VERSION "HNNBNNNYNNNNNNNNNNNNNNNNNNNNNNNNNNNNNNNNNN/4/%%%/4/'%**4NNN///"

NS_ :

BS_:

BU_: BAP_Tester ELV Gateway_Max HUD Kombi

BO_ 2331595982 Motor_64: 32 Gateway_Max
 SG_ PTUIPwrm_PrctPwrSysCur : 12|12@1+ (0.05,-102.3) [-102.30|102.35] "Unit_PerCent"  HUD,Kombi
 SG_ PTUIPwrm_PrctPwrElDrvCur : 24|12@1+ (0.05,-102.3) [-102.30|102.35] "Unit_PerCent"  HUD,Kombi
 SG_ PTHyDrA_StAcv : 36|2@1+ (1.0,0.0) [0.0|3] ""  HUD,Kombi
 SG_ PTUIPwrm_StAcv : 38|2@1+ (1.0,0.0) [0.0|3] ""  HUD,Kombi
 SG_ PTHyDrA_PrctUtilElDrv : 40|11@1+ (0.05,0) [0.00|102.25] "Unit_PerCent"  HUD,Kombi
 SG_ PTUIPwrm_PrctPwrGnrMaxUse : 51|11@1+ (0.05,-102.25) [-102.25|0.00] "Unit_PerCent"  HUD,Kombi
 SG_ PTUIPwrm_PrctPwrMotElMaxUse : 62|11@1+ (0.05,0) [0.00|102.25] "Unit_PerCent"  HUD,Kombi
 SG_ PTUIPwrm_FacPwrDyn : 73|7@1+ (0.01,0) [0.00|1.25] "Unit_None"  HUD,Kombi
 SG_ PTUIPwrm_PrctPwrMotMaxUse : 80|11@1+ (0.05,0) [0.00|102.25] "Unit_PerCent"  HUD,Kombi
 SG_ PTUIPwrm_PrctBoostAvl : 91|10@1+ (0.1,0) [0.0|102.1] "Unit_PerCent"  HUD,Kombi
 SG_ PTUIPwrm_PrctPwrElBoostCur : 101|10@1+ (0.1,0) [0.0|102.1] "Unit_PerCent"  HUD,Kombi
 SG_ PTUIPwrm_PrctPwrElBoostMaxUse : 111|10@1+ (0.1,0) [0.0|102.1] "Unit_PerCent"  HUD,Kombi
 SG_ PTUIPwrm_PwrElBoostNom : 121|10@1+ (1,0) [0|1021] "Unit_KiloWatt"  HUD,Kombi
 SG_ PTUIPwrm_PrctPwrEcoMaxUse : 142|11@1+ (0.05,0) [0.00|102.25] "Unit_PerCent"  Kombi
 SG_ PTUIPwrm_PrctPwrSysMaxUseTemp : 153|11@1+ (0.05,0) [0.00|102.25] "Unit_PerCent"  Kombi

BO_ 2589283946 Motor_65: 32 Gateway_Max
 SG_ PTUIPwrm_PwrMotElNom : 12|11@1+ (1,0) [0|2045] "Unit_KiloWatt"  HUD,Kombi
 SG_ PTUIPwrm_PwrGnrNom : 24|11@1+ (1,0) [0|2045] "Unit_KiloWatt"  HUD,Kombi
 SG_ PTUIPwrm_PwrSysMotNomDisp : 35|11@1+ (1,0) [0|2045] "Unit_KiloWatt"  Kombi

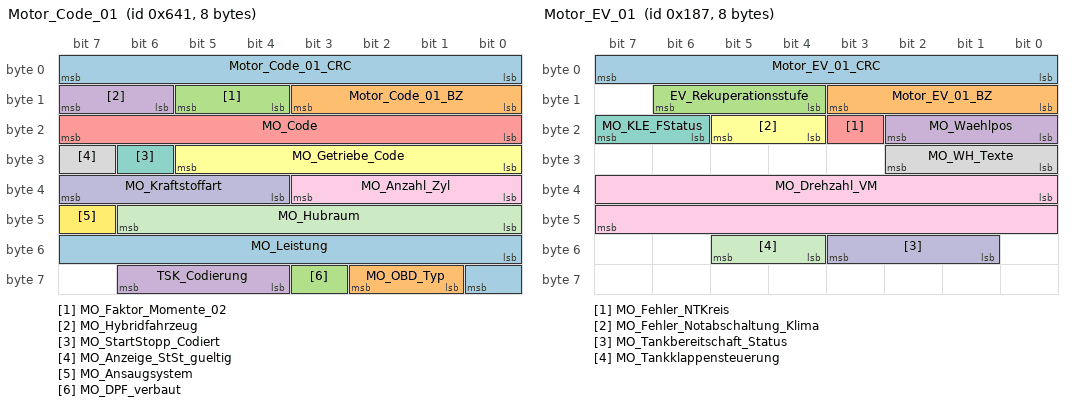
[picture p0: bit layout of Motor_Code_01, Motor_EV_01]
BO_ 1601 Motor_Code_01: 8 Gateway_Max
 SG_ Motor_Code_01_CRC : 0|8@1+ (1,0) [0|255] ""  Vector__XXX
 SG_ Motor_Code_01_BZ : 8|4@1+ (1,0) [0|15] ""  Vector__XXX
 SG_ MO_Faktor_Momente_02 : 12|2@1+ (1,0) [1|3] "Unit_NewtoMeter"  Vector__XXX
 SG_ MO_Hybridfahrzeug : 14|2@1+ (1.0,0.0) [0.0|3] ""  Kombi
 SG_ MO_Code : 16|8@1+ (1,0) [0|255] ""  Vector__XXX
 SG_ MO_Getriebe_Code : 24|6@1+ (1.0,0.0) [0.0|63] ""  Vector__XXX
 SG_ MO_StartStopp_Codiert : 30|1@1+ (1.0,0.0) [0.0|1] ""  Kombi
 SG_ MO_Anzeige_StSt_gueltig : 31|1@1+ (1.0,0.0) [0.0|1] ""  Kombi
 SG_ MO_Anzahl_Zyl : 32|4@1+ (1.0,0.0) [0.0|15] ""  Kombi
 SG_ MO_Kraftstoffart : 36|4@1+ (1.0,0.0) [0.0|15] ""  Kombi
 SG_ MO_Hubraum : 40|7@1+ (0.1,0) [0.0|12.7] "Unit_Liter"  Vector__XXX
 SG_ MO_Ansaugsystem : 47|1@1+ (1.0,0.0) [0.0|1] ""  Vector__XXX
 SG_ MO_Leistung : 48|9@1+ (1,0) [0|511] "Unit_KiloWatt"  Kombi
 SG_ MO_OBD_Typ : 57|2@1+ (1.0,0.0) [0.0|3] ""  Vector__XXX
 SG_ MO_DPF_verbaut : 59|1@1+ (1.0,0.0) [0.0|1] ""  Vector__XXX
 SG_ TSK_Codierung : 60|3@1+ (1.0,0.0) [0.0|7] ""  Vector__XXX

BO_ 391 Motor_EV_01: 8 Gateway_Max
 SG_ Motor_EV_01_CRC : 0|8@1+ (1,0) [0|255] ""  Vector__XXX
 SG_ Motor_EV_01_BZ : 8|4@1+ (1,0) [0|15] ""  Vector__XXX
 SG_ EV_Rekuperationsstufe : 12|3@1+ (1.0,0.0) [0.0|7] ""  Vector__XXX
 SG_ MO_Waehlpos : 16|3@1+ (1.0,0.0) [0.0|7] ""  Kombi
 SG_ MO_Fehler_NTKreis : 19|1@1+ (1.0,0.0) [0.0|1] ""  Vector__XXX
 SG_ MO_Fehler_Notabschaltung_Klima : 20|2@1+ (1.0,0.0) [0.0|3] ""  Vector__XXX
 SG_ MO_KLE_FStatus : 22|2@1+ (1.0,0.0) [0.0|3] ""  Vector__XXX
 SG_ MO_WH_Texte : 24|3@1+ (1.0,0.0) [0.0|7] ""  Vector__XXX
 SG_ MO_Drehzahl_VM : 32|16@1+ (0.25,0) [0.00|16383.00] "Unit_MinutInver"  Vector__XXX
 SG_ MO_Tankbereitschaft_Status : 49|3@1+ (1.0,0.0) [0.0|7] ""  Kombi
 SG_ MO_Tankklappensteuerung : 52|2@1+ (1.0,0.0) [0.0|3] ""  Vector__XXX

BO_ 813 Motor_Gas_01: 8 Gateway_Max
 SG_ MO_Fuellstand_LPG m1  : 0|10@1+ (0.125,0) [0.000|127.625] "Unit_Liter"  Kombi
 SG_ MO_CNG_LPG M  : 12|1@1+ (1.0,0.0) [0.0|1] ""  Kombi
 SG_ MO_CNG_Tankstopp m0  : 15|1@1+ (1.0,0.0) [0.0|1] ""  Kombi
 SG_ MO_LPG_Tankstopp m1  : 15|1@1+ (1.0,0.0) [0.0|1] ""  Kombi
 SG_ MO_AnzeigeGasbetrieb : 16|4@1+ (1.0,0.0) [0.0|15] ""  Kombi
 SG_ MO_akt_Betrieb : 20|1@1+ (1.0,0.0) [0.0|1] ""  Kombi
 SG_ MO_Erdgasqualitaet : 21|3@1+ (1.0,0.0) [0.0|7] ""  Kombi
 SG_ MO_Verbrauchsaequivalent : 24|8@1+ (0.008,0) [0.008|2.000] "Unit_None"  Kombi
 SG_ MO_Tankmasse_CNG m0  : 32|8@1+ (0.25,0) [0.25|63.50] "Unit_KiloGram"  Kombi
 SG_ MO_Tankvolumen_LPG m1  : 32|8@1+ (0.5,0) [0.5|127.0] "Unit_Liter"  Kombi
 SG_ MO_Fuellungsgrad_CNG m0  : 40|8@1+ (0.4,0) [0.0|101.2] "Unit_PerCent"  Kombi
 SG_ MO_Fuellungsgrad_LPG m1  : 40|8@1+ (0.4,0) [0.0|101.2] "Unit_PerCent"  Kombi
 SG_ MO_CNG_Ueberlauf m0  : 48|1@1+ (1.0,0.0) [0.0|1] ""  Kombi
 SG_ MO_LPG_Ueberlauf m1  : 48|1@1+ (1.0,0.0) [0.0|1] ""  Kombi
 SG_ MO_Verbrauch_CNG m0  : 49|15@1+ (1,0) [0|32767] "Unit_MilliGram"  Kombi
 SG_ MO_Verbrauch_LPG m1  : 49|15@1+ (1,0) [0|32767] "Unit_MicroLiter"  Kombi

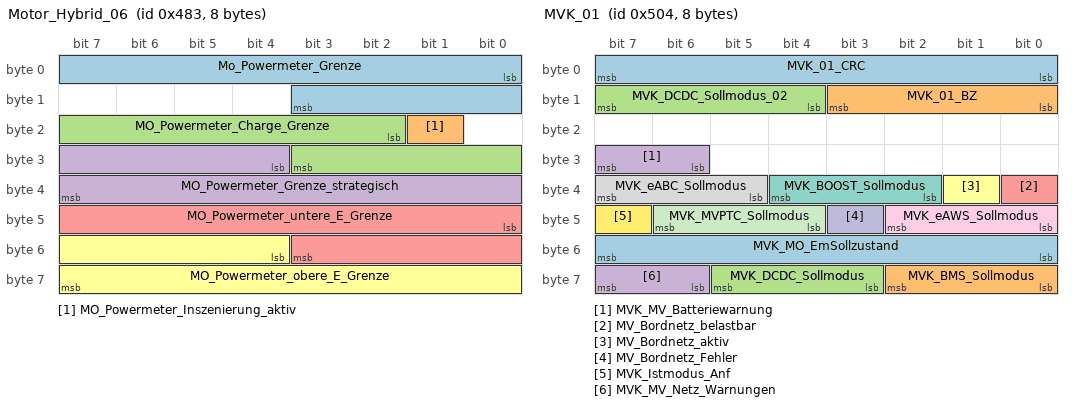
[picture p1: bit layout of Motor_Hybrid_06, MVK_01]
BO_ 1155 Motor_Hybrid_06: 8 Gateway_Max
 SG_ Mo_Powermeter_Grenze : 0|12@1+ (1,0) [0|4092] ""  Kombi
 SG_ MO_Powermeter_Inszenierung_aktiv : 17|1@1+ (1.0,0.0) [0.0|1] ""  Vector__XXX
 SG_ MO_Powermeter_Charge_Grenze : 18|10@1+ (1,0) [0|1021] "Unit_None"  Kombi
 SG_ MO_Powermeter_Grenze_strategisch : 28|12@1+ (1,0) [0|4093] "Unit_None"  Kombi
 SG_ MO_Powermeter_untere_E_Grenze : 40|12@1+ (1,0) [0|4093] "Unit_None"  Kombi
 SG_ MO_Powermeter_obere_E_Grenze : 52|12@1+ (1,0) [0|4093] "Unit_None"  Kombi

BO_ 1284 MVK_01: 8 Gateway_Max
 SG_ MVK_01_CRC : 0|8@1+ (1,0) [0|255] ""  Kombi
 SG_ MVK_01_BZ : 8|4@1+ (1,0) [0|15] ""  Kombi
 SG_ MVK_DCDC_Sollmodus_02 : 12|4@1+ (1.0,0.0) [0.0|15] ""  Vector__XXX
 SG_ MVK_MV_Batteriewarnung : 30|2@1+ (1.0,0.0) [0.0|3] ""  Kombi
 SG_ MV_Bordnetz_belastbar : 32|1@1+ (1.0,0.0) [0.0|1] ""  Vector__XXX
 SG_ MV_Bordnetz_aktiv : 33|1@1+ (1.0,0.0) [0.0|1] ""  Vector__XXX
 SG_ MVK_BOOST_Sollmodus : 34|3@1+ (1.0,0.0) [0.0|7] ""  Vector__XXX
 SG_ MVK_eABC_Sollmodus : 37|3@1+ (1.0,0.0) [0.0|7] ""  Vector__XXX
 SG_ MVK_eAWS_Sollmodus : 40|3@1+ (1.0,0.0) [0.0|7] ""  Vector__XXX
 SG_ MV_Bordnetz_Fehler : 43|1@1+ (1.0,0.0) [0.0|1] ""  Vector__XXX
 SG_ MVK_MVPTC_Sollmodus : 44|3@1+ (1.0,0.0) [0.0|7] ""  Vector__XXX
 SG_ MVK_Istmodus_Anf : 47|1@1+ (1.0,0.0) [0.0|1] ""  Vector__XXX
 SG_ MVK_MO_EmSollzustand : 48|8@1+ (1.0,0.0) [0.0|255] ""  Vector__XXX
 SG_ MVK_BMS_Sollmodus : 56|3@1+ (1.0,0.0) [0.0|7] ""  Vector__XXX
 SG_ MVK_DCDC_Sollmodus : 59|3@1+ (1.0,0.0) [0.0|7] ""  Vector__XXX
 SG_ MVK_MV_Netz_Warnungen : 62|2@1+ (1.0,0.0) [0.0|3] ""  Kombi

BO_ 2583737729 NAD_AuthTime_SSN_Req: 8 Gateway_Max
 SG_ NAD_AuthTime_SSN_Req_Data : 0|64@1+ (1.0,0.0) [0.0|18446744073709551615] ""  Kombi

BO_ 2583868801 NAD_AuthTime_SSN_Resp: 8 Kombi
 SG_ NAD_AuthTime_SSN_Resp_Data : 0|64@1+ (1.0,0.0) [0.0|18446744073709551615] ""  Gateway_Max

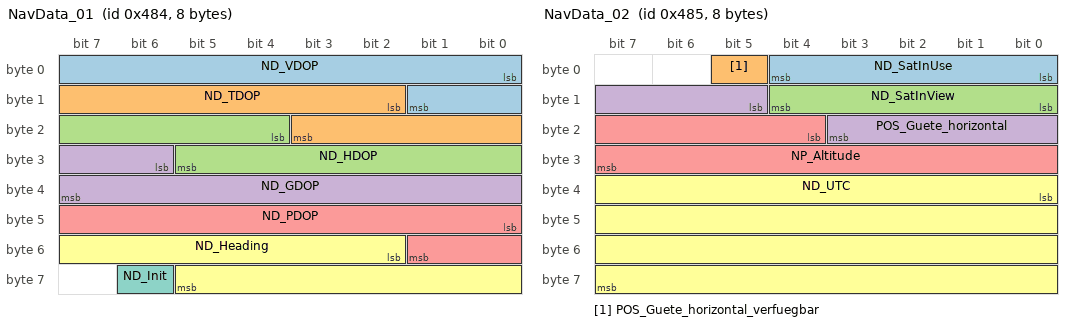
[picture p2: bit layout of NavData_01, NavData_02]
BO_ 1156 NavData_01: 8 Gateway_Max
 SG_ ND_VDOP : 0|10@1+ (0.025,0) [0.000|25.000] ""  Vector__XXX
 SG_ ND_TDOP : 10|10@1+ (0.025,0) [0.000|25.000] ""  Vector__XXX
 SG_ ND_HDOP : 20|10@1+ (0.025,0) [0.000|25.000] ""  Vector__XXX
 SG_ ND_GDOP : 30|10@1+ (0.025,0) [0.000|25.000] ""  Vector__XXX
 SG_ ND_PDOP : 40|10@1+ (0.025,0) [0.000|25.000] ""  Vector__XXX
 SG_ ND_Heading : 50|12@1+ (0.1,0) [0.0|359.9] "Unit_DegreOfArc"  Vector__XXX
 SG_ ND_Init : 62|1@1+ (1.0,0.0) [0.0|1] ""  Vector__XXX

BO_ 1157 NavData_02: 8 Gateway_Max
 SG_ ND_SatInUse : 0|5@1+ (1,0) [0|29] ""  Vector__XXX
 SG_ POS_Guete_horizontal_verfuegbar : 5|1@1+ (1.0,0.0) [0.0|1] ""  Vector__XXX
 SG_ ND_SatInView : 8|5@1+ (1,0) [0|29] ""  Vector__XXX
 SG_ POS_Guete_horizontal : 13|7@1+ (2,0) [0|246] "Unit_Meter"  Vector__XXX
 SG_ NP_Altitude : 20|12@1+ (2,-500) [-500|7686] "Unit_Meter"  Vector__XXX
 SG_ ND_UTC : 32|32@1+ (1,0) [0|4294967293] "Unit_Secon"  Vector__XXX

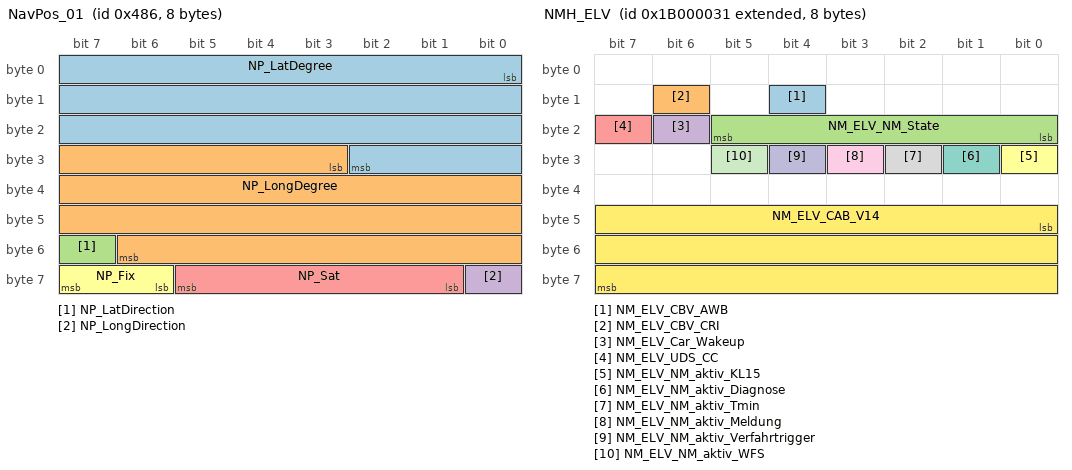
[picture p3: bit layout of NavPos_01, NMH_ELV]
BO_ 1158 NavPos_01: 8 Gateway_Max
 SG_ NP_LatDegree : 0|27@1+ (0.000001,0) [0.000000|90.000000] "Unit_DegreOfArc"  Vector__XXX
 SG_ NP_LongDegree : 27|28@1+ (0.000001,0) [0.000000|180.000000] "Unit_DegreOfArc"  Vector__XXX
 SG_ NP_LatDirection : 55|1@1+ (1.0,0.0) [0.0|1] ""  Vector__XXX
 SG_ NP_LongDirection : 56|1@1+ (1.0,0.0) [0.0|1] ""  Vector__XXX
 SG_ NP_Sat : 57|5@1+ (1,0) [0|29] ""  Vector__XXX
 SG_ NP_Fix : 62|2@1+ (1.0,0.0) [0.0|3] ""  Vector__XXX

BO_ 2600468529 NMH_ELV: 8 ELV
 SG_ NM_ELV_CBV_AWB : 12|1@1+ (1.0,0.0) [0.0|1] ""  Gateway_Max
 SG_ NM_ELV_CBV_CRI : 14|1@1+ (1.0,0.0) [0.0|1] ""  Gateway_Max
 SG_ NM_ELV_NM_State : 16|6@1+ (1.0,0.0) [0.0|63] ""  HUD,Kombi
 SG_ NM_ELV_Car_Wakeup : 22|1@1+ (1.0,0.0) [0.0|1] ""  Gateway_Max
 SG_ NM_ELV_UDS_CC : 23|1@1+ (1.0,0.0) [0.0|1] ""  Vector__XXX
 SG_ NM_ELV_NM_aktiv_KL15 : 24|1@1+ (1.0,0.0) [0.0|1] ""  Vector__XXX
 SG_ NM_ELV_NM_aktiv_Diagnose : 25|1@1+ (1.0,0.0) [0.0|1] ""  Vector__XXX
 SG_ NM_ELV_NM_aktiv_Tmin : 26|1@1+ (1.0,0.0) [0.0|1] ""  Vector__XXX
 SG_ NM_ELV_NM_aktiv_Meldung : 27|1@1+ (1.0,0.0) [0.0|1] ""  Vector__XXX
 SG_ NM_ELV_NM_aktiv_Verfahrtrigger : 28|1@1+ (1.0,0.0) [0.0|1] ""  Vector__XXX
 SG_ NM_ELV_NM_aktiv_WFS : 29|1@1+ (1.0,0.0) [0.0|1] ""  Vector__XXX
 SG_ NM_ELV_CAB_V14 : 40|24@1+ (1.0,0.0) [0.0|16777215] ""  Gateway_Max

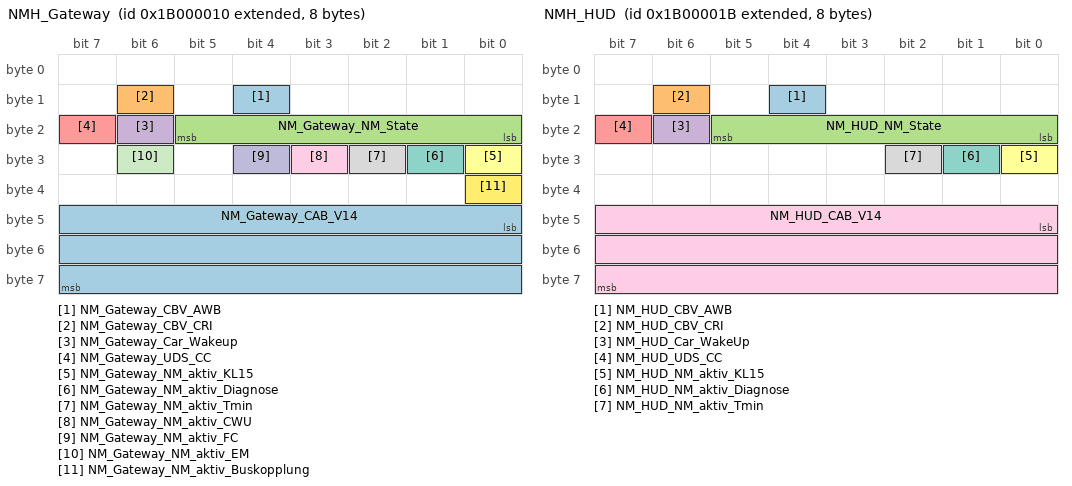
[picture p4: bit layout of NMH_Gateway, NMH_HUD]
BO_ 2600468496 NMH_Gateway: 8 Gateway_Max
 SG_ NM_Gateway_CBV_AWB : 12|1@1+ (1.0,0.0) [0.0|1] ""  Vector__XXX
 SG_ NM_Gateway_CBV_CRI : 14|1@1+ (1.0,0.0) [0.0|1] ""  Vector__XXX
 SG_ NM_Gateway_NM_State : 16|6@1+ (1.0,0.0) [0.0|63] ""  ELV,HUD,Kombi
 SG_ NM_Gateway_Car_Wakeup : 22|1@1+ (1.0,0.0) [0.0|1] ""  Vector__XXX
 SG_ NM_Gateway_UDS_CC : 23|1@1+ (1.0,0.0) [0.0|1] ""  Vector__XXX
 SG_ NM_Gateway_NM_aktiv_KL15 : 24|1@1+ (1.0,0.0) [0.0|1] ""  Vector__XXX
 SG_ NM_Gateway_NM_aktiv_Diagnose : 25|1@1+ (1.0,0.0) [0.0|1] ""  Vector__XXX
 SG_ NM_Gateway_NM_aktiv_Tmin : 26|1@1+ (1.0,0.0) [0.0|1] ""  Vector__XXX
 SG_ NM_Gateway_NM_aktiv_CWU : 27|1@1+ (1.0,0.0) [0.0|1] ""  Vector__XXX
 SG_ NM_Gateway_NM_aktiv_FC : 28|1@1+ (1.0,0.0) [0.0|1] ""  Vector__XXX
 SG_ NM_Gateway_NM_aktiv_EM : 30|1@1+ (1.0,0.0) [0.0|1] ""  Vector__XXX
 SG_ NM_Gateway_NM_aktiv_Buskopplung : 32|1@1+ (1.0,0.0) [0.0|1] ""  Vector__XXX
 SG_ NM_Gateway_CAB_V14 : 40|24@1+ (1.0,0.0) [0.0|16777215] ""  Vector__XXX

BO_ 2600468507 NMH_HUD: 8 HUD
 SG_ NM_HUD_CBV_AWB : 12|1@1+ (1.0,0.0) [0.0|1] ""  Gateway_Max
 SG_ NM_HUD_CBV_CRI : 14|1@1+ (1.0,0.0) [0.0|1] ""  Gateway_Max
 SG_ NM_HUD_NM_State : 16|6@1+ (1.0,0.0) [0.0|63] ""  ELV,Kombi
 SG_ NM_HUD_Car_WakeUp : 22|1@1+ (1.0,0.0) [0.0|1] ""  Gateway_Max
 SG_ NM_HUD_UDS_CC : 23|1@1+ (1.0,0.0) [0.0|1] ""  Vector__XXX
 SG_ NM_HUD_NM_aktiv_KL15 : 24|1@1+ (1.0,0.0) [0.0|1] ""  Vector__XXX
 SG_ NM_HUD_NM_aktiv_Diagnose : 25|1@1+ (1.0,0.0) [0.0|1] ""  Vector__XXX
 SG_ NM_HUD_NM_aktiv_Tmin : 26|1@1+ (1.0,0.0) [0.0|1] ""  Vector__XXX
 SG_ NM_HUD_CAB_V14 : 40|24@1+ (1.0,0.0) [0.0|16777215] ""  Gateway_Max

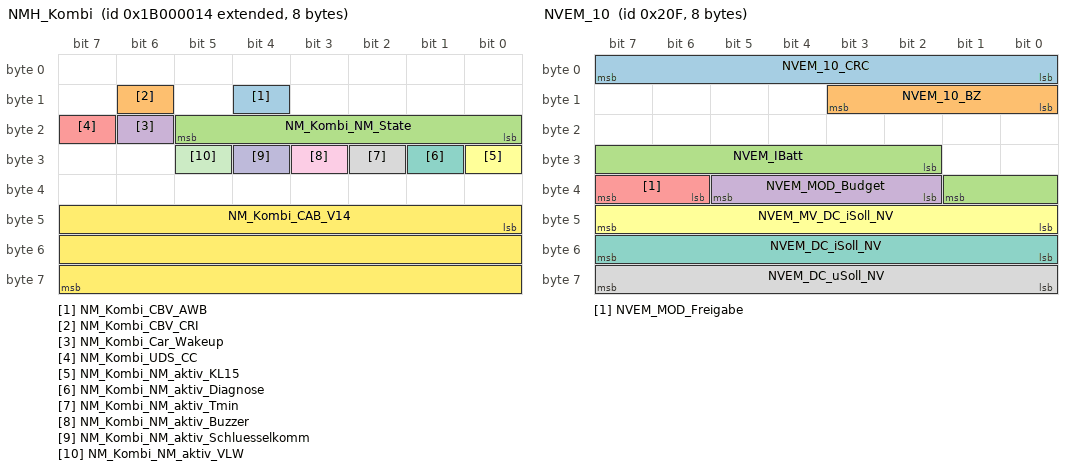
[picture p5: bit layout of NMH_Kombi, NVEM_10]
BO_ 2600468500 NMH_Kombi: 8 Kombi
 SG_ NM_Kombi_CBV_AWB : 12|1@1+ (1.0,0.0) [0.0|1] ""  Gateway_Max
 SG_ NM_Kombi_CBV_CRI : 14|1@1+ (1.0,0.0) [0.0|1] ""  Gateway_Max
 SG_ NM_Kombi_NM_State : 16|6@1+ (1.0,0.0) [0.0|63] ""  ELV,HUD
 SG_ NM_Kombi_Car_Wakeup : 22|1@1+ (1.0,0.0) [0.0|1] ""  Gateway_Max
 SG_ NM_Kombi_UDS_CC : 23|1@1+ (1.0,0.0) [0.0|1] ""  Vector__XXX
 SG_ NM_Kombi_NM_aktiv_KL15 : 24|1@1+ (1.0,0.0) [0.0|1] ""  Vector__XXX
 SG_ NM_Kombi_NM_aktiv_Diagnose : 25|1@1+ (1.0,0.0) [0.0|1] ""  Vector__XXX
 SG_ NM_Kombi_NM_aktiv_Tmin : 26|1@1+ (1.0,0.0) [0.0|1] ""  Vector__XXX
 SG_ NM_Kombi_NM_aktiv_Buzzer : 27|1@1+ (1.0,0.0) [0.0|1] ""  Vector__XXX
 SG_ NM_Kombi_NM_aktiv_Schluesselkomm : 28|1@1+ (1.0,0.0) [0.0|1] ""  Vector__XXX
 SG_ NM_Kombi_NM_aktiv_VLW : 29|1@1+ (1.0,0.0) [0.0|1] ""  Vector__XXX
 SG_ NM_Kombi_CAB_V14 : 40|24@1+ (1.0,0.0) [0.0|16777215] ""  Gateway_Max

BO_ 527 NVEM_10: 8 Gateway_Max
 SG_ NVEM_10_CRC : 0|8@1+ (1,0) [0|255] ""  Vector__XXX
 SG_ NVEM_10_BZ : 8|4@1+ (1,0) [0|15] ""  Vector__XXX
 SG_ NVEM_IBatt : 26|8@1+ (1,-127) [-127|127] "Unit_Amper"  Vector__XXX
 SG_ NVEM_MOD_Budget : 34|4@1+ (10,0) [0|100] "Unit_PerCent"  Vector__XXX
 SG_ NVEM_MOD_Freigabe : 38|2@1+ (1.0,0.0) [0.0|3] ""  Vector__XXX
 SG_ NVEM_MV_DC_iSoll_NV : 40|8@1+ (1,-253) [-253|0] "Unit_Amper"  Vector__XXX
 SG_ NVEM_DC_iSoll_NV : 48|8@1+ (1,-253) [-253|0] "Unit_Amper"  Vector__XXX
 SG_ NVEM_DC_uSoll_NV : 56|8@1+ (0.025,10.6) [10.600|16.000] "Unit_Volt"  Vector__XXX

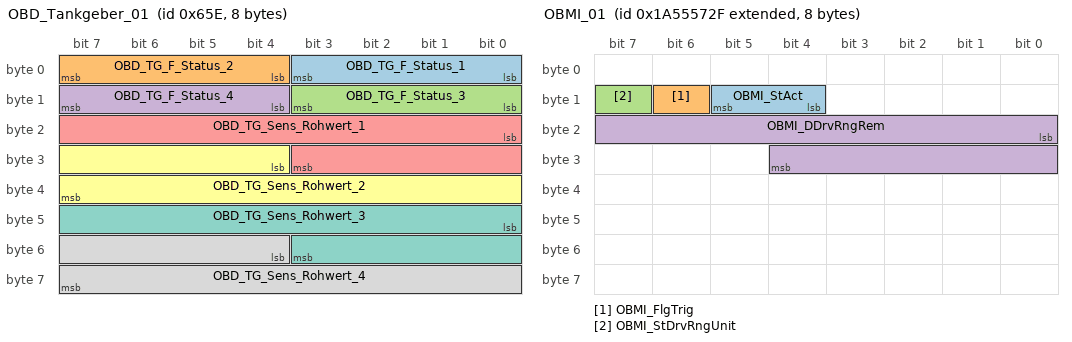
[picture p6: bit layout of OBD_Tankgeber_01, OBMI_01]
BO_ 1630 OBD_Tankgeber_01: 8 Kombi
 SG_ OBD_TG_F_Status_1 : 0|4@1+ (1.0,0.0) [0.0|15] ""  Gateway_Max
 SG_ OBD_TG_F_Status_2 : 4|4@1+ (1.0,0.0) [0.0|15] ""  Gateway_Max
 SG_ OBD_TG_F_Status_3 : 8|4@1+ (1.0,0.0) [0.0|15] ""  Gateway_Max
 SG_ OBD_TG_F_Status_4 : 12|4@1+ (1.0,0.0) [0.0|15] ""  Gateway_Max
 SG_ OBD_TG_Sens_Rohwert_1 : 16|12@1+ (0.5,0) [0.0|2047.5] "Unit_Ohm"  Gateway_Max
 SG_ OBD_TG_Sens_Rohwert_2 : 28|12@1+ (0.5,0) [0.0|2047.5] "Unit_Ohm"  Gateway_Max
 SG_ OBD_TG_Sens_Rohwert_3 : 40|12@1+ (0.5,0) [0.0|2047.5] "Unit_Ohm"  Gateway_Max
 SG_ OBD_TG_Sens_Rohwert_4 : 52|12@1+ (0.5,0) [0.0|2047.5] "Unit_Ohm"  Gateway_Max

BO_ 2621440561 OBDC_ELV_Req_FD: 64 Gateway_Max
 SG_ OBDC_ELV_Req_FD_Data : 0|512@1+ (1.0,0.0) [0.0|13407807929942597099574024998205846127479365820592393377723561443721764030073546976801874298166903427690031858186486050853753882811946569946433649006084095] ""  ELV

BO_ 2621571633 OBDC_ELV_Resp_FD: 64 ELV
 SG_ OBDC_ELV_Resp_FD_Data : 0|512@1+ (1.0,0.0) [0.0|13407807929942597099574024998205846127479365820592393377723561443721764030073546976801874298166903427690031858186486050853753882811946569946433649006084095] ""  Gateway_Max

BO_ 2549940736 OBDC_Funktionaler_Req_All: 8 Gateway_Max
 SG_ OBDC_Funktionaler_Req_All_Data : 0|64@1+ (1.0,0.0) [0.0|18446744073709551615] ""  Vector__XXX

BO_ 2621506048 OBDC_Funktionaler_Req_All_FD: 64 Gateway_Max
 SG_ OBDC_Funktion_Req_All_FD_Data : 0|512@1+ (1.0,0.0) [0.0|13407807929942597099574024998205846127479365820592393377723561443721764030073546976801874298166903427690031858186486050853753882811946569946433649006084095] ""  ELV,HUD,Kombi

BO_ 2621440539 OBDC_HUD_Req_FD: 64 Gateway_Max
 SG_ OBDC_HUD_Req_FD_Data : 0|512@1+ (1.0,0.0) [0.0|13407807929942597099574024998205846127479365820592393377723561443721764030073546976801874298166903427690031858186486050853753882811946569946433649006084095] ""  HUD

BO_ 2621571611 OBDC_HUD_Resp_FD: 64 HUD
 SG_ OBDC_HUD_Resp_FD_Data : 0|512@1+ (1.0,0.0) [0.0|13407807929942597099574024998205846127479365820592393377723561443721764030073546976801874298166903427690031858186486050853753882811946569946433649006084095] ""  Gateway_Max

BO_ 2621440532 OBDC_Kombi_Req_FD: 64 Gateway_Max
 SG_ OBDC_Kombi_Req_FD_Data : 0|512@1+ (1.0,0.0) [0.0|13407807929942597099574024998205846127479365820592393377723561443721764030073546976801874298166903427690031858186486050853753882811946569946433649006084095] ""  Kombi

BO_ 2621571604 OBDC_Kombi_Resp_FD: 64 Kombi
 SG_ OBDC_Kombi_Resp_FD_Data : 0|512@1+ (1.0,0.0) [0.0|13407807929942597099574024998205846127479365820592393377723561443721764030073546976801874298166903427690031858186486050853753882811946569946433649006084095] ""  Gateway_Max

BO_ 2549875364 OBDC_LSH_Req: 8 Gateway_Max
 SG_ OBDC_LSH_Req_Data : 0|64@1+ (1.0,0.0) [0.0|18446744073709551615] ""  Vector__XXX

BO_ 2550006436 OBDC_LSH_Resp: 8 Vector__XXX
 SG_ OBDC_LSH_Resp_Data : 0|64@1+ (1.0,0.0) [0.0|18446744073709551615] ""  Gateway_Max

BO_ 2621440556 OBDC_MFG_Req_FD: 64 Gateway_Max
 SG_ OBDC_MFG_Req_FD_Data : 0|512@1+ (1.0,0.0) [0.0|13407807929942597099574024998205846127479365820592393377723561443721764030073546976801874298166903427690031858186486050853753882811946569946433649006084095] ""  Vector__XXX

BO_ 2621571628 OBDC_MFG_Resp_FD: 64 Vector__XXX
 SG_ OBDC_MFG_Resp_FD_Data : 0|512@1+ (1.0,0.0) [0.0|13407807929942597099574024998205846127479365820592393377723561443721764030073546976801874298166903427690031858186486050853753882811946569946433649006084095] ""  Gateway_Max

BO_ 2549903375 OBDC_SSN_ABT_2_Req: 8 Gateway_Max
 SG_ OBDC_SSN_ABT_2_Req_Data : 0|64@1+ (1.0,0.0) [0.0|18446744073709551615] ""  Vector__XXX

BO_ 2550034447 OBDC_SSN_ABT_2_Resp: 8 Vector__XXX
 SG_ OBDC_SSN_ABT_2_Resp_Data : 0|64@1+ (1.0,0.0) [0.0|18446744073709551615] ""  Gateway_Max

BO_ 2621440625 OBDC_TCO_Req_FD: 64 Gateway_Max
 SG_ OBDC_TCO_Req_FD_Data : 0|512@1+ (1.0,0.0) [0.0|13407807929942597099574024998205846127479365820592393377723561443721764030073546976801874298166903427690031858186486050853753882811946569946433649006084095] ""  Vector__XXX

BO_ 2621571697 OBDC_TCO_Resp_FD: 64 Vector__XXX
 SG_ OBDC_TCO_Resp_FD_Data : 0|512@1+ (1.0,0.0) [0.0|13407807929942597099574024998205846127479365820592393377723561443721764030073546976801874298166903427690031858186486050853753882811946569946433649006084095] ""  Gateway_Max

BO_ 2550399502 OBDC_TRE_2_Req: 8 Gateway_Max
 SG_ OBDC_TRE_2_Req_Data : 0|64@1+ (1.0,0.0) [0.0|18446744073709551615] ""  Vector__XXX

BO_ 2550530574 OBDC_TRE_2_Resp: 8 Vector__XXX
 SG_ OBDC_TRE_2_Resp_Data : 0|64@1+ (1.0,0.0) [0.0|18446744073709551615] ""  Gateway_Max

BO_ 2589284143 OBMI_01: 8 Gateway_Max
 SG_ OBMI_StAct : 12|2@1+ (1.0,0.0) [0.0|3] ""  Kombi
 SG_ OBMI_FlgTrig : 14|1@1+ (1.0,0.0) [0.0|1] ""  Kombi
 SG_ OBMI_StDrvRngUnit : 15|1@1+ (1.0,0.0) [0.0|1] ""  Kombi
 SG_ OBMI_DDrvRngRem : 16|13@1+ (1,0) [0|8189] "Unit_None"  Kombi

BO_ 2589283656 ORU_01: 8 Gateway_Max
 SG_ ORU_Warnung : 58|2@1+ (1.0,0.0) [0.0|3] ""  Vector__XXX
 SG_ ORU_Status : 61|3@1+ (1.0,0.0) [0.0|7] ""  Vector__XXX

BO_ 1175 Parkhilfe_01: 8 Gateway_Max
 SG_ PH_Visualisierung : 0|3@1+ (1.0,0.0) [0.0|7] ""  Vector__XXX
 SG_ PDC_Tonausgabe_Front : 4|4@1+ (1.0,0.0) [0.0|15] ""  Vector__XXX
 SG_ PDC_Tonausgabe_Heck : 8|4@1+ (1.0,0.0) [0.0|15] ""  Vector__XXX
 SG_ PH_nachtr_Stopp_Anf : 12|1@1+ (1.0,0.0) [0.0|1] ""  Vector__XXX
 SG_ PH_Abschaltursache : 13|3@1+ (1.0,0.0) [0.0|7] ""  Vector__XXX
 SG_ PH_Opt_Anzeige_V_ein : 16|1@1+ (1.0,0.0) [0.0|1] ""  Vector__XXX
 SG_ PH_Opt_Anzeige_H_ein : 17|1@1+ (1.0,0.0) [0.0|1] ""  Vector__XXX
 SG_ PH_Opt_Anz_V_Hindernis : 18|1@1+ (1.0,0.0) [0.0|1] ""  Vector__XXX
 SG_ PH_Opt_Anz_H_Hindernis : 19|1@1+ (1.0,0.0) [0.0|1] ""  Vector__XXX
 SG_ PH_Tongeber_V_aktiv : 20|1@1+ (1.0,0.0) [0.0|1] ""  Vector__XXX
 SG_ PH_Tongeber_H_aktiv : 21|1@1+ (1.0,0.0) [0.0|1] ""  Vector__XXX
 SG_ PH_Tongeber_mute : 22|1@1+ (1.0,0.0) [0.0|1] ""  Vector__XXX
 SG_ PH_Anf_Audioabsenkung : 23|1@1+ (1.0,0.0) [0.0|1] ""  Vector__XXX
 SG_ PH_Tongeber_H_verfuegbar : 24|1@1+ (1.0,0.0) [0.0|1] ""  Vector__XXX
 SG_ PLA_Anf_Aufschaltung_RVC : 25|1@1+ (1.0,0.0) [0.0|1] ""  Vector__XXX
 SG_ PH_Taster : 28|2@1+ (1.0,0.0) [0.0|3] ""  Vector__XXX
 SG_ PH_Anf_Verdeck : 30|2@1+ (1.0,0.0) [0.0|3] ""  Vector__XXX
 SG_ PH_Frequenz_hinten : 32|4@1+ (1,0) [0|15] ""  Vector__XXX
 SG_ PH_Lautstaerke_hinten : 36|4@1+ (1,0) [0|15] ""  Vector__XXX
 SG_ PH_Frequenz_vorn : 40|4@1+ (1,0) [0|15] ""  Vector__XXX
 SG_ PH_Lautstaerke_vorn : 44|4@1+ (1,0) [0|15] ""  Vector__XXX
 SG_ PH_StartStopp_Info : 49|2@1+ (1.0,0.0) [0.0|3] ""  Vector__XXX
 SG_ PH_Stoermeldung : 52|4@1+ (1.0,0.0) [0.0|15] ""  Kombi
 SG_ PH_defekt : 56|1@1+ (1.0,0.0) [0.0|1] ""  Vector__XXX
 SG_ PH_gestoert : 57|1@1+ (1.0,0.0) [0.0|1] ""  Vector__XXX
 SG_ PH_Systemzustand : 58|3@1+ (1.0,0.0) [0.0|7] ""  Vector__XXX
 SG_ PH_Display_Kundenwunsch : 61|2@1+ (1.0,0.0) [0.0|3] ""  Vector__XXX

BO_ 1355 Parkhilfe_04: 8 Gateway_Max
 SG_ RBFMA_PaCo_BrakeIntervention : 0|3@1+ (1.0,0.0) [0.0|7] ""  Vector__XXX
 SG_ RBFMA_PaCo_MainState : 3|3@1+ (1.0,0.0) [0.0|7] ""  Vector__XXX
 SG_ RAB_PaCo_FunctionState : 6|3@1+ (1.0,0.0) [0.0|7] ""  Vector__XXX
 SG_ RBF_Anf_Meldungen : 9|3@1+ (1.0,0.0) [0.0|7] ""  Vector__XXX
 SG_ PH_Verschmutzungsmeldung : 12|4@1+ (1.0,0.0) [0.0|15] ""  Kombi
 SG_ PH_Aufschaltursache : 16|5@1+ (1.0,0.0) [0.0|31] ""  Vector__XXX
 SG_ PH_Ton_Ausgabe : 21|3@1+ (1.0,0.0) [0.0|7] ""  Vector__XXX
 SG_ PH_Ton_Pausenlaenge : 24|8@1+ (1.0,0.0) [0.0|255] ""  Vector__XXX
 SG_ APSOPS_PaCo_ObstacleDetectRear : 32|3@1+ (1.0,0.0) [0.0|7] ""  Vector__XXX
 SG_ APSOPS_PaCo_ObstacleDetectFront : 35|3@1+ (1.0,0.0) [0.0|7] ""  Vector__XXX
 SG_ APSOPS_PaCo_Button : 38|2@1+ (1.0,0.0) [0.0|3] ""  Vector__XXX
 SG_ APSOPS_PaCo_MainState : 40|3@1+ (1.0,0.0) [0.0|7] ""  Vector__XXX
 SG_ APSOPS_PaCo_FunctionState : 43|3@1+ (1.0,0.0) [0.0|7] ""  Vector__XXX
 SG_ APSOPS_PaCo_ApproachingRear : 46|1@1+ (1.0,0.0) [0.0|1] ""  Vector__XXX
 SG_ APSOPS_PaCo_ApproachingFront : 47|1@1+ (1.0,0.0) [0.0|1] ""  Vector__XXX
 SG_ APS_PaCo_WarningTones : 48|1@1+ (1.0,0.0) [0.0|1] ""  Vector__XXX
 SG_ PH_Ton_Richtung : 49|3@1+ (1.0,0.0) [0.0|7] ""  Vector__XXX
 SG_ PH_Ton_Lautstaerke : 52|3@1+ (1.0,0.0) [0.0|7] ""  Vector__XXX
 SG_ PH_WAH_Meldung : 55|3@1+ (1.0,0.0) [0.0|7] ""  Vector__XXX
 SG_ RBF_PaCo_Anf_Meldungen : 58|3@1+ (1.0,0.0) [0.0|7] ""  Vector__XXX
 SG_ RBF_PMO_Bereich_erkannt : 61|1@1+ (1.0,0.0) [0.0|1] ""  Vector__XXX

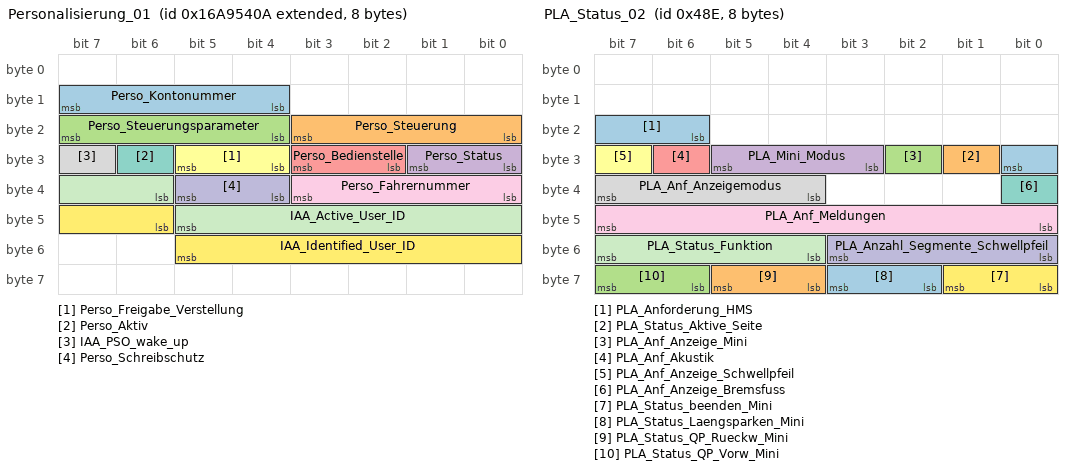
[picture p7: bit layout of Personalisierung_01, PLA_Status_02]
BO_ 2527679498 Personalisierung_01: 8 Gateway_Max
 SG_ Perso_Kontonummer : 12|4@1+ (1.0,0.0) [0.0|15] ""  HUD,Kombi
 SG_ Perso_Steuerung : 16|4@1+ (1.0,0.0) [0.0|15] ""  HUD,Kombi
 SG_ Perso_Steuerungsparameter : 20|4@1+ (1.0,0.0) [0.0|15] ""  HUD,Kombi
 SG_ Perso_Status : 24|2@1+ (1.0,0.0) [0.0|3] ""  HUD,Kombi
 SG_ Perso_Bedienstelle : 26|2@1+ (1.0,0.0) [0.0|3] ""  Vector__XXX
 SG_ Perso_Freigabe_Verstellung : 28|2@1+ (1.0,0.0) [0.0|3] ""  Vector__XXX
 SG_ Perso_Aktiv : 30|1@1+ (1.0,0.0) [0.0|1] ""  Vector__XXX
 SG_ IAA_PSO_wake_up : 31|1@1+ (1.0,0.0) [0.0|1] ""  Vector__XXX
 SG_ Perso_Fahrernummer : 32|4@1+ (1.0,0.0) [0.0|15] ""  Vector__XXX
 SG_ Perso_Schreibschutz : 36|2@1+ (1.0,0.0) [0.0|3] ""  Vector__XXX
 SG_ IAA_Active_User_ID : 38|8@1+ (1,0) [0|255] "Unit_None"  Vector__XXX
 SG_ IAA_Identified_User_ID : 46|8@1+ (1,0) [0|255] "Unit_None"  Vector__XXX

BO_ 1166 PLA_Status_02: 8 Gateway_Max
 SG_ PLA_Anforderung_HMS : 22|3@1+ (1.0,0.0) [0.0|7] ""  Vector__XXX
 SG_ PLA_Status_Aktive_Seite : 25|1@1+ (1.0,0.0) [0.0|1] ""  Kombi
 SG_ PLA_Anf_Anzeige_Mini : 26|1@1+ (1.0,0.0) [0.0|1] ""  Kombi
 SG_ PLA_Mini_Modus : 27|3@1+ (1.0,0.0) [0.0|7] ""  Kombi
 SG_ PLA_Anf_Akustik : 30|1@1+ (1.0,0.0) [0.0|1] ""  Kombi
 SG_ PLA_Anf_Anzeige_Schwellpfeil : 31|1@1+ (1.0,0.0) [0.0|1] ""  Kombi
 SG_ PLA_Anf_Anzeige_Bremsfuss : 32|1@1+ (1.0,0.0) [0.0|1] ""  Kombi
 SG_ PLA_Anf_Anzeigemodus : 36|4@1+ (1.0,0.0) [0.0|15] ""  Kombi
 SG_ PLA_Anf_Meldungen : 40|8@1+ (1.0,0.0) [0.0|255] ""  Kombi
 SG_ PLA_Anzahl_Segmente_Schwellpfeil : 48|4@1+ (1,0) [0|15] "Unit_None"  Vector__XXX
 SG_ PLA_Status_Funktion : 52|4@1+ (1.0,0.0) [0.0|15] ""  Kombi
 SG_ PLA_Status_beenden_Mini : 56|2@1+ (1.0,0.0) [0.0|3] ""  Vector__XXX
 SG_ PLA_Status_Laengsparken_Mini : 58|2@1+ (1.0,0.0) [0.0|3] ""  Vector__XXX
 SG_ PLA_Status_QP_Rueckw_Mini : 60|2@1+ (1.0,0.0) [0.0|3] ""  Vector__XXX
 SG_ PLA_Status_QP_Vorw_Mini : 62|2@1+ (1.0,0.0) [0.0|3] ""  Vector__XXX

BO_ 319 PreCrash_02: 8 Gateway_Max
 SG_ PreCrash_Charisma_FahrPr : 12|4@1+ (1.0,0.0) [0.0|15] ""  Vector__XXX
 SG_ PreCrash_Charisma_Status : 16|2@1+ (1.0,0.0) [0.0|3] ""  Vector__XXX
 SG_ PreCrash_Schiebedach_schliessen : 18|1@1+ (1.0,0.0) [0.0|1] ""  Vector__XXX
 SG_ PreCrash_Fenster_schliessen : 19|1@1+ (1.0,0.0) [0.0|1] ""  Vector__XXX
 SG_ PreCrash_Blinken : 20|3@1+ (1.0,0.0) [0.0|7] ""  Vector__XXX
 SG_ SC_PreSense_FCWP : 23|1@1+ (1.0,0.0) [0.0|1] ""  Vector__XXX
 SG_ PreCrash_Tueren_Verriegeln : 24|1@1+ (1.0,0.0) [0.0|1] ""  Vector__XXX
 SG_ PreCrash_FS_Laengsverstellung : 25|1@1+ (1.0,0.0) [0.0|1] ""  Vector__XXX
 SG_ PreCrash_Anforderung_AFR : 26|3@1+ (1.0,0.0) [0.0|7] ""  Vector__XXX
 SG_ SC_PreCrash_LED : 29|2@1+ (1.0,0.0) [0.0|3] ""  Vector__XXX
 SG_ PreCrash_FS_Pneumatik_ansteuern : 31|1@1+ (1.0,0.0) [0.0|1] ""  Vector__XXX
 SG_ PreCrash_BFS_Pneumatik_ansteuern : 32|1@1+ (1.0,0.0) [0.0|1] ""  Vector__XXX
 SG_ PreCrash_Fo_Pneumatik_ansteuern : 33|1@1+ (1.0,0.0) [0.0|1] ""  Vector__XXX
 SG_ PreCrash_FS_Sitzlehne_verfahren : 34|3@1+ (1.0,0.0) [0.0|7] ""  Vector__XXX
 SG_ PreCrash_BFS_Sitzlehne_verfahren : 37|3@1+ (1.0,0.0) [0.0|7] ""  Vector__XXX
 SG_ PreCrash_Fo_Sitzlehne_verfahren : 40|3@1+ (1.0,0.0) [0.0|7] ""  Vector__XXX
 SG_ PreCrash_FS_KSV_verfahren : 43|4@1+ (1.0,0.0) [0.0|15] ""  Vector__XXX
 SG_ PreCrash_BFS_KSV_verfahren : 47|4@1+ (1.0,0.0) [0.0|15] ""  Vector__XXX
 SG_ PreCrash_Fo_KSV_verfahren : 51|4@1+ (1.0,0.0) [0.0|15] ""  Vector__XXX
 SG_ PreCrash_BFS_Laengsverstellung : 55|1@1+ (1.0,0.0) [0.0|1] ""  Vector__XXX
 SG_ SC_PreCrash_Warnung : 56|4@1+ (1.0,0.0) [0.0|15] ""  HUD,Kombi
 SG_ SC_PreCrash_Texte : 60|4@1+ (1.0,0.0) [0.0|15] ""  Kombi

BO_ 1122 PSD_04: 8 Gateway_Max
 SG_ PSD_Segment_ID : 0|6@1+ (1,0) [2|63] ""  HUD
 SG_ PSD_Vorgaenger_Segment_ID : 6|6@1+ (1,0) [2|63] ""  Vector__XXX
 SG_ PSD_Segmentlaenge : 12|7@1+ (2,0) [0|254] "Unit_Meter"  HUD
 SG_ PSD_Strassenkategorie : 19|3@1+ (1.0,0.0) [0.0|7] ""  Vector__XXX
 SG_ PSD_Endkruemmung : 22|8@1+ (1,0) [0|254] "Unit_None"  HUD
 SG_ PSD_Endkruemmung_Vorz : 30|1@1+ (1.0,0.0) [0.0|1] ""  HUD
 SG_ PSD_Idenditaets_ID : 31|6@1+ (1,0) [2|63] ""  Vector__XXX
 SG_ PSD_ADAS_Qualitaet : 37|1@1+ (1.0,0.0) [0.0|1] ""  Vector__XXX
 SG_ PSD_wahrscheinlichster_Pfad : 38|1@1+ (1.0,0.0) [0.0|1] ""  Vector__XXX
 SG_ PSD_Geradester_Pfad : 39|1@1+ (1.0,0.0) [0.0|1] ""  Vector__XXX
 SG_ PSD_Fahrspuren_Anzahl : 40|3@1+ (1.0,0.0) [0.0|7] ""  Vector__XXX
 SG_ PSD_Bebauung : 43|1@1+ (1.0,0.0) [0.0|1] ""  Vector__XXX
 SG_ PSD_Segment_Komplett : 44|1@1+ (1.0,0.0) [0.0|1] ""  Vector__XXX
 SG_ PSD_Rampe : 45|2@1+ (1.0,0.0) [0.0|3] ""  Vector__XXX
 SG_ PSD_Anfangskruemmung : 47|8@1+ (1,0) [0|254] ""  HUD
 SG_ PSD_Anfangskruemmung_Vorz : 55|1@1+ (1.0,0.0) [0.0|1] ""  HUD
 SG_ PSD_Abzweigerichtung : 56|1@1+ (1.0,0.0) [0.0|1] ""  HUD
 SG_ PSD_Abzweigewinkel : 57|7@1+ (1.417323,0) [0.000000|180.000021] ""  HUD

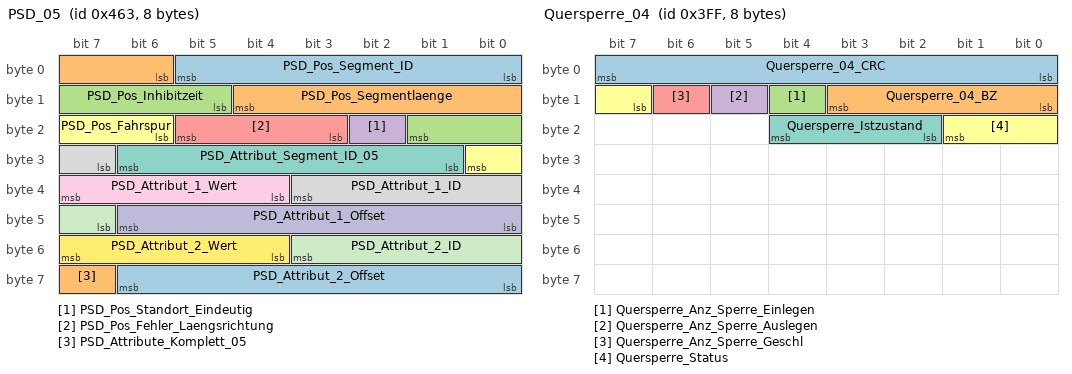
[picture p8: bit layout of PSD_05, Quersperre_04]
BO_ 1123 PSD_05: 8 Gateway_Max
 SG_ PSD_Pos_Segment_ID : 0|6@1+ (1,0) [2|63] ""  HUD
 SG_ PSD_Pos_Segmentlaenge : 6|7@1+ (2,0) [0|254] "Unit_Meter"  HUD
 SG_ PSD_Pos_Inhibitzeit : 13|5@1+ (10,0) [0|310] "Unit_MilliSecon"  Vector__XXX
 SG_ PSD_Pos_Standort_Eindeutig : 18|1@1+ (1.0,0.0) [0.0|1] ""  Vector__XXX
 SG_ PSD_Pos_Fehler_Laengsrichtung : 19|3@1+ (1.0,0.0) [0.0|7] ""  Vector__XXX
 SG_ PSD_Pos_Fahrspur : 22|3@1+ (1.0,0.0) [0.0|7] ""  Vector__XXX
 SG_ PSD_Attribut_Segment_ID_05 : 25|6@1+ (1,0) [2|63] ""  Vector__XXX
 SG_ PSD_Attribut_1_ID : 31|5@1+ (1,0) [1|31] ""  Vector__XXX
 SG_ PSD_Attribut_1_Wert : 36|4@1+ (1,0) [0|15] "Unit_None"  Vector__XXX
 SG_ PSD_Attribut_1_Offset : 40|7@1+ (2,0) [0|254] "Unit_Meter"  Vector__XXX
 SG_ PSD_Attribut_2_ID : 47|5@1+ (1,0) [1|31] ""  Vector__XXX
 SG_ PSD_Attribut_2_Wert : 52|4@1+ (1,0) [0|15] "Unit_None"  Vector__XXX
 SG_ PSD_Attribut_2_Offset : 56|7@1+ (2,0) [0|254] "Unit_Meter"  Vector__XXX
 SG_ PSD_Attribute_Komplett_05 : 63|1@1+ (1.0,0.0) [0.0|1] ""  Vector__XXX

BO_ 1124 PSD_06: 8 Gateway_Max
 SG_ PSD_06_Mux M  : 0|3@1+ (1.0,0.0) [0.0|7] ""  HUD,Kombi
 SG_ PSD_Sys_Segment_ID m0  : 3|6@1+ (1,0) [2|63] ""  Vector__XXX
 SG_ PSD_Attribut_Segment_ID m1  : 3|6@1+ (1,0) [2|63] ""  Vector__XXX
 SG_ PSD_Ges_Segment_ID m2  : 3|6@1+ (1,0) [2|63] ""  Vector__XXX
 SG_ PSD_Baum_Laenge_VZ m3  : 3|1@1+ (1.0,0.0) [0.0|1] ""  Vector__XXX
 SG_ PSD_Steigung_1_Segment_ID m4  : 3|6@1+ (1,0) [2|63] ""  Vector__XXX
 SG_ PSD_Baum_Laenge m3  : 4|25@1+ (0.00001,0) [0.00000|180.00000] "Unit_DegreOfArc"  Vector__XXX
 SG_ PSD_Sys_Laendercode m0  : 9|8@1+ (1,0) [0|255] "Unit_None"  HUD,Kombi
 SG_ PSD_Attribut_3_ID m1  : 9|5@1+ (1,0) [1|31] ""  Vector__XXX
 SG_ PSD_Ges_Offset m2  : 9|7@1+ (2,0) [0|254] "Unit_Meter"  Vector__XXX
 SG_ PSD_Steigung_1_A_Steigung m4  : 9|7@1+ (0.12,0) [0.00|15.00] "Unit_PerCent"  Vector__XXX
 SG_ PSD_Attribut_3_Offset m1  : 14|7@1+ (2,0) [0|254] "Unit_Meter"  Vector__XXX
 SG_ PSD_Ges_Geschwindigkeit m2  : 16|5@1+ (1.0,0.0) [0.0|31] ""  Vector__XXX
 SG_ PSD_Steigung_1_A_Vorz m4  : 16|1@1+ (1.0,0.0) [0.0|1] ""  Vector__XXX
 SG_ PSD_Sys_Geschwindigkeit_Einheit m0  : 17|1@1+ (1.0,0.0) [0.0|1] ""  Vector__XXX
 SG_ PSD_Steigung_1_A_Offset m4  : 17|7@1+ (2,0) [0|254] "Unit_Meter"  Vector__XXX
 SG_ PSD_Sys_Verkehrsrichtung m0  : 18|1@1+ (1.0,0.0) [0.0|1] ""  Vector__XXX
 SG_ PSD_Sys_Geometrieguete m0  : 19|2@1+ (1.0,0.0) [0.0|3] ""  Vector__XXX
 SG_ PSD_Sys_Mapmatchingguete m0  : 21|2@1+ (1.0,0.0) [0.0|3] ""  Vector__XXX
 SG_ PSD_Attribut_3_Wert m1  : 21|4@1+ (1,0) [0|15] "Unit_None"  Vector__XXX
 SG_ PSD_Ges_Typ m2  : 21|2@1+ (1.0,0.0) [0.0|3] ""  Vector__XXX
 SG_ PSD_Sys_Alter_Karte m0  : 23|3@1+ (1.0,0.0) [0.0|7] ""  Vector__XXX
 SG_ PSD_Ges_Spur_Geschw_Begrenzung m2  : 23|6@1+ (1.0,0.0) [0.0|63] ""  Vector__XXX
 SG_ PSD_Steigung_1_B_Steigung m4  : 24|7@1+ (0.12,0) [0.00|15.00] "Unit_PerCent"  Vector__XXX
 SG_ PSD_Attribut_4_ID m1  : 25|5@1+ (1,0) [1|31] ""  Vector__XXX
 SG_ PSD_Sys_Zielfuehrung m0  : 26|1@1+ (1.0,0.0) [0.0|1] ""  Vector__XXX
 SG_ PSD_Sys_US_State m0  : 27|6@1+ (1.0,0.0) [0.0|63] ""  Vector__XXX
 SG_ PSD_Ges_Geschwindigkeit_Gespann m2  : 29|2@1+ (1.0,0.0) [0.0|3] ""  Vector__XXX
 SG_ PSD_Baum_Breite_VZ m3  : 29|1@1+ (1.0,0.0) [0.0|1] ""  Vector__XXX
 SG_ PSD_Attribut_4_Wert m1  : 30|4@1+ (1,0) [0|15] ""  Vector__XXX
 SG_ PSD_Baum_Breite m3  : 30|24@1+ (0.00001,0) [0.00000|90.00000] "Unit_DegreOfArc"  Vector__XXX
 SG_ PSD_Ges_Geschwindigkeit_Witter m2  : 31|2@1+ (1.0,0.0) [0.0|3] ""  Vector__XXX
 SG_ PSD_Steigung_1_B_Vorz m4  : 31|1@1+ (1.0,0.0) [0.0|1] ""  Vector__XXX
 SG_ PSD_Steigung_1_B_Offset m4  : 32|7@1+ (2,0) [0|254] "Unit_Meter"  Vector__XXX
 SG_ PSD_Sys_Quali_Geometrien m0  : 33|3@1+ (1,0) [0|7] "Unit_None"  Vector__XXX
 SG_ PSD_Ges_Geschwindigkeit_Tag_Anf m2  : 33|3@1+ (1.0,0.0) [0.0|7] ""  Vector__XXX
 SG_ PSD_Attribut_4_Offset m1  : 34|7@1+ (2,0) [0|254] "Unit_Meter"  Vector__XXX
 SG_ PSD_Sys_Quali_Ortsinfo m0  : 36|2@1+ (1,0) [0|3] "Unit_None"  Vector__XXX
 SG_ PSD_Ges_Geschwindigkeit_Tag_Ende m2  : 36|3@1+ (1.0,0.0) [0.0|7] ""  Vector__XXX
 SG_ PSD_Sys_Quali_verfuegbar m0  : 38|1@1+ (1.0,0.0) [0.0|1] ""  Vector__XXX
 SG_ PSD_Sys_Zielfuehrung_geaendert m0  : 39|1@1+ (1.0,0.0) [0.0|1] ""  Vector__XXX
 SG_ PSD_Ges_Geschwindigkeit_Std_Anf m2  : 39|5@1+ (1,0) [0|24] "Unit_Hours"  Vector__XXX
 SG_ PSD_Steigung_1_Attribute_kompl m4  : 39|1@1+ (1.0,0.0) [0.0|1] ""  Vector__XXX
 SG_ PSD_Sys_Geometrieguete_erweitert m0  : 40|8@1+ (1.0,0.0) [0.0|255] ""  Vector__XXX
 SG_ PSD_Steigung_2_Segment_ID m4  : 40|6@1+ (1,0) [2|63] ""  Vector__XXX
 SG_ PSD_Attribut_5_ID m1  : 41|5@1+ (1,0) [1|31] ""  Vector__XXX
 SG_ PSD_Ges_Geschwindigkeit_Std_Ende m2  : 44|5@1+ (1,0) [0|24] "Unit_Hours"  Vector__XXX
 SG_ PSD_Attribut_5_Offset m1  : 46|7@1+ (2,0) [0|254] "Unit_Meter"  Vector__XXX
 SG_ PSD_Steigung_2_Steigung m4  : 46|7@1+ (0.12,0) [0.00|15.00] "Unit_PerCent"  Vector__XXX
 SG_ PSD_Sys_Quali_sonstige_Attribute m0  : 48|3@1+ (1,0) [0|7] "Unit_None"  Vector__XXX
 SG_ PSD_Ges_Ueberholverbot m2  : 49|2@1+ (1.0,0.0) [0.0|3] ""  Vector__XXX
 SG_ PSD_Sys_Quali_Steigungen m0  : 51|3@1+ (1,0) [0|7] ""  Vector__XXX
 SG_ PSD_Ges_Wechselverkehrszeichen m2  : 51|3@1+ (1.0,0.0) [0.0|7] ""  Vector__XXX
 SG_ PSD_Attribut_5_Wert m1  : 53|4@1+ (1,0) [0|15] ""  Vector__XXX
 SG_ PSD_Steigung_2_Vorz m4  : 53|1@1+ (1.0,0.0) [0.0|1] ""  Vector__XXX
 SG_ PSD_Sys_Quali_Strassenkennz m0  : 54|3@1+ (1,0) [0|7] "Unit_None"  Vector__XXX
 SG_ PSD_Wechselverkehrszeichen_Typ m2  : 54|2@1+ (1.0,0.0) [0.0|3] ""  Vector__XXX
 SG_ PSD_Baum_Ausrichtung m3  : 54|10@1+ (0.3515625,0) [0E-7|359.6484375] "Unit_DegreOfArc"  Vector__XXX
 SG_ PSD_Steigung_2_Offset m4  : 54|7@1+ (2,0) [0|254] "Unit_Meter"  Vector__XXX
 SG_ PSD_Ges_Gesetzlich_Kategorie m2  : 56|3@1+ (1.0,0.0) [0.0|7] ""  Vector__XXX
 SG_ PSD_Sys_Quali_Tempolimits m0  : 57|3@1+ (1,0) [0|7] "Unit_None"  Vector__XXX
 SG_ PSD_Attribute_Komplett_06 m1  : 57|1@1+ (1.0,0.0) [0.0|1] ""  Vector__XXX
 SG_ PSD_Ges_Gesetzlich_Zusatz m2  : 59|2@1+ (1.0,0.0) [0.0|3] ""  Vector__XXX
 SG_ PSD_Sys_Quali_Vorfahrtsregelung m0  : 60|3@1+ (1,0) [0|7] "Unit_None"  Vector__XXX
 SG_ PSD_Ges_Verkehrszeichen_Quelle m2  : 61|2@1+ (1.0,0.0) [0.0|3] ""  Vector__XXX
 SG_ PSD_Steigung_2_Attribute_kompl m4  : 61|1@1+ (1.0,0.0) [0.0|1] ""  Vector__XXX
 SG_ PSD_Ges_Attribute_Komplett m2  : 63|1@1+ (1.0,0.0) [0.0|1] ""  Vector__XXX

BO_ 1023 Quersperre_04: 8 Vector__XXX
 SG_ Quersperre_04_CRC : 0|8@1+ (1,0) [0|255] ""  Gateway_Max
 SG_ Quersperre_04_BZ : 8|4@1+ (1,0) [0|15] ""  Gateway_Max
 SG_ Quersperre_Anz_Sperre_Einlegen : 12|1@1+ (1.0,0.0) [0.0|1] ""  Gateway_Max,Kombi
 SG_ Quersperre_Anz_Sperre_Auslegen : 13|1@1+ (1.0,0.0) [0.0|1] ""  Gateway_Max,Kombi
 SG_ Quersperre_Anz_Sperre_Geschl : 14|1@1+ (1.0,0.0) [0.0|1] ""  Gateway_Max,Kombi
 SG_ Quersperre_Status : 15|3@1+ (1.0,0.0) [0.0|7] ""  Gateway_Max
 SG_ Quersperre_Istzustand : 18|3@1+ (1.0,0.0) [0.0|7] ""  Gateway_Max

BO_ 1529 RDK_02: 8 Gateway_Max
 SG_ RDK_FMVSS138_Lampe : 12|1@1+ (1.0,0.0) [0.0|1] ""  Kombi
 SG_ RDK_FMVSS138_MIL : 13|1@1+ (1.0,0.0) [0.0|1] ""  Kombi
 SG_ RDK_Kalibrierung : 14|1@1+ (1.0,0.0) [0.0|1] ""  Kombi
 SG_ RDK_Reifendruck_Lampe : 15|1@1+ (1.0,0.0) [0.0|1] ""  Vector__XXX
 SG_ RDK_Warnungen_02 : 16|5@1+ (1.0,0.0) [0.0|31] ""  Kombi
 SG_ RDK_angelernt : 22|1@1+ (1.0,0.0) [0.0|1] ""  Vector__XXX
 SG_ RDK_Reifentemperatur_Lampe : 23|1@1+ (1.0,0.0) [0.0|1] ""  Vector__XXX
 SG_ RDK_RS_aktiv : 24|1@1+ (1.0,0.0) [0.0|1] ""  Vector__XXX
 SG_ RDK_Text_7 : 25|1@1+ (1.0,0.0) [0.0|1] ""  Vector__XXX
 SG_ RDK_W_1_Reifen_HL : 56|1@1+ (1.0,0.0) [0.0|1] ""  Vector__XXX
 SG_ RDK_W_1_Reifen_HR : 57|1@1+ (1.0,0.0) [0.0|1] ""  Vector__XXX
 SG_ RDK_W_1_Reifen_VL : 58|1@1+ (1.0,0.0) [0.0|1] ""  Vector__XXX
 SG_ RDK_W_1_Reifen_VR : 59|1@1+ (1.0,0.0) [0.0|1] ""  Vector__XXX
 SG_ RDK_W_2_Reifen_HL : 60|1@1+ (1.0,0.0) [0.0|1] ""  Vector__XXX
 SG_ RDK_W_2_Reifen_HR : 61|1@1+ (1.0,0.0) [0.0|1] ""  Vector__XXX
 SG_ RDK_W_2_Reifen_VL : 62|1@1+ (1.0,0.0) [0.0|1] ""  Vector__XXX
 SG_ RDK_W_2_Reifen_VR : 63|1@1+ (1.0,0.0) [0.0|1] ""  Vector__XXX

CM_ BO_ 1601 "ab MQB mit CRC-8";
CM_ BO_ 813 "Gesendet nur bei CNG/LPG-Motorprojekten";
CM_ BO_ 2600468507 "CAN_NM_PDU MLBevo";
CM_ BO_ 1630 "Tankgeberwerte für OBD-relevante Plausibilisierung im Motor-SG";
CM_ BO_ 2549940736 "VDC funktionaler Request auf CANHS";
CM_ BO_ 2621506048 "VDC funktionaler Request auf CANFD";
CM_ BO_ 1175 "neue Struktur ab MQB ohne KD-Fehler";
CM_ BO_ 1355 "neue Struktur ab MQB ohne KD-Fehler";
CM_ BO_ 1529 "MQB";

CM_ SG_ 2331595982 PTHyDrA_PrctUtilElDrv "Display for Fahrer Information Display, that shows the utilization in percent of the electric drive system. When full the combustion engine shall start.";
CM_ SG_ 2331595982 PTHyDrA_StAcv "Status-Information Assistent für elektrisches Fahren";
CM_ SG_ 2331595982 PTUIPwrm_FacPwrDyn "Dynamik-Faktor für die anzuzeigende momentane relative Systemleistung im Powermeter";
CM_ SG_ 2331595982 PTUIPwrm_PrctBoostAvl "Anzuzeigende relative Verfügbarkeit des Boost.";
CM_ SG_ 2331595982 PTUIPwrm_PrctPwrEcoMaxUse "relative verfügbare und ökologisch klassifizierte Vortriebs-Leistung des Gesamtantriebs";
CM_ SG_ 2331595982 PTUIPwrm_PrctPwrElBoostCur "Anzuzeigende momentane relative Leistung des Boost";
CM_ SG_ 2331595982 PTUIPwrm_PrctPwrElBoostMaxUse "Anzuzeigende relative nutzbare Leistung des Boost.";
CM_ SG_ 2331595982 PTUIPwrm_PrctPwrElDrvCur "Anzuzeigende momentane relative Leistung des elektrischen Antriebs im Powermeter";
CM_ SG_ 2331595982 PTUIPwrm_PrctPwrGnrMaxUse "Anzuzeigende relative nutzbare generatorische Leistung im Powermeter";
CM_ SG_ 2331595982 PTUIPwrm_PrctPwrMotElMaxUse "Anzuzeigende relative nutzbare motorische Leistung des elektr. Antriebs im Powermeter";
CM_ SG_ 2331595982 PTUIPwrm_PrctPwrMotMaxUse "Anzuzeigende relative nutzbare motorische Leistung im Powermeter";
CM_ SG_ 2331595982 PTUIPwrm_PrctPwrSysCur "Anzuzeigende momentane relative Systemleistung im Powermeter";
CM_ SG_ 2331595982 PTUIPwrm_PrctPwrSysMaxUseTemp "relative kurzzeitig verfügbare Vortriebs-Leistung des Gesamtantriebs";
CM_ SG_ 2331595982 PTUIPwrm_PwrElBoostNom "nominelle Boost-Leistung des elektrischen Antriebs";
CM_ SG_ 2331595982 PTUIPwrm_StAcv "Status-Information Powermeter";

CM_ SG_ 2589283946 PTUIPwrm_PwrGnrNom "nominelle Verzögerungs-Leistung des elektrischen Antriebs ";
CM_ SG_ 2589283946 PTUIPwrm_PwrMotElNom "nominelle Vortriebs-Leistung des elektrischen Antriebs";
CM_ SG_ 2589283946 PTUIPwrm_PwrSysMotNomDisp "nominelle Vortriebs-Leistung des Gesamtantriebs";

CM_ SG_ 1601 MO_Ansaugsystem "Art des Ansaugsystems des Verbrennungsmotors";
CM_ SG_ 1601 MO_Anzahl_Zyl "Zylinderzahl des Verbrennungsmotors";
CM_ SG_ 1601 MO_Anzeige_StSt_gueltig "Zeigt die Gültigkeit der neuen StSt-Anzeigesignale an, MO_Anzeige_StSt_Text und  MO_Anzeige_Symbol. Mo_Text_Motorstart 1..5 sind zu ignorieren.";
CM_ SG_ 1601 MO_Code "Motorcodierinformation Version 16 (Details siehe Anhang)";
CM_ SG_ 1601 MO_DPF_verbaut "Verbauinformation Diesel-Partikel-Filter
";
CM_ SG_ 1601 MO_Faktor_Momente_02 "Dieses Signal schaltet den Wertebereich aller Momente vom Motor, Getriebe, TSK, Bremse ... um! Die Momente besitzen somit einen variablen Wertebereich, weil sich durch den Faktor die Momente sowohl in Auflösung als auch Maximalwerten ändert.

0x0 nicht ";
CM_ SG_ 1601 MO_Getriebe_Code "Getriebecodierung des Motors";
CM_ SG_ 1601 MO_Hubraum "Hubraum des Verbrennungsmotors";
CM_ SG_ 1601 MO_Hybridfahrzeug "Anhand dieses Signals plausibilisiert die Lenkhilfe das Bit Fahrbereitschaft.

Im Projekt Cayenne PHEV (und ggf. auch VW526 PHEV) ist aus Gründen der Abwärtskompatibilität der Wert '2' zu senden.";
CM_ SG_ 1601 MO_Kraftstoffart "Primärkraftstoff zum Antrieb des Fahrzeugs";
CM_ SG_ 1601 MO_Leistung "Nennleistung des Verbrennungsmotors

Im reinen E-Fahrzeug (BEV): Ausgabe der elektrischen Systemleistung";
CM_ SG_ 1601 MO_OBD_Typ "Abgastyp OBD
Hinweis: In Fahrzeugen mit dem Zielmarkt China und einer Zertifizierung ab China 6 muss auf dem Signal 'MO_OBD_Typ' der Wert 'US_OBD' gesendet werden.";
CM_ SG_ 1601 MO_StartStopp_Codiert "Funktion StartStopp im aktuellen Klemmenzyklus verbaut";
CM_ SG_ 1601 Motor_Code_01_CRC "Für MLB:
'Berechnung siehe Lastenheft 'Kommunikationsabsicherung für FlexRay und CAN''

Ab MQB und MLBevo:
'Berechnung siehe Lastenheft 'End-to-End Kommunikationsabsicherung''

Endwerte siehe Begleitdokument 'S-PDU Kennungsfolgen'";
CM_ SG_ 1601 TSK_Codierung "Information über den plausibilisierten Codierungszustand des Triebstrangskoordinators auf ACC oder GRA.";

CM_ SG_ 391 EV_Rekuperationsstufe "Im Kombi anzuzeigende Rekuperationsstufe";
CM_ SG_ 391 MO_Drehzahl_VM "Motordrehzahl des Verbrennungsmotors

für OBD freeze frame

Hinweis: 
Ehemaliger Fehlerwert 0xFFFF wird senderseitig nicht unterstützt. 
Diesen Wert aus Kompatibilitätsgründen nicht neu belegen!";
CM_ SG_ 391 MO_Fehler_Notabschaltung_Klima "Das Signal dient der schnellen Abschaltung der Klimakomponenten (EKK, HV-Heizung) durch den HV-Koordinator (MSG) nach einem HV-Interlock Ereignis.";
CM_ SG_ 391 MO_Fehler_NTKreis "Fehlerstatus Niedertemperaturkreis";
CM_ SG_ 391 MO_KLE_FStatus "Fehlerstatus der Kühlerlüfterelektronik";
CM_ SG_ 391 MO_Tankbereitschaft_Status "Meldung der Tankbereitschaft";
CM_ SG_ 391 MO_Tankklappensteuerung "Ansteuerungsanforderung der Tankklappe";
CM_ SG_ 391 MO_Waehlpos "Wählhebelposition (im VW120/7 und MQB BEV ist der Wählhebel am HCAN mit Master Motor-SG angeschlossen)

(wenn das Signal zusätzlich in Botschaft MSG_HYB_03 verortet ist, gilt: Signal nur in der CAN-Welt PQ35/25 zu verwenden, da dort am ACAN die Wählhebe";
CM_ SG_ 391 MO_WH_Texte "Fahrerhinweise für das Kombi";
CM_ SG_ 391 Motor_EV_01_BZ "Fehlende Beschreibung (Import)";
CM_ SG_ 391 Motor_EV_01_CRC "Für MLB:
'Berechnung siehe Lastenheft 'Kommunikationsabsicherung für FlexRay und CAN''

Ab MQB und MLBevo:
'Berechnung siehe Lastenheft 'End-to-End Kommunikationsabsicherung''

Endwerte siehe Begleitdokument 'S-PDU Kennungsfolgen'";

CM_ SG_ 813 MO_akt_Betrieb "Motor läuft aktuell im Benzin- oder Gasbetrieb";
CM_ SG_ 813 MO_AnzeigeGasbetrieb "Anzeige des Betriebszustands bei Umschaltung zwischen Gas- und Benzinbetrieb";
CM_ SG_ 813 MO_CNG_Tankstopp "Der CNG-Tankalgorithmus hat einen Tankstopp (CNG-Tank) erkannt.
Bei separatem CNG-SG gatet das MSG die Information.";
CM_ SG_ 813 MO_CNG_Ueberlauf "Der motorsteuergeräteinterne Verbrauchszähler ist mindestens einmal übergelaufen. Dieses Bit wird genutzt, um erkennen zu können, dass das Motorsteuergerät aus dem Reset-Zustand hochläuft.";
CM_ SG_ 813 MO_Erdgasqualitaet "Erdgas-Qualität abgestuft in 70%, 80%, 90% und 100% (bei CNG bezogen auf 100% Methan). Berechnung erfolgt einmalig nach jeder Betankungserkennung.";
CM_ SG_ 813 MO_Fuellstand_LPG "Tankfüllstand LPG (Sensor am MSG/LPG-SG)";
CM_ SG_ 813 MO_Fuellungsgrad_CNG "Gefilterter temperaturkompensierter Gasdruckwert als Prozentwert vom Maximalwert wird im Kombi als Zeiger dargestellt.";
CM_ SG_ 813 MO_Fuellungsgrad_LPG "Füllungsgrad des LPG-Tanks in %";
CM_ SG_ 813 MO_LPG_Tankstopp "Der LPG-Tankalgorithmus hat einen Tankstopp (LPG-Tank) erkannt.
Bei separatem LPG-SG gatet das MSG die Information.";
CM_ SG_ 813 MO_LPG_Ueberlauf "Der motorsteuergeräteinterne Verbrauchszähler ist mindestens einmal übergelaufen. Dieses Bit wird genutzt, um erkennen zu können, dass das Motorsteuergerät aus dem Reset-Zustand hochläuft.";
CM_ SG_ 813 MO_Tankmasse_CNG "Max. Tankmasse in kg bei einem Tankdruck von 200bar, in Abhängigkeit vom max. Tankvolumen und der CNG-Tanktemperatur beim Befüllen (Verwendung im Kombi zur Reichweitenberechnung)";
CM_ SG_ 813 MO_Tankvolumen_LPG "Volumen des LPG-Tanks";
CM_ SG_ 813 MO_Verbrauch_CNG "Motorsteuergeräteinterner Verbrauchszähler, der vom Kombi zyklisch ausgelesen wird, um die Gasmenge zur Verbrauchsberechnung aufzusummieren; aus diesem Zählerstand werden Momentan- und Durchschnittsverbrauch berechnet; das Überlauf-Bit ist zu berücksichti";
CM_ SG_ 813 MO_Verbrauch_LPG "Motorsteuergeräteinterner Verbrauchszähler, der vom Kombi zyklisch ausgelesen wird, um die Gasmenge zur Verbrauchsberechnung aufzusummieren; aus diesem Zählerstand werden Momentan- und Durchschnittsverbrauch berechnet; das Überlauf-Bit ist zu berücksichti";
CM_ SG_ 813 MO_Verbrauchsaequivalent "Faktor zur Umrechnung des aktuellen/letzten Verbrauchs im LPG/CNG-Betrieb auf einen äquivalenten Benzin-Verbrauch (zur Ermittlung der Gesamtreichweite)";

CM_ SG_ 1155 MO_Powermeter_Charge_Grenze "Zeigt eine Einschränkung der Rekuperationsleistung an
";
CM_ SG_ 1155 Mo_Powermeter_Grenze "Anzeige des verfügbaren Powermeterstands im Kombi. Bei EV Unterscheidung zwischen Boost- und Dauerbereich, bei HEV für die Zustartgrenze nutzber";
CM_ SG_ 1155 MO_Powermeter_Grenze_strategisch "Zeigt eine strategische Leistungsbeschränkung des Antriebs, 
zum Beispiel kein Boost im Efficiency Modus";
CM_ SG_ 1155 MO_Powermeter_Inszenierung_aktiv "Mit Hilfe des Signals kann eine Dynamikabfahrt für den Kunden inszeniert werden. Die Inszenierung wird im Powermeter des Kombi-Instruments verortet.";
CM_ SG_ 1155 MO_Powermeter_obere_E_Grenze "Zeigt die obere Grenze für das elektrische Fahren an";
CM_ SG_ 1155 MO_Powermeter_untere_E_Grenze "Zeigt die untere Grenze für das elektrische Fahren an";

CM_ SG_ 1284 MV_Bordnetz_aktiv "Signalisiert ein aktives MV-Bordnetz. MV-Schütze geschlossen.";
CM_ SG_ 1284 MV_Bordnetz_belastbar "Signalisierung vom MVEM das das 48V Bordnetz vollständig belastbar ist  >5 Watt";
CM_ SG_ 1284 MV_Bordnetz_Fehler "Status ob im  MV-Netz ein Fehler detektiert wurde.";
CM_ SG_ 1284 MVK_01_BZ "4bit Botschaftszähler, wird mit jeder Sendebotschaft inkrementiert";
CM_ SG_ 1284 MVK_01_CRC "Für MLB:
Berechnung siehe Lastenheft 'Kommunikationsabsicherung für FlexRay und CAN'
Ab MQB und MLBevo:
Berechnung siehe Lastenheft 'End-to-End Kommunikationsabsicherung'

Endwerte siehe Begleitdokument 'S-PDU Kennungsfolgen'";
CM_ SG_ 1284 MVK_BMS_Sollmodus "Angeforderter Sollmodus der MV-Batterie:
0 : MV_Off                                
1 : MV_On (HS geschlossen)                
2 : nicht belegbar                        
3 : nicht belegbar                        
4 : nicht belegbar 
5 : nicht belegb";
CM_ SG_ 1284 MVK_BOOST_Sollmodus "Sollmodus eBooster auf 48V
0 : keine Freigabe
1 : Freigabe
2 : nicht belegbar
3 : nicht belegbar
4 : nicht belegbar
5 : nicht belegbar
6 : nicht belegbar
7 : Init   (CAN-Initialisierung)   

Info: 'nicht belegbar' d.h. Sollmodus nicht relevant f";
CM_ SG_ 1284 MVK_DCDC_Sollmodus "angeforderte Soll-Betriebsart des 48V DC/DC-Wandlers: 
0: Standby; Kommunikation aktiv
1: MvOn (48V-Netz ist aktiv)
2: Tiefsetzen (48V --> BN 14,4V)
3: Hochsetzen (BN 14,4V --> 48V)
4: Startunterstuetzung_48V (Stützung des 48V-BN im Startvorgang)
5:";
CM_ SG_ 1284 MVK_DCDC_Sollmodus_02 "Angeforderte Soll-Betriebsart des 48V DC/DC-Wandlers: 
0: Standby; Kommunikation aktiv
1: MvOn (48V-Netz ist aktiv)
2: Tiefsetzen (48V --> BN12)
3: Hochsetzen (BN12 --> 48V)
4: Startunterstuetzung_48V (Stützung des 48V-BN im Startvorgang)
5: nicht v";
CM_ SG_ 1284 MVK_eABC_Sollmodus "Sollmodus eABC auf 48V
0 : keine Freigabe
1 : Freigabe
2 : nicht belegbar
3 : nicht belegbar
4 : nicht belegbar
5 : nicht belegbar
6 : nicht belegbar
7 : Init   (CAN-Initialisierung)   

Info: 'nicht belegbar' d.h. Sollmodus nicht relevant für M";
CM_ SG_ 1284 MVK_eAWS_Sollmodus "Sollmodus eAWS auf 48V
0 : keine Freigabe
1 : Freigabe
2 : nicht belegbar
3 : nicht belegbar
4 : nicht belegbar
5 : nicht belegbar
6 : nicht belegbar
7 : Init   (CAN-Initialisierung)   

Info: 'nicht belegbar' d.h. Sollmodus nicht relevant für M";
CM_ SG_ 1284 MVK_Istmodus_Anf "MVK-Anforderung an alle 48V-Komponenten deren Istmodus im schnellen Zyklus (Inhibitzeit) zu senden.";
CM_ SG_ 1284 MVK_MO_EmSollzustand "Anforderung vom MVK Sollzustand der Elm_State
0 = MvOff              
1 = MvStbyReq          
2 = MvStbyWait         
3 = MvBattOnReq        
4 = MvBattOnWait       
10 = MvOnIdle          
18 = MvOnDrvReq        
19 = MvOnDrvWait       
20 = MvO";
CM_ SG_ 1284 MVK_MV_Batteriewarnung "Kundenwarnung aufgrund eines Batteriefehlers";
CM_ SG_ 1284 MVK_MV_Netz_Warnungen "Anforderung Warnung/Fehler MV-System im Kombi
0: Keine Warnung/Init
1:Anforderung_Anzeige_Warnung_MV-Netz (gelbes Symbol)
2:Anforderung_Anzeige_Fehler_MV-Netz (rotes Symbol)
3:Anforderung_Anzeige_Warnung_Kein_Wiederstart_möglich";
CM_ SG_ 1284 MVK_MVPTC_Sollmodus "Sollmodus MV-PTC
0 : keine Freigabe
1 : Freigabe
2 : nicht belegbar
3 : nicht belegbar
4 : nicht belegbar
5 : nicht belegbar
6 : nicht belegbar
7 : Init   (CAN-Initialisierung)   

Info: 'nicht belegbar' d.h. Sollmodus nicht relevant für MVK";

CM_ SG_ 2583737729 NAD_AuthTime_SSN_Req_Data "AuthTime - Authentische Zeit
ISO-TP Datenkanal - NA2FID

ConMod_NAD an Funktion Authentische Zeit (Request)";

CM_ SG_ 2583868801 NAD_AuthTime_SSN_Resp_Data "AuthTime - Authentische Zeit
ISO-TP Datenkanal - NA2FID
Response Funktion 0x18 AuthTime

Funktion Authentische Zeit an ConMod_NAD (Response)";

CM_ SG_ 1156 ND_GDOP "geometric dilution of precision (Gesamtgenauigkeit, 3D und Zeit) 
";
CM_ SG_ 1156 ND_HDOP "horizontal dilution of precision (Horizontalrichtung, 2D)
";
CM_ SG_ 1156 ND_Heading "Fahrtrichtung";
CM_ SG_ 1156 ND_Init "Initialisierung";
CM_ SG_ 1156 ND_PDOP "positional dilution of precision (Positionsgenauigkeit, 3D) 
";
CM_ SG_ 1156 ND_TDOP "time dilution of precision (Zeitgenauigkeit)
";
CM_ SG_ 1156 ND_VDOP "vertical dilution of precision (Vertikalrichtung, 1D)
";

CM_ SG_ 1157 ND_SatInUse "Anzahl der zur Berechnung verwendeten Satelliten";
CM_ SG_ 1157 ND_SatInView "Anzahl der sichtbaren Satelliten";
CM_ SG_ 1157 ND_UTC "UTC-Zeit, verstrichene Sekunden seit 01.01.1970 00:00
0xFFFFFFFE = Init
0xFFFFFFFF = Fehler bei Berechnung der UTC-Time";
CM_ SG_ 1157 NP_Altitude "Hoehe ueber NN
0xFFF = Fehler bei der Berechnung der Höhe über NN";
CM_ SG_ 1157 POS_Guete_horizontal "Horizontale Genauigkeit der Position in der Botschaft NavPos_02_MapMatched (Signale
POS_LatDegree, POS_LongDegree)

Abhängig vom Signal
POS_Guete_horizontal_verfuegbar";
CM_ SG_ 1157 POS_Guete_horizontal_verfuegbar "Bei gesetztem Bit wird das Signal POS_Guete_horizontal befüllt und ist verfügbar.";

CM_ SG_ 1158 NP_LatDegree "Latitude (Nord-Süd Wert)";
CM_ SG_ 1158 NP_LatDirection "Hemisphäre Nord/Süd";
CM_ SG_ 1158 NP_LongDegree "Longitude (Ost-West Wert)";
CM_ SG_ 1158 NP_LongDirection "Hemisphäre Ost/West";
CM_ SG_ 1158 NP_Sat "Nummer der verwendeten Sateliten beim letzten Fix";

CM_ SG_ 2600468529 NM_ELV_CAB_V14 "CAB = Clusteraktivbits (V14)";
CM_ SG_ 2600468529 NM_ELV_Car_Wakeup "Car Wakeup (Gateway wertet aus)

ELV MQB_Gen1
-Gedrückter ZAT-Startwunsch MSG (für 2 Sekunden)
-Verriegelungsbedingungen prüfen -Senden V-Signal (6 - 30 Sekunden)

ELV MQB_Gen2
-Verriegelungsbedingungen prüfen -Senden V-Signal (6 - 30 Sekunden) 
";
CM_ SG_ 2600468529 NM_ELV_CBV_AWB "Das Signal ist zu setzen, wenn das SG aktiv den Bus geweckt hat
0 = Passiver_WakeUp = SG hat das Netzwerk nicht aktiv geweckt
1 = Akitiver_WakeUp = SG hat das Netzwerk aktiv geweckt";
CM_ SG_ 2600468529 NM_ELV_CBV_CRI "Das Signal ist dauerhaft gesetzt, wenn das NM-Layout Cluster- Anforderungen enthält";
CM_ SG_ 2600468529 NM_ELV_NM_aktiv_Diagnose "Diagnose befindet sich nach VW80124 in einer NonDefaultDiagnostic-Session, z.B. ExtendedDiagnostic-Session";
CM_ SG_ 2600468529 NM_ELV_NM_aktiv_KL15 "Steuergerät hat KL15-EIN erkannt";
CM_ SG_ 2600468529 NM_ELV_NM_aktiv_Meldung "Fahrerinformation aktiv";
CM_ SG_ 2600468529 NM_ELV_NM_aktiv_Tmin "Mindestaktivzeit ist noch nicht abgelaufen (bei jedem Weckereignis wird die Mindestaktivzeit neu gestartet)";
CM_ SG_ 2600468529 NM_ELV_NM_aktiv_Verfahrtrigger "Aktiver Trigger zum Verfahren der ELV ";
CM_ SG_ 2600468529 NM_ELV_NM_aktiv_WFS "WFS-Kommunikation aktiv";
CM_ SG_ 2600468529 NM_ELV_NM_State "1 = Zustand Repeat Message (<-- Bus-Sleep Mode)
2 = Zustand Repeat Message (<-- Prepare Bus-Sleep Mode)
4 = Zustand Normal Operation (<-- Repeat Message)
8 = Zustand Normal Operation (<-- Ready Sleep)";
CM_ SG_ 2600468529 NM_ELV_UDS_CC "Funktionseinschränkung aufgrund aktivem UDS-Communication Control, siehe VW80124";

CM_ SG_ 2600468496 NM_Gateway_CAB_V14 "CAB = Clusteraktivbits (V14)

Cluster CAB_01_Antrieb
-Innenraumklimatisierung starten
-Ladevorbedingung, Beginn des Ladens, Ende
-Lademodusänderung, Timer-Laden vs. Sofort Laden

Cluster CAB_02_Hybrid_Laden
-Laden an oder ausschalten
-Ladevorbedi";
CM_ SG_ 2600468496 NM_Gateway_Car_Wakeup "Car Wakeup (Subbusmaster wertet aus)

MQB: 
-Diagnose- oder Komponentenschutzmaster-Funktion weckt den schlafenden Subbus (z.B. MOST)

E3_Volumen:
- Diagnose aktiv -aktive Diagnosekommunikation am OBD-Stecker

MQBw_Baseline:
- Diagnose aktiv -akt";
CM_ SG_ 2600468496 NM_Gateway_CBV_AWB "Das Signal ist zu setzen, wenn das SG aktiv den Bus geweckt hat
0 = Passiver_WakeUp = SG hat das Netzwerk nicht aktiv geweckt
1 = Akitiver_WakeUp = SG hat das Netzwerk aktiv geweckt";
CM_ SG_ 2600468496 NM_Gateway_CBV_CRI "Das Signal ist dauerhaft gesetzt, wenn das NM-Layout Cluster- Anforderungen enthält";
CM_ SG_ 2600468496 NM_Gateway_NM_aktiv_Buskopplung "Nachlauf aufgrund Kopplung zweier Busse. z.B. K-CAN und K2-CAN";
CM_ SG_ 2600468496 NM_Gateway_NM_aktiv_CWU "Nachlauf aufgrund CWU Anforderung";
CM_ SG_ 2600468496 NM_Gateway_NM_aktiv_Diagnose "Diagnose befindet sich nach VW80124 in einer NonDefaultDiagnostic-Session, z.B. ExtendedDiagnostic-Session";
CM_ SG_ 2600468496 NM_Gateway_NM_aktiv_EM "Nachlauf aufgrund Energiemanagement";
CM_ SG_ 2600468496 NM_Gateway_NM_aktiv_FC "Nachlauf aufgrund Funktionscluster Anforderung";
CM_ SG_ 2600468496 NM_Gateway_NM_aktiv_KL15 "Steuergerät hat KL15-EIN erkannt";
CM_ SG_ 2600468496 NM_Gateway_NM_aktiv_Tmin "Mindestaktivzeit ist noch nicht abgelaufen (bei jedem Weckereignis wird die Mindestaktivzeit neu gestartet)";
CM_ SG_ 2600468496 NM_Gateway_NM_State "1 = Zustand Repeat Message (<-- Bus-Sleep Mode)
2 = Zustand Repeat Message (<-- Prepare Bus-Sleep Mode)
4 = Zustand Normal Operation (<-- Repeat Message)
8 = Zustand Normal Operation (<-- Ready Sleep)";
CM_ SG_ 2600468496 NM_Gateway_UDS_CC "Funktionseinschränkung aufgrund aktivem UDS-Communication Control, siehe VW80124";

CM_ SG_ 2600468507 NM_HUD_CAB_V14 "CAB = Clusteraktivbits (V14)";
CM_ SG_ 2600468507 NM_HUD_Car_WakeUp "Das Bit wird vom Waehlhebel nicht bedient. Die Car Wakeup-Funktionalität ist im Waehlhebel nicht umgesetzt.
";
CM_ SG_ 2600468507 NM_HUD_CBV_AWB "Das Signal ist zu setzen, wenn das SG aktiv den Bus geweckt hat
0 = Passiver_WakeUp = SG hat das Netzwerk nicht aktiv geweckt
1 = Akitiver_WakeUp = SG hat das Netzwerk aktiv geweckt";
CM_ SG_ 2600468507 NM_HUD_CBV_CRI "Das Signal ist dauerhaft gesetzt, wenn das NM-Layout Cluster- Anforderungen enthält";
CM_ SG_ 2600468507 NM_HUD_NM_aktiv_Diagnose "Diagnose befindet sich nach VW80124 in einer NonDefaultDiagnostic-Session, z.B. ExtendedDiagnostic-Session";
CM_ SG_ 2600468507 NM_HUD_NM_aktiv_KL15 "Steuergerät hat KL15-EIN erkannt";
CM_ SG_ 2600468507 NM_HUD_NM_aktiv_Tmin "Mindestaktivzeit ist noch nicht abgelaufen (bei jedem Weckereignis wird die Mindestaktivzeit neu gestartet)";
CM_ SG_ 2600468507 NM_HUD_NM_State "1 = Zustand Repeat Message (<-- Bus-Sleep Mode)
2 = Zustand Repeat Message (<-- Prepare Bus-Sleep Mode)
4 = Zustand Normal Operation (<-- Repeat Message)
8 = Zustand Normal Operation (<-- Ready Sleep)";
CM_ SG_ 2600468507 NM_HUD_UDS_CC "Funktionseinschränkung aufgrund aktivem UDS-Communication Control, siehe VW80124";

CM_ SG_ 2600468500 NM_Kombi_CAB_V14 "CAB = Clusteraktivbits (V14)

Cluster_CAB_02_Hybrid_Laden
- Lade Timer abgelaufen für 4 sec
- Manuelle oder automatische Zeitverstellung (>5min) bei aktivem Timer für 4 sec

Cluster CAB_09_Standheizung
- Timer abgelaufen (Standheiz Timer abgelaufen";
CM_ SG_ 2600468500 NM_Kombi_Car_Wakeup "Car Wakeup (Gateway wertet aus)
MQB: Timer abgelaufen, Zeitverstellung manuell oder automatisch (>5Min) beim aktiven Timer, Verlassenswarnung

MLBevo: Timer abgelaufen, Zeitverstellung manuell oder automatisch (>5Min) beim aktiven Timer
Berechnung Tan";
CM_ SG_ 2600468500 NM_Kombi_CBV_AWB "Das Signal ist zu setzen, wenn das SG aktiv den Bus geweckt hat";
CM_ SG_ 2600468500 NM_Kombi_CBV_CRI "Das Signal ist dauerhaft gesetzt, wenn das NM-Layout dem neuen NM-Layout für Teilnetzbetrieb entspricht";
CM_ SG_ 2600468500 NM_Kombi_NM_aktiv_Buzzer "Buzzer Weckereignis aktiv (1 Minute)";
CM_ SG_ 2600468500 NM_Kombi_NM_aktiv_Diagnose "Diagnose befindet sich nach VW80124 in einer NonDefaultDiagnostic-Session, z.B. ExtendedDiagnostic-Session";
CM_ SG_ 2600468500 NM_Kombi_NM_aktiv_KL15 "Steuergerät hat KL15-EIN erkannt";
CM_ SG_ 2600468500 NM_Kombi_NM_aktiv_Schluesselkomm "Schlüsselkommunikation aktiv (WFS)";
CM_ SG_ 2600468500 NM_Kombi_NM_aktiv_Tmin "Mindestaktivzeit ist noch nicht abgelaufen (bei jedem Weckereignis wird die Mindestaktivzeit neu gestartet)";
CM_ SG_ 2600468500 NM_Kombi_NM_aktiv_VLW "Nachlaufursache des CAN. Es findet ein CAN Nachlauf für Dauer von max 5 Min statt, sofern Auslösebedingungen für die Verlassenswarnung (VLW) erfüllt sind. Die VLW ist im Kombi umgesetzt. Auslösebedingungen der VLW sind:
- Fahrzeugstillstand (v < 3km/h)
";
CM_ SG_ 2600468500 NM_Kombi_NM_State "1 = Zustand Repeat Message (<-- Bus-Sleep Mode)
2 = Zustand Repeat Message (<-- Prepare Bus-Sleep Mode)
4 = Zustand Normal Operation (<-- Repeat Message)
8 = Zustand Normal Operation (<-- Ready Sleep)";
CM_ SG_ 2600468500 NM_Kombi_UDS_CC "Funktionseinschränkung aufgrund aktivem UDS-Communication Control; siehe VW80124";

CM_ SG_ 527 NVEM_10_BZ "4bit Botschaftszähler, wird mit jeder Sendebotschaft inkrementiert";
CM_ SG_ 527 NVEM_10_CRC "Für MLB:
Berechnung siehe Lastenheft 'Kommunikationsabsicherung für FlexRay und CAN'
Ab MQB und MLBevo:
Berechnung siehe Lastenheft 'End-to-End Kommunikationsabsicherung'

Endwerte siehe Begleitdokument 'S-PDU Kennungsfolgen'";
CM_ SG_ 527 NVEM_DC_iSoll_NV "Soll-Entladestrom 12V Seite des DCDC Wandlers";
CM_ SG_ 527 NVEM_DC_uSoll_NV "Sollspannung 12V Seite des DC Wandlers, feine Auflösung";
CM_ SG_ 527 NVEM_IBatt "Strom der Bordnetzbatterie";
CM_ SG_ 527 NVEM_MOD_Budget "Füllstand des NV - Energie-Budgets für MD4";
CM_ SG_ 527 NVEM_MOD_Freigabe "Energiefreigabe für MOD  Funktionen";
CM_ SG_ 527 NVEM_MV_DC_iSoll_NV "Sollstromvorgabe NVEM an MV - DCDC Wandler";

CM_ SG_ 1630 OBD_TG_F_Status_1 "Fehlerstatus Tankfüllstandsgeber (OBD relevanter Sensor für Tankleckdiagnose)";
CM_ SG_ 1630 OBD_TG_F_Status_2 "Fehlerstatus Tankfüllstandsgeber (OBD relevanter Sensor für Tankleckdiagnose)

0x00 = kein Fehler / Init / nicht verbaut
0x01 = KS-
0x02 = KS+ (B8: nicht bedient)
0x03 = OC (Leitungsunterbrechung) (B8: nicht bedient)
0x04 = OOR+ (out of range high) ";
CM_ SG_ 1630 OBD_TG_F_Status_3 "Fehlerstatus Tankfüllstandsgeber (OBD relevanter Sensor für Tankleckdiagnose)

0x00 = kein Fehler / Init / nicht verbaut
0x01 = KS-
0x02 = KS+ (B8: nicht bedient)
0x03 = OC (Leitungsunterbrechung) (B8: nicht bedient)
0x04 = OOR+ (out of range high) ";
CM_ SG_ 1630 OBD_TG_F_Status_4 "Fehlerstatus Tankfüllstandsgeber (OBD relevanter Sensor für Tankleckdiagnose)

0x00 = kein Fehler / Init / nicht verbaut
0x01 = KS-
0x02 = KS+ (B8: nicht bedient)
0x03 = OC (Leitungsunterbrechung) (B8: nicht bedient)
0x04 = OOR+ (out of range high) ";
CM_ SG_ 1630 OBD_TG_Sens_Rohwert_1 "Rohwert des Tankgebers, nur gefiltert (gleitender Mittelwert), Ausgabe im 500ms-Raster";
CM_ SG_ 1630 OBD_TG_Sens_Rohwert_2 "Rohwert des Tankgebers, nur gefiltert (gleitender Mittelwert), Ausgabe im 500ms-Raster";
CM_ SG_ 1630 OBD_TG_Sens_Rohwert_3 "Rohwert des Tankgebers, nur gefiltert (gleitender Mittelwert), Ausgabe im 500ms-Raster";
CM_ SG_ 1630 OBD_TG_Sens_Rohwert_4 "Rohwert des Tankgebers, nur gefiltert (gleitender Mittelwert), Ausgabe im 500ms-Raster";

CM_ SG_ 2621440561 OBDC_ELV_Req_FD_Data "OnBoard Tester Diagnose Request ELV";

CM_ SG_ 2621571633 OBDC_ELV_Resp_FD_Data "OnBoard Tester Diagnose Response ELV";

CM_ SG_ 2549940736 OBDC_Funktionaler_Req_All_Data "VDC funktionaler Request auf CANHS";

CM_ SG_ 2621506048 OBDC_Funktion_Req_All_FD_Data "OnBoard Tester funktionaler Diagnose Request ALL";

CM_ SG_ 2621440539 OBDC_HUD_Req_FD_Data "OnBoard Tester Diagnose Request HUD";

CM_ SG_ 2621571611 OBDC_HUD_Resp_FD_Data "OnBoard Tester Diagnose Response HUD";

CM_ SG_ 2621440532 OBDC_Kombi_Req_FD_Data "OnBoard Tester Diagnose über ISO TP.";

CM_ SG_ 2621571604 OBDC_Kombi_Resp_FD_Data "OnBoard Tester Diagnose über ISO TP.";

CM_ SG_ 2549875364 OBDC_LSH_Req_Data "Onboard Diagnose";

CM_ SG_ 2550006436 OBDC_LSH_Resp_Data "Onboard Diagnose";

CM_ SG_ 2621440556 OBDC_MFG_Req_FD_Data "OnBoard Tester Diagnose Request MFG";

CM_ SG_ 2621571628 OBDC_MFG_Resp_FD_Data "OnBoard Tester Diagnose Response MFG";

CM_ SG_ 2549903375 OBDC_SSN_ABT_2_Req_Data "Request FID- zu NA- Kommunikation zw. OnboardDiagnoseClient und DK2F Sub-System-Knoten ABT_1";

CM_ SG_ 2550034447 OBDC_SSN_ABT_2_Resp_Data "Response FID- zu NA- Kommunikation zw. OnboardDiagnoseClient und DK2F Sub-System-Knoten ABT_1";

CM_ SG_ 2621440625 OBDC_TCO_Req_FD_Data "TP-Kanal für den Onboard Datensammler";

CM_ SG_ 2621571697 OBDC_TCO_Resp_FD_Data "TP-Kanal für den Onboard Datensammler";

CM_ SG_ 2550399502 OBDC_TRE_2_Req_Data "OnBoard Tester Diagnose Request TRE_2";

CM_ SG_ 2550530574 OBDC_TRE_2_Resp_Data "OnBoard Tester Diagnose Response TRE_2";

CM_ SG_ 2589284143 OBMI_DDrvRngRem "OBM Inducement System: der an das Kombi/MMI übermittelte Wert für die Restreichweite (einheitenlos) der OBM Inducement Fahrerinformation";
CM_ SG_ 2589284143 OBMI_FlgTrig "OBM Inducement System: der an das Kombi/MMI übermittelte Trigger zur Erneuerung der OBM Inducement Fahrerinformation";
CM_ SG_ 2589284143 OBMI_StAct "OBM Inducement System: der an das Kombi/MMI übermittelte Zustand der OBM Inducement Fahrerinformation";
CM_ SG_ 2589284143 OBMI_StDrvRngUnit "OBM Inducement System: die an das Kombi/MMI übermittelte Einheit für die Restreichweite (km oder mi) der OBM Inducement Fahrerinformation";

CM_ SG_ 2589283656 ORU_Status "Verteilung des internen ORU Zustandes";
CM_ SG_ 2589283656 ORU_Warnung "Wenn durch Störungen der Funktion Online Remote Update nicht sichergestellt ist, dass vor Kunde keine Funktionseinschränkungen auftreten, muss der Benutzer des Fahrzeugs entsprechend gewarnt werden.";

CM_ SG_ 1175 PDC_Tonausgabe_Front "In Abhängigkeit der Systemaktivitäten werden unterschiedliche Tonwarnungen ausgegeben. 
Kombi spielt entsprechende WAV.-Datei über internen Audiomaster ab.

0 = kein Ton
1 = Intervallton 1
2 = Intervallton 2
3 = Intervallton 3
4 = Intervallton 4
5";
CM_ SG_ 1175 PDC_Tonausgabe_Heck "In Abhängigkeit der Systemaktivitäten werden unterschiedliche Tonwarnungen ausgegeben. 
Kombi spielt entsprechende WAV.-Datei über internen Audiomaster ab.

0 = kein Ton
1 = Intervallton 1
2 = Intervallton 2
3 = Intervallton 3
4 = Intervallton 4
5";
CM_ SG_ 1175 PH_Abschaltursache "Abschaltursache bleibt bis zur nächsten Aktivierung bzw. bis KL15 aus gesetzt
Im Fehlerfall (blinkende LED) wird '7' gesendet obwohl das System noch aktiv ist, bei 'geheiltem' Fehler wird sofort wieder der Zustand '0' gesendet";
CM_ SG_ 1175 PH_Anf_Audioabsenkung "Es gibt zwei unterschiedliche Nachlauftimer für dieses Bit:
1. normale Funktion
2. Demotonausgabe";
CM_ SG_ 1175 PH_Anf_Verdeck "Anforderung an ein Verdeck-System, die vom Fahrer angeforderte Öffnung/Schließung zu verhindern";
CM_ SG_ 1175 PH_defekt "Zeigt an das sich die Parkhilfe im Fehlerzustand befindet. Signal bleibt bis zur nächsten 'Gut-Aktivierung' gesetzt.
Spezialfall: Sensordefekt hinten bei Anhängerbetrieb. Anhänger wird abgesteckt Fehler wird gesetzt. Fehlerfall bleibt bis Behebung des De";
CM_ SG_ 1175 PH_Display_Kundenwunsch "Anzeige der bei Aktivierung verwendeten Parameter bzgl. Kundenwunsch Displayanziege. Änderungen werden erst bei erneuter Aktivierung aktualisiert.";
CM_ SG_ 1175 PH_Frequenz_hinten "Uebertragung der aktuell im APS Steuergeraet gespeicherten Werte fuer Tongeber Frequenz hinten
Anzeige der aktuell verwendeten Parameter (nicht zwingend die abgespeicherten - da Werte erst 2s nach der letzten Änderung gespeichert werden!)";
CM_ SG_ 1175 PH_Frequenz_vorn "Uebertragung der aktuell im APS Steuergeraet gespeicherten Werte fuer Tongeber Frequenz vorne
Anzeige der aktuell verwendeten Parameter (nicht zwingend die abgespeicherten - da Werte erst 2s nach der letzten Änderung gespeichert werden!)";
CM_ SG_ 1175 PH_gestoert "Eine Störung ist aufgetreten, der die Parkhilfe in einen 'gestört-Zustand' versetzt, z.B. massiver Fremdultraschall, Vereisung, Schnee.Derzeit nur für Störschall benutzt, da keinerlei andere Erkennung implementiert.";
CM_ SG_ 1175 PH_Lautstaerke_hinten "Uebertragung der aktuell im APS Steuergeraet gespeicherten Werte fuer Tongeber Lautstaerke hinten
Anzeige der aktuell verwendeten Parameter (nicht zwingend die abgespeicherten - da Werte erst 2s nach der letzten Änderung gespeichert werden!)";
CM_ SG_ 1175 PH_Lautstaerke_vorn "Uebertragung der aktuell im APS Steuergeraet gespeicherten Werte fuer Tongeber Lautstaerke vorn.
Anzeige der aktuell verwendeten Parameter (nicht zwingend die abgespeicherten - da Werte erst 2s nach der letzten Änderung gespeichert werden!)";
CM_ SG_ 1175 PH_nachtr_Stopp_Anf "Dieses Signal dient dem Motor als Trigger, dass ein nachträglicher Motorstopp eingeleitet werden kann, wenn es die Bedingungen des StSt Koordinators dies zulassen. ";
CM_ SG_ 1175 PH_Opt_Anz_H_Hindernis "mindestens 1 Segment wird für den hinteren Detekionsbereich dargestellt, also ein Hindernis ist im Detektionsbereich. Funktion nur bei gesicherter Rückmeldung vom ASG gegeben.";
CM_ SG_ 1175 PH_Opt_Anz_V_Hindernis "mindestens 1 Segment wird für den vorderen Detekionsbereich dargestellt, also ein Hindernis ist im Detektionsbereich. Funktion nur bei gesicherter Rückmeldung vom ASG gegeben.";
CM_ SG_ 1175 PH_Opt_Anzeige_H_ein "OPS hinten ist im Display aktiv bzw. Anzeigemodule hinten sind eingeschaltet. Funktion nur bei gesicherter Rückmeldung vom ASG gegeben.";
CM_ SG_ 1175 PH_Opt_Anzeige_V_ein "OPS vorne ist im Display aktiv bzw. Anzeigemodule vorne sind eingeschaltet. Funktion nur bei gesicherter Rückmeldung vom ASG gegeben.";
CM_ SG_ 1175 PH_StartStopp_Info "Stopp-Freigabe und Start-Anforderung an den Start-Stopp-Koordinator";
CM_ SG_ 1175 PH_Stoermeldung "Meldung einer Störung der PDC an das Kombi";
CM_ SG_ 1175 PH_Systemzustand "Aktivierungsursache wird für die Dauer der Aktivierung gemeldet.
Im Fehlerfall bei atkviem System wechselt das Signal auf '7'
(siehe auch 'Abschaltursache')";
CM_ SG_ 1175 PH_Taster "Taster Status (für RVC/TopView)";
CM_ SG_ 1175 PH_Tongeber_H_aktiv "Rohsignal für 'Tongeber hinten wird angesteuert', verlängerbar mit Nachlauftimer.
Bit wird nicht während des Stellgliedtests angesteuert.";
CM_ SG_ 1175 PH_Tongeber_H_verfuegbar "Tongeber ist für die Tonausgabe für externe Funktionen verfügbar. PDC ist aktiv und Tongeber ist nicht gestört.";
CM_ SG_ 1175 PH_Tongeber_mute "Die Akustikausgabe des Systems wird unterdrückt, z.B. Wählhebel in 'P', Parlbremse geschlossen (8-Kanal-System)";
CM_ SG_ 1175 PH_Tongeber_V_aktiv "Rohsignal für 'Tongeber vorne wird angesteuert', verlängerbar mit Nachlauftimer.
Bit wird nicht während des Stellgliedtests angesteuert.";
CM_ SG_ 1175 PH_Visualisierung "Signal zeigt den Partnersteuergeräten RearView/TopView/ARA/... den aktuellen Status der Visualisierung des OPS. Die Partnersteuergeräte können dadurch auch ihre Aufschaltung an dieses Signal koppeln.";
CM_ SG_ 1175 PLA_Anf_Aufschaltung_RVC "Anforderung der Aufschaltung RVC durch PLA";

CM_ SG_ 1355 APS_PaCo_WarningTones "Signalisierung, ob seitens der Kundenfunktion APS eine akustische Warntonausgabe möglich ist.

0 Not_Possible: Akustische Tonausgabe derzeit nicht möglich
1 Possible: Akustische Tonausgabe derzeit möglich";
CM_ SG_ 1355 APSOPS_PaCo_ApproachingFront "Signalisierung einer Annäherung an ein kritisches Hindernis im vorderen Fahrzeugbereich.

0 No_Obstacle_Approaching: APSOPS erkennt kein Hindernis vor dem Fahrzeug
1 Obstacle_Approaching: APSOPS erkennt ein Hindernis vor dem Fahrzeug";
CM_ SG_ 1355 APSOPS_PaCo_ApproachingRear "Signalisierung einer Annäherung an ein kritisches Hindernis im hinteren Fahrzeugbereich.

0 No_Obstacle_Approaching: APSOPS erkennt kein Hindernis hinter dem Fahrzeug
1 Obstacle_Approaching: APSOPS erkennt ein Hindernis hinter dem Fahrzeug";
CM_ SG_ 1355 APSOPS_PaCo_Button "Signalisierung eines gedrückten PDC-Hardkeys.

0 Init_Or_Not_Equipped: Init oder kein PDC-Hardkey vorhanden
1 Button_Not_Pressed: PDC-Hardkey ist nicht gedrückt
2 Button_Pressed_Debounced: PDC-Hardkey ist gedrückt (entprellt)
3 Error: Fehler";
CM_ SG_ 1355 APSOPS_PaCo_FunctionState "Signalisierung des Funktionszustandes von APSOPS.

0 No_Error: es liegt kein Fehler von APSOPS vor
1 Sensor_Defect: es liegt ein Fehler aufgrund eines Sensordefekts von APSOPS vor, der über Teilverfügbarkeit abgehandelt warden kann
2 Sensor_Contaminat";
CM_ SG_ 1355 APSOPS_PaCo_MainState "Hauptzustand der Kundenfunktion APSOPS.

0 Init: APSOPS befindet sich in der Initialisierung
1 InOperation_NoError: APSOPS befindet sich im Betrieb ohne Fehler
7 Fehler: APSOPS befindet sich im Fehlerzustand";
CM_ SG_ 1355 APSOPS_PaCo_ObstacleDetectFront "Signalisierung, wenn im vorderen Fahrzeugbereich Hindernisse detektiert werden. Der vordere Fahrzeugbereich umfasst alle Hindernisse vor dem Fahrzeug bis zur Fahrzeugmitte und damit auch die beiden vorderen seitlichen Sektoren. Es wird immer der Signalzus";
CM_ SG_ 1355 APSOPS_PaCo_ObstacleDetectRear "Signalisierung, wenn im hinteren Fahrzeugbereich Hindernisse detektiert werden. Der hintere Fahrzeugbereich umfasst alle Hindernisse hinter dem Fahrzeug bis zur Fahrzeugmitte und damit auch die beiden hinteren seitlichen Sektoren. Es wird immer der Signal";
CM_ SG_ 1355 PH_Aufschaltursache "Der Grund für die Aufschaltung der Einparkhilfe wird angegeben, z.B. bei der Aktivierung der Einparkhilfe durch eine andere Funktion, wird diese Funktion als Aktivierungsursache für die Dauer der Aktivierung gemeldet.
Das Signal wird den PH_Systemzustand";
CM_ SG_ 1355 PH_Ton_Ausgabe "Anforderung einer Tonausgabe beim MIB3 durch die Parkhilfe";
CM_ SG_ 1355 PH_Ton_Lautstaerke "Wunschlautstärke der Tonanforderung beim MIB3 durch die Parkhilfe.";
CM_ SG_ 1355 PH_Ton_Pausenlaenge "Pause zwischen den angeforderten Tönen beim MIB3 durch die Parkhilfe. Nur für Intervalltöne, nicht relevant für Dauerton und Quittierungston.";
CM_ SG_ 1355 PH_Ton_Richtung "Abspielrichtung des angeforderten Ton beim MIB3 durch die Parkhilfe";
CM_ SG_ 1355 PH_Verschmutzungsmeldung "Meldung einer Verschmutzung/Vereisung der PDC an das Kombi";
CM_ SG_ 1355 PH_WAH_Meldung "Steuert die HMI-Meldungen im Kombi für den Wiederanfahrhinweis";
CM_ SG_ 1355 RAB_PaCo_FunctionState "Signalisierung des Funktionszustandes des RA";
CM_ SG_ 1355 RBF_Anf_Meldungen "Über das Signal werden die RBF Meldungen von der Funktion RBF am Kombi angefordert. Ursprünglich waren die Meldungen in der PLA_Status_02 Botschaft. Da RBF auch nur mit PDC einsetzt wird ein neuse  Signal benötigt.";
CM_ SG_ 1355 RBF_PaCo_Anf_Meldungen "Über das Signal werden die RBF Meldungen von der Funktion RBF über den PaCo beim Infotainment bzw. Kombi angefordert.";
CM_ SG_ 1355 RBF_PMO_Bereich_erkannt "Dieses Signal gibt zentralisiert eine Auswertung  des RBF relevanten PMO Bereichs wieder, sodass Systempartner Verhalten anpassen können, die ein gesondertes PMO Verhalten abbilden sollen";
CM_ SG_ 1355 RBFMA_PaCo_BrakeIntervention "Signalisierung, ob die Kundenfunktion RBF/MA einen Bremseingriff ansteuert.

0 Inactive: RBF/MA steuert derzeit keinen Bremseingriff an
1 Active_Rear: RBF/MA steuert derzeit einen Bremseingriff aufgrund eines Hindernisses hinten an
2 Active_Front: RBF";
CM_ SG_ 1355 RBFMA_PaCo_MainState "Hauptzustand der Kundenfunktion RBF/MA

0 Init: RBF/MA befindet sich in der Initialisierung
1 InOperation_NoError: RBF/MA befindet sich im Betrieb ohne Fehler
2 Eingeschraenkt
7 Fehler: RBF/MA befindet sich im Fehlerzustand";

CM_ SG_ 2527679498 IAA_Active_User_ID "Signal gibt die IAA Nutzer ID des aktiven IAA Nutzers an.";
CM_ SG_ 2527679498 IAA_Identified_User_ID "Signal gibt die IAA Nutzer ID des vom BCM identifizierten IAA Nutzers an";
CM_ SG_ 2527679498 IAA_PSO_wake_up "Signal zum Wake_up der IAA und PSO Komponenten im Kombi und in der OCU";
CM_ SG_ 2527679498 Perso_Aktiv "Status Personalisierung für den Fahrer aktiviert/ deaktiviert (via HMI)";
CM_ SG_ 2527679498 Perso_Bedienstelle "Signal zeigt an, über welche Bedienstelle die Umschaltung des Benutzerkontos gestartet wurden.";
CM_ SG_ 2527679498 Perso_Fahrernummer "Signal gibt die jewels aktuelle Nummer des Fahrers für die Personalisierung an.
Nicht für AU736 und AU48x.";
CM_ SG_ 2527679498 Perso_Freigabe_Verstellung "Signal zeigt an, ob die Ergonomiefunktionen nach Umschaltung des Benutzerkontos verfahren dürfen.";
CM_ SG_ 2527679498 Perso_Kontonummer "Signal gibt die jewels aktuelle Kontonummer für die Personalisierung an.
Nicht für AU736 und AU48x.";
CM_ SG_ 2527679498 Perso_Schreibschutz "Signal zeigt an, ob der Schreibschutz der Personalisierung aktiv ist.";
CM_ SG_ 2527679498 Perso_Status "Codierstatus der Personalisierung
Nicht für AU736 und AU49x.";
CM_ SG_ 2527679498 Perso_Steuerung "Signal gibt einen Steuerungsbefehl an die Funktionsteilnehmer der Personalisierung.
Nicht für AU736 und AU49x.";
CM_ SG_ 2527679498 Perso_Steuerungsparameter "Signal gibt einen Parameter zum Steuerungsbefehl (Signal Perso_Steuerung) für die Personalisierung an.
Nicht für AU736 und AU49x.";

CM_ SG_ 1166 PLA_Anf_Akustik "Anzeige, ob das PLA einen Gong im Kombi anfordert, Gong soll mit dem Übergang 0->1 abgespielt werden.";
CM_ SG_ 1166 PLA_Anf_Anzeige_Bremsfuss "Anzeige, ob PLA die Anzeige eines Bremsfusses anfordert";
CM_ SG_ 1166 PLA_Anf_Anzeige_Mini "Anforderung der Miniaturanzeige ";
CM_ SG_ 1166 PLA_Anf_Anzeige_Schwellpfeil "Anzeige, ob PLA im Kombi den Schwellpfeil zur Darstellung der Restwegstrecke im aktuellen Zug anfordert";
CM_ SG_ 1166 PLA_Anf_Anzeigemodus "Anzeigemodus das vom PLA je nach Parkszenario beim Kombi angefordert wird";
CM_ SG_ 1166 PLA_Anf_Meldungen "Anforderung der Meldungen:
0 - Keine Meldung
1-127 niederprio. Meldungen
128-255 hochprio. Meldungen";
CM_ SG_ 1166 PLA_Anforderung_HMS "Für die Anforderung der HMS Funktionen";
CM_ SG_ 1166 PLA_Anzahl_Segmente_Schwellpfeil "Wird ein Schwellpfeil angezeigt, gibt dieses Signal die Länge des breiten Balkens in Anzahl der Segmente (max. Länge: 15 Segmente).

Wird keine Anzeige der Schwellpfeile angefordert, muss die Anzahl Segmente 0 sein.";
CM_ SG_ 1166 PLA_Mini_Modus "Art des vom PLA zur Darstellung angeforderten Minis. Wird angezeigt, wenn PLA_Anf_Anzeige_Mini=1.";
CM_ SG_ 1166 PLA_Status_Aktive_Seite "Anzeige der zu parkenden Seite";
CM_ SG_ 1166 PLA_Status_beenden_Mini "Status Anzeige beendet Mini";
CM_ SG_ 1166 PLA_Status_Funktion "Funktionsstati, die die einzelnen Schritte innerhalb eines Parkszenarios anzeigen.";
CM_ SG_ 1166 PLA_Status_Laengsparken_Mini "Status Anzeige Längsparken Mini";
CM_ SG_ 1166 PLA_Status_QP_Rueckw_Mini "Status Anzeige Querparken rückwärts Mini";
CM_ SG_ 1166 PLA_Status_QP_Vorw_Mini "Status Anzeige Querparken vorwärtsMini";

CM_ SG_ 319 PreCrash_Anforderung_AFR "Anforderungen der Funktion PrecrashSeite an Fahrwerksregelung";
CM_ SG_ 319 PreCrash_BFS_KSV_verfahren "Ansteuerung der Kopfstuetze Beifahrerseite durch die Funktion PreCrash

Signalwert 0x09 für vereinfachte Ansteuerung mit Logik im Sitz-SG (MQB37W)";
CM_ SG_ 319 PreCrash_BFS_Laengsverstellung "Ansteuerung der Laengsverstellung des Beifahrersitzes durch die PreCrash-Funktionen";
CM_ SG_ 319 PreCrash_BFS_Pneumatik_ansteuern "Ansteuerung des Beifahrersitzes durch die PreCrash-Funktionen";
CM_ SG_ 319 PreCrash_BFS_Sitzlehne_verfahren "Ansteuerung des Beifahrersitzes durch die PreCrash-Funktionen

Wert 0x06 und 0x07 für vereinfachte Ansteuerung Sitzlehne";
CM_ SG_ 319 PreCrash_Blinken "Safety Computer übermittelt Blinkverhalten bei einer PreCrash-Auslösung an den BCM2";
CM_ SG_ 319 PreCrash_Charisma_FahrPr "Aktuell eingestelltes Fahrprogramm der Funktion PreCrash";
CM_ SG_ 319 PreCrash_Charisma_Status "Verfügbarkeit der Funktion PreCrash für die Ansteuerung durch den Charisma_Koordinator";
CM_ SG_ 319 PreCrash_Fenster_schliessen "Anforderung Seitenscheiben schließen durch die Funktion PreCrash";
CM_ SG_ 319 PreCrash_Fo_KSV_verfahren "Ansteuerung der Kopfstuetzen im Fond durch die PreCrash-Funktionen";
CM_ SG_ 319 PreCrash_Fo_Pneumatik_ansteuern "Ansteuerung der Fondsitze durch die PreCrash-Funktionen";
CM_ SG_ 319 PreCrash_Fo_Sitzlehne_verfahren "Ansteuerung des Fondsitzes durch die PreCrash-Funktionen";
CM_ SG_ 319 PreCrash_FS_KSV_verfahren "Ansteuerung der Kopfstuetze Fahrerseite durch die PreCrash-Funktionen

Signalwert 0x09 für vereinfachte Ansteuerung mit Logik im Sitz-SG (MQB37W)";
CM_ SG_ 319 PreCrash_FS_Laengsverstellung "Ansteuerung der Laengsverstellung des Fahrersitzes durch die PreCrash-Funktionen";
CM_ SG_ 319 PreCrash_FS_Pneumatik_ansteuern "Ansteuerung des Fahrersitzes durch die PreCrash-Funktionen";
CM_ SG_ 319 PreCrash_FS_Sitzlehne_verfahren "Ansteuerung des Fahrersitzes durch die PreCrash-Funktionen

Wert 0x06 und 0x07 für vereinfachte Ansteuerung Sitzlehne";
CM_ SG_ 319 PreCrash_Schiebedach_schliessen "Anforderung Schiebedach schließen durch die Funktion PreCrash";
CM_ SG_ 319 PreCrash_Tueren_Verriegeln "Anforderung Türen Verriegeln durch die Funktion PreCrash";
CM_ SG_ 319 SC_PreCrash_LED "Ansteuerung LED-Leiste im Kombi durch SC";
CM_ SG_ 319 SC_PreCrash_Texte "Safety Computer übermittelt Systemstatus der PreCrash Funktionen an Kombi";
CM_ SG_ 319 SC_PreCrash_Warnung "Safety Computer übermittelt Warnung der PreCrash Funktionen an Kombi";
CM_ SG_ 319 SC_PreSense_FCWP "Mitteilung an das NightVision, auf welche Art von Objekt eine Warnung angefordert wird";

CM_ SG_ 1122 PSD_Abzweigerichtung "Richtung, in der die Abzweigung von der Hauptroute abzweigt
";
CM_ SG_ 1122 PSD_Abzweigewinkel "Winkel, unter dem die Abzweigung von der Hauptroute abzweigt.
";
CM_ SG_ 1122 PSD_ADAS_Qualitaet "ADAS Qualtität des Streckensegments.";
CM_ SG_ 1122 PSD_Anfangskruemmung "Startkrümmung der Klothoide des übermittelten abzweigenden Streckensegments. 
1/(1+0.155 * x^2) {1/m}'
";
CM_ SG_ 1122 PSD_Anfangskruemmung_Vorz "Vorzeichen für die Startkrümmung bei Abzweigungen
";
CM_ SG_ 1122 PSD_Bebauung "Segement befindet sich innerhalb bebauten Gebietes";
CM_ SG_ 1122 PSD_Endkruemmung "'Endkrümmung der Klotoide des übermittelten Streckensegments. Die Anfangskrümmung des folgenden Streckensegments entspricht der Endkrümmung dieses Segments. Krümmung = 1/(1+0.155 * x²) [1/m]

";
CM_ SG_ 1122 PSD_Fahrspuren_Anzahl "Anzahl der Fahrspuren in Fahrtrichtung
";
CM_ SG_ 1122 PSD_Geradester_Pfad "Segment ist Teil des geradesten Pfades";
CM_ SG_ 1122 PSD_Idenditaets_ID "Identifier auf ein Streckensegment, dass mit dem aktuell übertragenen geometrisch identisch ist.";
CM_ SG_ 1122 PSD_Segment_ID "Identifier des prädiktiven Streckensegments
";
CM_ SG_ 1122 PSD_Segment_Komplett "Zeigt, ob alle Attribute für das Segment übertragen worden sind
";
CM_ SG_ 1122 PSD_Segmentlaenge "Gesamtlänge des prädiktiven Streckensegments";
CM_ SG_ 1122 PSD_Strassenkategorie "Klassifizierung der Straße des beschriebenen Segments
";
CM_ SG_ 1122 PSD_Vorgaenger_Segment_ID "An dem Streckensegment mit diesem Identifier schließt sich das neue Segment mit der ID 'PSD_01_Segment_ID' an.
";
CM_ SG_ 1122 PSD_wahrscheinlichster_Pfad "Identifiziert den vom Navigationssystem berechneten wahrscheinlichsten Pfad des Fahrzeuges. ";

CM_ SG_ 1123 PSD_Attribut_1_ID "Identifier des ersten Attributes";
CM_ SG_ 1123 PSD_Attribut_1_Offset "Positionsoffset im Segment für die Position des Attributs";
CM_ SG_ 1123 PSD_Attribut_1_Wert "Wert des ersten Attributes";
CM_ SG_ 1123 PSD_Attribut_2_ID "Identifier des zweiten Attributes";
CM_ SG_ 1123 PSD_Attribut_2_Offset "Positionsoffset im Segment für die Position des Attributs";
CM_ SG_ 1123 PSD_Attribut_2_Wert "Wert des zweiten Attributes";
CM_ SG_ 1123 PSD_Attribut_Segment_ID_05 "Identifier des Streckensegments, für das die weiteren Attribute in der Botschaft gültig sind";
CM_ SG_ 1123 PSD_Attribute_Komplett_05 "Zeigt, ob alle Attribute für das Segment übertragen worden sind";
CM_ SG_ 1123 PSD_Pos_Fahrspur "Spur, auf der sich das Fahrzeug aktuell befindet";
CM_ SG_ 1123 PSD_Pos_Fehler_Laengsrichtung "Laengsfehler der Positionierung";
CM_ SG_ 1123 PSD_Pos_Inhibitzeit "Zeitspanne zwischen Generierung der PSD Daten im Navigationssystem und Versand der Daten auf den Most
";
CM_ SG_ 1123 PSD_Pos_Segment_ID "Identifier des Streckensegments, auf dem sich das Fahrzeug aktuell befindet
";
CM_ SG_ 1123 PSD_Pos_Segmentlaenge "Verbleibende Länge des Streckensegments, auf dem sich das Fahrzeug aktuell befindet
";
CM_ SG_ 1123 PSD_Pos_Standort_Eindeutig "Ist die Position des Fahrzeugs eindeutig dem aktuelle Segment zugeordnet, oder gibt es fahrbare alternative Segmente, die bei akteller GPS-Position ebenfalls als aktuelles Segment möglich wären.";

CM_ SG_ 1124 PSD_06_Mux "Multiplex Zähler für die PSD_06-Botschaft.
Die unterschiedlichen Muxe folgen keiner festen Reihenfolge. Je nach Inhalt des PSD-Protokolls an der aktuellen Position werden jeweils die notwendigen PSD6-Botschaften gesendet.";
CM_ SG_ 1124 PSD_Attribut_3_ID "Identifier des dritten Attributes";
CM_ SG_ 1124 PSD_Attribut_3_Offset "Positionsoffset im Segment für die Position des Attributs";
CM_ SG_ 1124 PSD_Attribut_3_Wert "Wert des dritten Attributes";
CM_ SG_ 1124 PSD_Attribut_4_ID "Typ von Attribut 4";
CM_ SG_ 1124 PSD_Attribut_4_Offset "Offset von Attribut 4";
CM_ SG_ 1124 PSD_Attribut_4_Wert "Wert von Attribut 4";
CM_ SG_ 1124 PSD_Attribut_5_ID "Typ von Attribut 5";
CM_ SG_ 1124 PSD_Attribut_5_Offset "Offset von Attribut 5";
CM_ SG_ 1124 PSD_Attribut_5_Wert "Wert von Attribut 5";
CM_ SG_ 1124 PSD_Attribut_Segment_ID "Identifier des Streckensegments,für das die weiteren Attribute in der Botschaft gültig sind";
CM_ SG_ 1124 PSD_Attribute_Komplett_06 "Zeigt, ob alle Attribute für das Segment übertragen worden sind
";
CM_ SG_ 1124 PSD_Baum_Ausrichtung "Ausrichtung des Fahrzeugsegments zu Nord";
CM_ SG_ 1124 PSD_Baum_Breite "WGS84 Breite des Fahrzeugsegments";
CM_ SG_ 1124 PSD_Baum_Breite_VZ "Vorzeichen WGS84 Breite des Fahrzeugsegments";
CM_ SG_ 1124 PSD_Baum_Laenge "WGS84 Laenge des Fahrzeugsegments";
CM_ SG_ 1124 PSD_Baum_Laenge_VZ "Vorzeichen WGS84 Laenge des Fahrzeugsegments";
CM_ SG_ 1124 PSD_Ges_Attribute_Komplett "Zeigt, ob alle Attribute für das Segment übertragen worden sind";
CM_ SG_ 1124 PSD_Ges_Geschwindigkeit_Gespann "Gilt diese Einschränkung der Geschwindigkeit für alle Fahrzeuge oder ausschließlich für PKW mit Gespann oder für LKW, Buss, etc.";
CM_ SG_ 1124 PSD_Ges_Geschwindigkeit_Std_Anf "Stunde, zu der die stündliche Geschwindigkeitsbegrenzung beginnt
0h.. 24h";
CM_ SG_ 1124 PSD_Ges_Geschwindigkeit_Std_Ende "Stunde, an der die stündliche Geschwindigkeitsbegrenzung endet
0h.. 24h";
CM_ SG_ 1124 PSD_Ges_Geschwindigkeit_Tag_Anf "Wochentag, an dem die tägliche Geschwindigkeitsbegrenzung beginnt";
CM_ SG_ 1124 PSD_Ges_Geschwindigkeit_Tag_Ende "Wochentag, an dem die tägliche Geschwindigkeitsbegrenzung endet";
CM_ SG_ 1124 PSD_Ges_Geschwindigkeit_Witter "Witterungsabhängigkeit der Geschwindigkeitsbegrenzung";
CM_ SG_ 1124 PSD_Ges_Gesetzlich_Kategorie "Kategorie für das legale Gebot";
CM_ SG_ 1124 PSD_Ges_Gesetzlich_Zusatz "Zusatz für das legale Gebot";
CM_ SG_ 1124 PSD_Ges_Offset "Positionsoffset im Segment für die Position des Attributs";
CM_ SG_ 1124 PSD_Ges_Segment_ID "Identifier des prädiktiven Streckensegments ab dem die Geschwindigkeitsbegrenzungen und mögliche Einschränkungen gelten.
";
CM_ SG_ 1124 PSD_Ges_Spur_Geschw_Begrenzung "Definition der Spuren, für die das übertragene Gebot gilt";
CM_ SG_ 1124 PSD_Ges_Typ "Typ der Geschwindigkeitsbegrenzung
";
CM_ SG_ 1124 PSD_Ges_Verkehrszeichen_Quelle "Quelle der Verkehrszeicheninformation";
CM_ SG_ 1124 PSD_Ges_Wechselverkehrszeichen "Am Beginn des Segments ist ein Wechselverkehrszeichen angebracht.";
CM_ SG_ 1124 PSD_Steigung_1_A_Offset "Positionsoffset im Segment für die Position der Steigung 1 A";
CM_ SG_ 1124 PSD_Steigung_1_A_Steigung "Steigung des Segments ab Offset 1A";
CM_ SG_ 1124 PSD_Steigung_1_A_Vorz "Vorzeichen für Steigung 1 A";
CM_ SG_ 1124 PSD_Steigung_1_Attribute_kompl "Alle Steigungsdaten für dieses Segment gesendet";
CM_ SG_ 1124 PSD_Steigung_1_B_Offset "Positionsoffset im Segment für die Position der Steigung 1 B";
CM_ SG_ 1124 PSD_Steigung_1_B_Steigung "Steigung des Segments ab Offset 1B";
CM_ SG_ 1124 PSD_Steigung_1_B_Vorz "Vorzeichen für Steigung 1 B";
CM_ SG_ 1124 PSD_Steigung_1_Segment_ID "Identifier des prädiktiven Streckensegments, zu dem die  ersten beiden Steigungswerte dieser Botschaft gehören";
CM_ SG_ 1124 PSD_Steigung_2_Attribute_kompl "Alle Steigungsdaten für dieses Segment gesendet";
CM_ SG_ 1124 PSD_Steigung_2_Offset "Positionsoffset im Segment für die Position der Steigung 2";
CM_ SG_ 1124 PSD_Steigung_2_Segment_ID "Identifier des prädiktiven Streckensegments, zu dem der dritte Steigungswert dieser Botschaft gehört";
CM_ SG_ 1124 PSD_Steigung_2_Steigung "Steigung des Segments ab Offset 2";
CM_ SG_ 1124 PSD_Steigung_2_Vorz "Vorzeichen für Steigung 2";
CM_ SG_ 1124 PSD_Sys_Alter_Karte "Alter der Karte";
CM_ SG_ 1124 PSD_Sys_Geometrieguete "Maß für die Güte der Klothoidengeometrie.";
CM_ SG_ 1124 PSD_Sys_Geometrieguete_erweitert "Güte der Kurvenrepräsentation der Klothoiden";
CM_ SG_ 1124 PSD_Sys_Geschwindigkeit_Einheit "Unterscheidung zwischen km/h und miles/h";
CM_ SG_ 1124 PSD_Sys_Laendercode "Ländercode";
CM_ SG_ 1124 PSD_Sys_Mapmatchingguete "Güte des Mapmatchings";
CM_ SG_ 1124 PSD_Sys_Quali_Geometrien "Qualität der Geometrien in dieser Region";
CM_ SG_ 1124 PSD_Sys_Quali_Ortsinfo "Qualität Ortsinformationen (Bebauung, Ortsschild) dieser Region";
CM_ SG_ 1124 PSD_Sys_Quali_sonstige_Attribute "Qualität sonstiger Attribute dieser Region";
CM_ SG_ 1124 PSD_Sys_Quali_Steigungen "Qualität der Steigungen dieser Region";
CM_ SG_ 1124 PSD_Sys_Quali_Strassenkennz "Qualität Straßenkennzeichnungen dieser Region";
CM_ SG_ 1124 PSD_Sys_Quali_Tempolimits "Qualität Tempolimits dieser Region";
CM_ SG_ 1124 PSD_Sys_Quali_verfuegbar "Karte enthält gültige Qualitätskriterien";
CM_ SG_ 1124 PSD_Sys_Quali_Vorfahrtsregelung "Qualität Vorfahrtsregelungen dieser Region";
CM_ SG_ 1124 PSD_Sys_Segment_ID "Identifier des prädiktiven Streckensegments ab dem die Systeminformationen gültig sind.
";
CM_ SG_ 1124 PSD_Sys_US_State "Name des USA-State";
CM_ SG_ 1124 PSD_Sys_Verkehrsrichtung "Unterscheidung zwischen Linksverkehr und Rechtsverkehr";
CM_ SG_ 1124 PSD_Sys_Zielfuehrung "Zielfuehrung im Navigationssystem. Damit lässt sich der wahrscheinlichste Pfad des Fahrzeuges zuverlässig angeben.";
CM_ SG_ 1124 PSD_Sys_Zielfuehrung_geaendert "Die Zielführung (Route) hat sich geändert hat ohne dass der Fahrer eine neue Zielführung gestartet hat";
CM_ SG_ 1124 PSD_Wechselverkehrszeichen_Typ "Typ des Wechselverkehrszeichen";

CM_ SG_ 1023 Quersperre_04_BZ "4bit Botschaftszähler, wird mit jeder Sendebotschaft inkrementiert";
CM_ SG_ 1023 Quersperre_04_CRC "Für MLB:
Berechnung siehe Lastenheft 'Kommunikationsabsicherung für FlexRay und CAN'
Ab MQB und MLBevo:
Berechnung siehe Lastenheft 'End-to-End Kommunikationsabsicherung'

Endwerte siehe Begleitdokument 'S-PDU Kennungsfolgen'";
CM_ SG_ 1023 Quersperre_Anz_Sperre_Auslegen "Kombianzeige: Sperre wird ausgelegt";
CM_ SG_ 1023 Quersperre_Anz_Sperre_Einlegen "Kombianzeige: Sperre wird eingelegt";
CM_ SG_ 1023 Quersperre_Anz_Sperre_Geschl "Kombianzeige: Sperre geschlossen";
CM_ SG_ 1023 Quersperre_Istzustand "Zustand der Quersperre
Ein- und Auslegen wird als 'geschlossen' interpretiert.";
CM_ SG_ 1023 Quersperre_Status "Gibt den Status der hinteren Querssperre für andere Systeme an.";

CM_ SG_ 1529 RDK_angelernt "RDK signalisiert, dass die Radelektroniken angelernt sind und das Kombi den Rundstreckenmodus anbieten kann.";
CM_ SG_ 1529 RDK_FMVSS138_Lampe "Ansteuerung der RDK-Lampe im Kombi bei Druckwarnung";
CM_ SG_ 1529 RDK_FMVSS138_MIL "Ansteuerung der RDK-Lampe im Kombi bei Systemstörung.
RDK-Lampe muss für 65 Sekunden blinken und anschliessend dauerhaft leuchten bis RDK dieses Bit wieder auf '0' setzt (Wiedergutprüfung).
Hinweis:  Im AU48x blinken für 60 Sekunden";
CM_ SG_ 1529 RDK_Kalibrierung "Art der Vorgabe der Solldrücke
0x0 Vorgabe der Solldrücke erfolgt durch eine Reifenauswahl in der Headunit
0x1 Vorgabe der Solldrücke erfolgt durch Betätigung des SET-Tasters des Kombiinstruments";
CM_ SG_ 1529 RDK_Reifendruck_Lampe "Ansteuerung einer RDK-Lampe im Kombi bei einem problematischen Druck";
CM_ SG_ 1529 RDK_Reifentemperatur_Lampe "Ansteuerung einer RDK-Lampe im Kombi bei einer problematischen Reifentemperatur";
CM_ SG_ 1529 RDK_RS_aktiv "Rundstreckenmodus inaktiv/ aktiv";
CM_ SG_ 1529 RDK_Text_7 "Textausgabe 7: Mindestdruck für Rundstreckenmode unterschritten";
CM_ SG_ 1529 RDK_W_1_Reifen_HL "Harte Warnung fuer Reifen hinten links";
CM_ SG_ 1529 RDK_W_1_Reifen_HR "Harte Warnung fuer Reifen hinten rechts";
CM_ SG_ 1529 RDK_W_1_Reifen_VL "Harte Warnung fuer Reifen vorne links";
CM_ SG_ 1529 RDK_W_1_Reifen_VR "Harte Warnung fuer Reifen vorne rechts";
CM_ SG_ 1529 RDK_W_2_Reifen_HL "Weiche Warnung fuer Reifen hinten links";
CM_ SG_ 1529 RDK_W_2_Reifen_HR "Weiche Warnung fuer Reifen hinten rechts";
CM_ SG_ 1529 RDK_W_2_Reifen_VL "Weiche Warnung fuer Reifen vorne links";
CM_ SG_ 1529 RDK_W_2_Reifen_VR "Weiche Warnung fuer Reifen vorne rechts";
CM_ SG_ 1529 RDK_Warnungen_02 "Ausgabe von Texten/Akustik im Kombiinstrument";
BA_DEF_REL_ BU_SG_REL_  "GenSigTimeoutTime" INT 0 65535;
BA_DEF_ BO_  "DiagRequest" ENUM "No", "Yes";
BA_DEF_ BO_  "DiagResponse" ENUM "No", "Yes";
BA_DEF_ BO_  "DiagState" ENUM "No", "Yes";
BA_DEF_ BO_  "GenMsgChkConstant" HEX 0 4095;
BA_DEF_ BO_  "GenMsgCycleTime" INT 0 65535;
BA_DEF_ BO_  "GenMsgCycleTimeFast" INT 0 65535;
BA_DEF_ BO_  "GenMsgDelayTime" INT 0 100000;
BA_DEF_ BO_  "GenMsgILSupport" ENUM "No", "Yes";
BA_DEF_ BO_  "GenMsgNrOfRepetition" INT 0 100;
BA_DEF_ BO_  "GenMsgPDUConstants" STRING;
BA_DEF_ BO_  "GenMsgSendType" ENUM "Cyclic", "not_used", "not_used", "not_used", "not_used", "not_used", "not_used", "IfActive", "NoMsgSendType";
BA_DEF_ BO_  "GenMsgStartDelayTime" INT 0 100000;
BA_DEF_ BO_  "NmMessage" ENUM "No", "Yes";
BA_DEF_ BO_  "NmhMessage" ENUM "No", "Yes";
BA_DEF_ BO_  "MsgType" ENUM "Application", "NM ", "NMH", "TP2.0", "ISO-TP ", "BAP", "EID", "KS", "XCP_PRE_CONFIGURED", "XCP_RUNTIME_CONFIGURED";
BA_DEF_ BO_  "VAGTP20_API" HEX 0 255;
BA_DEF_ BO_  "VAGTP20_DynConnection" ENUM "No", "Yes";
BA_DEF_ BO_  "VAGTP20_DynSetup" ENUM "No", "Yes";
BA_DEF_ BO_  "VAGTP20_StatConnection" ENUM "No", "Yes";
BA_DEF_ BO_  "CANFD_BRS" ENUM "0", "1";
BA_DEF_ BO_  "VFrameFormat" ENUM "StandardCAN", "ExtendedCAN", "reserved", "reserved", "reserved", "reserved", "reserved", "reserved", "reserved", "reserved", "reserved", "reserved", "reserved", "reserved", "StandardCAN_FD", "ExtendedCAN_FD";
BA_DEF_ SG_  "GenSigActiveRepetitions" INT -2147483648 2147483647;
BA_DEF_ SG_  "GenSigInactiveValue" INT -2147483648 2147483647;
BA_DEF_ SG_  "GenSigSendType" ENUM "Cyclic", "OnWrite", "OnWriteWithRepetition", "OnChange", "OnChangeWithRepetition", "IfActive", "IfActiveWithRepetition", "NoSigSendType", "OnChangeAndIfActive", "OnChangeAndIfActiveWithRepetition";
BA_DEF_ SG_  "GenSigStartValue" INT -2147483648 2147483647;
BA_DEF_ SG_  "NWM-WakeupAllowed" ENUM "No", "Yes";
BA_DEF_ SG_  "GenSigFuncType" ENUM "NoFunction", "MsgCounter", "CRC-8", "XOR", "XOR-2", "DatedBit", "SW-Kl15", "CHK", "Constant", "Protocol", "CRC-8-SAE_J1850", "CRC-32", "DataLength", "DataID", "MsgCounter16", "SOK-Signatur", "Cluster";
BA_DEF_ SG_  "GenSigSwitchedByIgnition" ENUM "No", "Yes";
BA_DEF_ SG_  "Fehlerwert" HEX 0 2147483647;
BA_DEF_ SG_  "GenSigMissingSourceValue" HEX 0 2147483647;
BA_DEF_DEF_REL_  "GenSigTimeoutTime" 0;
BA_DEF_DEF_  "DiagRequest" "No";
BA_DEF_DEF_  "DiagResponse" "No";
BA_DEF_DEF_  "DiagState" "No";
BA_DEF_DEF_  "GenMsgChkConstant" 0;
BA_DEF_DEF_  "GenMsgCycleTime" 0;
BA_DEF_DEF_  "GenMsgCycleTimeFast" 0;
BA_DEF_DEF_  "GenMsgDelayTime" 0;
BA_DEF_DEF_  "GenMsgILSupport" "No";
BA_DEF_DEF_  "GenMsgNrOfRepetition" 0;
BA_DEF_DEF_  "GenMsgPDUConstants" "";
BA_DEF_DEF_  "GenMsgSendType" "NoMsgSendType";
BA_DEF_DEF_  "GenMsgStartDelayTime" 0;
BA_DEF_DEF_  "NmMessage" "No";
BA_DEF_DEF_  "NmhMessage" "No";
BA_DEF_DEF_  "MsgType" "Application";
BA_DEF_DEF_  "VAGTP20_API" 0;
BA_DEF_DEF_  "VAGTP20_DynConnection" "No";
BA_DEF_DEF_  "VAGTP20_DynSetup" "No";
BA_DEF_DEF_  "VAGTP20_StatConnection" "No";
BA_DEF_DEF_  "CANFD_BRS" "1";
BA_DEF_DEF_  "VFrameFormat" "StandardCAN";
BA_DEF_DEF_  "GenSigActiveRepetitions" 0;
BA_DEF_DEF_  "GenSigInactiveValue" 0;
BA_DEF_DEF_  "GenSigSendType" "NoSigSendType";
BA_DEF_DEF_  "GenSigStartValue" 0;
BA_DEF_DEF_  "NWM-WakeupAllowed" "No";
BA_DEF_DEF_  "GenSigFuncType" "NoFunction";
BA_DEF_DEF_  "GenSigSwitchedByIgnition" "Yes";
BA_DEF_DEF_  "Fehlerwert" 0;
BA_DEF_DEF_  "GenSigMissingSourceValue" 0;
BA_ "GenMsgCycleTime" BO_ 2331595982 50;
BA_ "GenMsgILSupport" BO_ 2331595982 1;
BA_ "GenMsgSendType" BO_ 2331595982 0;
BA_ "VFrameFormat" BO_ 2331595982 15;
BA_ "GenMsgCycleTime" BO_ 2589283946 500;
BA_ "GenMsgILSupport" BO_ 2589283946 1;
BA_ "GenMsgSendType" BO_ 2589283946 0;
BA_ "VFrameFormat" BO_ 2589283946 15;
BA_ "GenMsgChkConstant" BO_ 1601 71;
BA_ "GenMsgCycleTime" BO_ 1601 1000;
BA_ "GenMsgILSupport" BO_ 1601 1;
BA_ "GenMsgPDUConstants" BO_ 1601 "0x47,0x47,0x47,0x47,0x47,0x47,0x47,0x47,0x47,0x47,0x47,0x47,0x47,0x47,0x47,0x47";
BA_ "GenMsgSendType" BO_ 1601 0;
BA_ "VFrameFormat" BO_ 1601 14;
BA_ "GenMsgCycleTime" BO_ 391 100;
BA_ "GenMsgDelayTime" BO_ 391 40;
BA_ "GenMsgILSupport" BO_ 391 1;
BA_ "GenMsgPDUConstants" BO_ 391 "0x7f,0xed,0x17,0xc2,0x7c,0xeb,0x44,0x21,0x01,0xfa,0xdb,0x15,0x4a,0x6b,0x23,0x05";
BA_ "GenMsgSendType" BO_ 391 0;
BA_ "VFrameFormat" BO_ 391 14;
BA_ "GenMsgCycleTime" BO_ 813 50;
BA_ "GenMsgILSupport" BO_ 813 1;
BA_ "GenMsgSendType" BO_ 813 0;
BA_ "VFrameFormat" BO_ 813 14;
BA_ "GenMsgCycleTime" BO_ 1155 500;
BA_ "GenMsgDelayTime" BO_ 1155 50;
BA_ "GenMsgILSupport" BO_ 1155 1;
BA_ "GenMsgSendType" BO_ 1155 0;
BA_ "VFrameFormat" BO_ 1155 14;
BA_ "GenMsgCycleTime" BO_ 1284 100;
BA_ "GenMsgDelayTime" BO_ 1284 10;
BA_ "GenMsgILSupport" BO_ 1284 1;
BA_ "GenMsgPDUConstants" BO_ 1284 "0x03,0x63,0x3e,0x04,0xf9,0xb4,0x4f,0x32,0x25,0x56,0x1e,0xc1,0x83,0xfa,0x31,0x97";
BA_ "GenMsgSendType" BO_ 1284 0;
BA_ "VFrameFormat" BO_ 1284 14;
BA_ "MsgType" BO_ 2583737729 4;
BA_ "VFrameFormat" BO_ 2583737729 15;
BA_ "MsgType" BO_ 2583868801 4;
BA_ "VFrameFormat" BO_ 2583868801 15;
BA_ "GenMsgCycleTime" BO_ 1156 200;
BA_ "GenMsgILSupport" BO_ 1156 1;
BA_ "GenMsgSendType" BO_ 1156 0;
BA_ "VFrameFormat" BO_ 1156 14;
BA_ "GenMsgCycleTime" BO_ 1157 200;
BA_ "GenMsgILSupport" BO_ 1157 1;
BA_ "GenMsgSendType" BO_ 1157 0;
BA_ "VFrameFormat" BO_ 1157 14;
BA_ "GenMsgCycleTime" BO_ 1158 200;
BA_ "GenMsgILSupport" BO_ 1158 1;
BA_ "GenMsgSendType" BO_ 1158 0;
BA_ "VFrameFormat" BO_ 1158 14;
BA_ "GenMsgCycleTime" BO_ 2600468529 200;
BA_ "GenMsgCycleTimeFast" BO_ 2600468529 10;
BA_ "NmhMessage" BO_ 2600468529 1;
BA_ "MsgType" BO_ 2600468529 2;
BA_ "CANFD_BRS" BO_ 2600468529 0;
BA_ "VFrameFormat" BO_ 2600468529 1;
BA_ "GenMsgCycleTime" BO_ 2600468496 200;
BA_ "GenMsgCycleTimeFast" BO_ 2600468496 10;
BA_ "NmhMessage" BO_ 2600468496 1;
BA_ "MsgType" BO_ 2600468496 2;
BA_ "CANFD_BRS" BO_ 2600468496 0;
BA_ "VFrameFormat" BO_ 2600468496 1;
BA_ "GenMsgCycleTime" BO_ 2600468507 200;
BA_ "GenMsgCycleTimeFast" BO_ 2600468507 10;
BA_ "NmhMessage" BO_ 2600468507 1;
BA_ "MsgType" BO_ 2600468507 2;
BA_ "CANFD_BRS" BO_ 2600468507 0;
BA_ "VFrameFormat" BO_ 2600468507 1;
BA_ "GenMsgCycleTime" BO_ 2600468500 200;
BA_ "GenMsgCycleTimeFast" BO_ 2600468500 10;
BA_ "NmhMessage" BO_ 2600468500 1;
BA_ "MsgType" BO_ 2600468500 2;
BA_ "CANFD_BRS" BO_ 2600468500 0;
BA_ "VFrameFormat" BO_ 2600468500 1;
BA_ "GenMsgCycleTime" BO_ 527 50;
BA_ "GenMsgILSupport" BO_ 527 1;
BA_ "GenMsgPDUConstants" BO_ 527 "0xd4,0x22,0xad,0x3f,0x25,0xaa,0x62,0x5b,0xdc,0x73,0xed,0xc3,0x9a,0x14,0x2f,0x3e";
BA_ "GenMsgSendType" BO_ 527 0;
BA_ "VFrameFormat" BO_ 527 14;
BA_ "GenMsgCycleTime" BO_ 1630 500;
BA_ "GenMsgILSupport" BO_ 1630 1;
BA_ "GenMsgSendType" BO_ 1630 0;
BA_ "VFrameFormat" BO_ 1630 14;
BA_ "DiagRequest" BO_ 2621440561 1;
BA_ "MsgType" BO_ 2621440561 4;
BA_ "VFrameFormat" BO_ 2621440561 15;
BA_ "DiagResponse" BO_ 2621571633 1;
BA_ "MsgType" BO_ 2621571633 4;
BA_ "VFrameFormat" BO_ 2621571633 15;
BA_ "DiagState" BO_ 2549940736 1;
BA_ "MsgType" BO_ 2549940736 4;
BA_ "VFrameFormat" BO_ 2549940736 15;
BA_ "DiagState" BO_ 2621506048 1;
BA_ "MsgType" BO_ 2621506048 4;
BA_ "VFrameFormat" BO_ 2621506048 15;
BA_ "DiagRequest" BO_ 2621440539 1;
BA_ "MsgType" BO_ 2621440539 4;
BA_ "VFrameFormat" BO_ 2621440539 15;
BA_ "DiagResponse" BO_ 2621571611 1;
BA_ "MsgType" BO_ 2621571611 4;
BA_ "VFrameFormat" BO_ 2621571611 15;
BA_ "DiagRequest" BO_ 2621440532 1;
BA_ "MsgType" BO_ 2621440532 4;
BA_ "VFrameFormat" BO_ 2621440532 15;
BA_ "DiagResponse" BO_ 2621571604 1;
BA_ "MsgType" BO_ 2621571604 4;
BA_ "VFrameFormat" BO_ 2621571604 15;
BA_ "DiagRequest" BO_ 2549875364 1;
BA_ "MsgType" BO_ 2549875364 4;
BA_ "VFrameFormat" BO_ 2549875364 15;
BA_ "DiagResponse" BO_ 2550006436 1;
BA_ "MsgType" BO_ 2550006436 4;
BA_ "VFrameFormat" BO_ 2550006436 15;
BA_ "DiagRequest" BO_ 2621440556 1;
BA_ "MsgType" BO_ 2621440556 4;
BA_ "VFrameFormat" BO_ 2621440556 15;
BA_ "DiagResponse" BO_ 2621571628 1;
BA_ "MsgType" BO_ 2621571628 4;
BA_ "VFrameFormat" BO_ 2621571628 15;
BA_ "DiagRequest" BO_ 2549903375 1;
BA_ "MsgType" BO_ 2549903375 4;
BA_ "VFrameFormat" BO_ 2549903375 15;
BA_ "DiagResponse" BO_ 2550034447 1;
BA_ "MsgType" BO_ 2550034447 4;
BA_ "VFrameFormat" BO_ 2550034447 15;
BA_ "DiagRequest" BO_ 2621440625 1;
BA_ "MsgType" BO_ 2621440625 4;
BA_ "VFrameFormat" BO_ 2621440625 15;
BA_ "DiagResponse" BO_ 2621571697 1;
BA_ "MsgType" BO_ 2621571697 4;
BA_ "VFrameFormat" BO_ 2621571697 15;
BA_ "DiagRequest" BO_ 2550399502 1;
BA_ "MsgType" BO_ 2550399502 4;
BA_ "VFrameFormat" BO_ 2550399502 15;
BA_ "DiagResponse" BO_ 2550530574 1;
BA_ "MsgType" BO_ 2550530574 4;
BA_ "VFrameFormat" BO_ 2550530574 15;
BA_ "GenMsgCycleTime" BO_ 2589284143 1000;
BA_ "GenMsgILSupport" BO_ 2589284143 1;
BA_ "GenMsgSendType" BO_ 2589284143 0;
BA_ "VFrameFormat" BO_ 2589284143 15;
BA_ "GenMsgCycleTime" BO_ 2589283656 500;
BA_ "GenMsgDelayTime" BO_ 2589283656 100;
BA_ "GenMsgILSupport" BO_ 2589283656 1;
BA_ "GenMsgSendType" BO_ 2589283656 0;
BA_ "VFrameFormat" BO_ 2589283656 15;
BA_ "GenMsgCycleTime" BO_ 1175 100;
BA_ "GenMsgDelayTime" BO_ 1175 50;
BA_ "GenMsgILSupport" BO_ 1175 1;
BA_ "GenMsgSendType" BO_ 1175 0;
BA_ "VFrameFormat" BO_ 1175 14;
BA_ "GenMsgCycleTime" BO_ 1355 500;
BA_ "GenMsgDelayTime" BO_ 1355 20;
BA_ "GenMsgILSupport" BO_ 1355 1;
BA_ "GenMsgSendType" BO_ 1355 0;
BA_ "VFrameFormat" BO_ 1355 14;
BA_ "GenMsgCycleTime" BO_ 2527679498 1000;
BA_ "GenMsgCycleTimeFast" BO_ 2527679498 200;
BA_ "GenMsgDelayTime" BO_ 2527679498 50;
BA_ "GenMsgILSupport" BO_ 2527679498 1;
BA_ "GenMsgNrOfRepetition" BO_ 2527679498 3;
BA_ "GenMsgSendType" BO_ 2527679498 0;
BA_ "VFrameFormat" BO_ 2527679498 15;
BA_ "GenMsgCycleTime" BO_ 1166 100;
BA_ "GenMsgILSupport" BO_ 1166 1;
BA_ "GenMsgSendType" BO_ 1166 0;
BA_ "VFrameFormat" BO_ 1166 14;
BA_ "GenMsgCycleTime" BO_ 319 200;
BA_ "GenMsgDelayTime" BO_ 319 20;
BA_ "GenMsgILSupport" BO_ 319 1;
BA_ "GenMsgPDUConstants" BO_ 319 "0x28,0x6e,0x5a,0xc6,0x52,0x65,0x85,0xa1,0xb8,0xe6,0x38,0x88,0xf8,0xb9,0x2b,0xb0";
BA_ "GenMsgSendType" BO_ 319 0;
BA_ "VFrameFormat" BO_ 319 14;
BA_ "GenMsgCycleTime" BO_ 1122 150;
BA_ "GenMsgILSupport" BO_ 1122 1;
BA_ "GenMsgSendType" BO_ 1122 0;
BA_ "VFrameFormat" BO_ 1122 14;
BA_ "GenMsgCycleTime" BO_ 1123 150;
BA_ "GenMsgILSupport" BO_ 1123 1;
BA_ "GenMsgSendType" BO_ 1123 0;
BA_ "VFrameFormat" BO_ 1123 14;
BA_ "GenMsgCycleTime" BO_ 1124 150;
BA_ "GenMsgILSupport" BO_ 1124 1;
BA_ "GenMsgSendType" BO_ 1124 0;
BA_ "VFrameFormat" BO_ 1124 14;
BA_ "GenMsgCycleTime" BO_ 1023 500;
BA_ "GenMsgDelayTime" BO_ 1023 50;
BA_ "GenMsgILSupport" BO_ 1023 1;
BA_ "GenMsgPDUConstants" BO_ 1023 "0x06,0xdf,0xf9,0x15,0xb0,0xd5,0x92,0x25,0x13,0x27,0xd8,0x61,0x83,0x9d,0x24,0x73";
BA_ "GenMsgSendType" BO_ 1023 0;
BA_ "VFrameFormat" BO_ 1023 14;
BA_ "GenMsgCycleTime" BO_ 1529 500;
BA_ "GenMsgILSupport" BO_ 1529 1;
BA_ "GenMsgSendType" BO_ 1529 0;
BA_ "VFrameFormat" BO_ 1529 14;
BA_ "GenSigSendType" SG_ 2331595982 PTHyDrA_PrctUtilElDrv 0;
BA_ "GenSigStartValue" SG_ 2331595982 PTHyDrA_PrctUtilElDrv 2047;
BA_ "GenSigSwitchedByIgnition" SG_ 2331595982 PTHyDrA_PrctUtilElDrv 0;
BA_ "GenSigSendType" SG_ 2331595982 PTHyDrA_StAcv 0;
BA_ "GenSigStartValue" SG_ 2331595982 PTHyDrA_StAcv 3;
BA_ "GenSigSwitchedByIgnition" SG_ 2331595982 PTHyDrA_StAcv 0;
BA_ "GenSigSendType" SG_ 2331595982 PTUIPwrm_FacPwrDyn 0;
BA_ "GenSigStartValue" SG_ 2331595982 PTUIPwrm_FacPwrDyn 127;
BA_ "GenSigSwitchedByIgnition" SG_ 2331595982 PTUIPwrm_FacPwrDyn 0;
BA_ "GenSigSendType" SG_ 2331595982 PTUIPwrm_PrctBoostAvl 0;
BA_ "GenSigStartValue" SG_ 2331595982 PTUIPwrm_PrctBoostAvl 1023;
BA_ "GenSigSwitchedByIgnition" SG_ 2331595982 PTUIPwrm_PrctBoostAvl 0;
BA_ "GenSigSendType" SG_ 2331595982 PTUIPwrm_PrctPwrEcoMaxUse 0;
BA_ "GenSigStartValue" SG_ 2331595982 PTUIPwrm_PrctPwrEcoMaxUse 2047;
BA_ "GenSigSwitchedByIgnition" SG_ 2331595982 PTUIPwrm_PrctPwrEcoMaxUse 0;
BA_ "GenSigSendType" SG_ 2331595982 PTUIPwrm_PrctPwrElBoostCur 0;
BA_ "GenSigStartValue" SG_ 2331595982 PTUIPwrm_PrctPwrElBoostCur 1023;
BA_ "GenSigSwitchedByIgnition" SG_ 2331595982 PTUIPwrm_PrctPwrElBoostCur 0;
BA_ "GenSigSendType" SG_ 2331595982 PTUIPwrm_PrctPwrElBoostMaxUse 0;
BA_ "GenSigStartValue" SG_ 2331595982 PTUIPwrm_PrctPwrElBoostMaxUse 1023;
BA_ "GenSigSwitchedByIgnition" SG_ 2331595982 PTUIPwrm_PrctPwrElBoostMaxUse 0;
BA_ "GenSigSendType" SG_ 2331595982 PTUIPwrm_PrctPwrElDrvCur 0;
BA_ "GenSigStartValue" SG_ 2331595982 PTUIPwrm_PrctPwrElDrvCur 4095;
BA_ "GenSigSwitchedByIgnition" SG_ 2331595982 PTUIPwrm_PrctPwrElDrvCur 0;
BA_ "GenSigSendType" SG_ 2331595982 PTUIPwrm_PrctPwrGnrMaxUse 0;
BA_ "GenSigStartValue" SG_ 2331595982 PTUIPwrm_PrctPwrGnrMaxUse 2047;
BA_ "GenSigSwitchedByIgnition" SG_ 2331595982 PTUIPwrm_PrctPwrGnrMaxUse 0;
BA_ "GenSigSendType" SG_ 2331595982 PTUIPwrm_PrctPwrMotElMaxUse 0;
BA_ "GenSigStartValue" SG_ 2331595982 PTUIPwrm_PrctPwrMotElMaxUse 2047;
BA_ "GenSigSwitchedByIgnition" SG_ 2331595982 PTUIPwrm_PrctPwrMotElMaxUse 0;
BA_ "GenSigSendType" SG_ 2331595982 PTUIPwrm_PrctPwrMotMaxUse 0;
BA_ "GenSigStartValue" SG_ 2331595982 PTUIPwrm_PrctPwrMotMaxUse 2047;
BA_ "GenSigSwitchedByIgnition" SG_ 2331595982 PTUIPwrm_PrctPwrMotMaxUse 0;
BA_ "GenSigSendType" SG_ 2331595982 PTUIPwrm_PrctPwrSysCur 0;
BA_ "GenSigStartValue" SG_ 2331595982 PTUIPwrm_PrctPwrSysCur 4095;
BA_ "GenSigSwitchedByIgnition" SG_ 2331595982 PTUIPwrm_PrctPwrSysCur 0;
BA_ "GenSigSendType" SG_ 2331595982 PTUIPwrm_PrctPwrSysMaxUseTemp 0;
BA_ "GenSigStartValue" SG_ 2331595982 PTUIPwrm_PrctPwrSysMaxUseTemp 2047;
BA_ "GenSigSwitchedByIgnition" SG_ 2331595982 PTUIPwrm_PrctPwrSysMaxUseTemp 0;
BA_ "GenSigSendType" SG_ 2331595982 PTUIPwrm_PwrElBoostNom 0;
BA_ "GenSigStartValue" SG_ 2331595982 PTUIPwrm_PwrElBoostNom 1023;
BA_ "GenSigSwitchedByIgnition" SG_ 2331595982 PTUIPwrm_PwrElBoostNom 0;
BA_ "GenSigSendType" SG_ 2331595982 PTUIPwrm_StAcv 0;
BA_ "GenSigStartValue" SG_ 2331595982 PTUIPwrm_StAcv 3;
BA_ "GenSigSwitchedByIgnition" SG_ 2331595982 PTUIPwrm_StAcv 0;
BA_ "GenSigSendType" SG_ 2589283946 PTUIPwrm_PwrGnrNom 0;
BA_ "GenSigStartValue" SG_ 2589283946 PTUIPwrm_PwrGnrNom 2047;
BA_ "GenSigSwitchedByIgnition" SG_ 2589283946 PTUIPwrm_PwrGnrNom 0;
BA_ "GenSigSendType" SG_ 2589283946 PTUIPwrm_PwrMotElNom 0;
BA_ "GenSigStartValue" SG_ 2589283946 PTUIPwrm_PwrMotElNom 2047;
BA_ "GenSigSwitchedByIgnition" SG_ 2589283946 PTUIPwrm_PwrMotElNom 0;
BA_ "GenSigSendType" SG_ 2589283946 PTUIPwrm_PwrSysMotNomDisp 0;
BA_ "GenSigStartValue" SG_ 2589283946 PTUIPwrm_PwrSysMotNomDisp 2047;
BA_ "GenSigSwitchedByIgnition" SG_ 2589283946 PTUIPwrm_PwrSysMotNomDisp 0;
BA_ "GenSigSendType" SG_ 1601 MO_Ansaugsystem 0;
BA_ "GenSigFuncType" SG_ 1601 MO_Ansaugsystem 8;
BA_ "GenSigSwitchedByIgnition" SG_ 1601 MO_Ansaugsystem 0;
BA_ "GenSigSendType" SG_ 1601 MO_Anzahl_Zyl 0;
BA_ "GenSigFuncType" SG_ 1601 MO_Anzahl_Zyl 8;
BA_ "GenSigSwitchedByIgnition" SG_ 1601 MO_Anzahl_Zyl 0;
BA_ "GenSigSendType" SG_ 1601 MO_Anzeige_StSt_gueltig 0;
BA_ "GenSigSwitchedByIgnition" SG_ 1601 MO_Anzeige_StSt_gueltig 0;
BA_ "GenSigSendType" SG_ 1601 MO_Code 0;
BA_ "GenSigSwitchedByIgnition" SG_ 1601 MO_Code 0;
BA_ "GenSigSendType" SG_ 1601 MO_DPF_verbaut 0;
BA_ "GenSigFuncType" SG_ 1601 MO_DPF_verbaut 8;
BA_ "GenSigSwitchedByIgnition" SG_ 1601 MO_DPF_verbaut 0;
BA_ "GenSigSendType" SG_ 1601 MO_Faktor_Momente_02 0;
BA_ "GenSigFuncType" SG_ 1601 MO_Faktor_Momente_02 8;
BA_ "GenSigSwitchedByIgnition" SG_ 1601 MO_Faktor_Momente_02 0;
BA_ "GenSigSendType" SG_ 1601 MO_Getriebe_Code 0;
BA_ "GenSigSwitchedByIgnition" SG_ 1601 MO_Getriebe_Code 0;
BA_ "GenSigSendType" SG_ 1601 MO_Hubraum 0;
BA_ "GenSigFuncType" SG_ 1601 MO_Hubraum 8;
BA_ "GenSigSwitchedByIgnition" SG_ 1601 MO_Hubraum 0;
BA_ "GenSigSendType" SG_ 1601 MO_Hybridfahrzeug 0;
BA_ "GenSigFuncType" SG_ 1601 MO_Hybridfahrzeug 8;
BA_ "GenSigSwitchedByIgnition" SG_ 1601 MO_Hybridfahrzeug 0;
BA_ "GenSigSendType" SG_ 1601 MO_Kraftstoffart 0;
BA_ "GenSigFuncType" SG_ 1601 MO_Kraftstoffart 8;
BA_ "GenSigSwitchedByIgnition" SG_ 1601 MO_Kraftstoffart 0;
BA_ "GenSigSendType" SG_ 1601 MO_Leistung 0;
BA_ "GenSigSwitchedByIgnition" SG_ 1601 MO_Leistung 0;
BA_ "GenSigSendType" SG_ 1601 MO_OBD_Typ 0;
BA_ "GenSigSwitchedByIgnition" SG_ 1601 MO_OBD_Typ 0;
BA_ "GenSigSendType" SG_ 1601 MO_StartStopp_Codiert 0;
BA_ "GenSigFuncType" SG_ 1601 MO_StartStopp_Codiert 8;
BA_ "GenSigSwitchedByIgnition" SG_ 1601 MO_StartStopp_Codiert 0;
BA_ "GenSigSendType" SG_ 1601 Motor_Code_01_BZ 0;
BA_ "GenSigFuncType" SG_ 1601 Motor_Code_01_BZ 1;
BA_ "GenSigSwitchedByIgnition" SG_ 1601 Motor_Code_01_BZ 0;
BA_ "GenSigSendType" SG_ 1601 Motor_Code_01_CRC 0;
BA_ "GenSigFuncType" SG_ 1601 Motor_Code_01_CRC 2;
BA_ "GenSigSwitchedByIgnition" SG_ 1601 Motor_Code_01_CRC 0;
BA_ "GenSigSendType" SG_ 1601 TSK_Codierung 0;
BA_ "GenSigStartValue" SG_ 1601 TSK_Codierung 7;
BA_ "GenSigSwitchedByIgnition" SG_ 1601 TSK_Codierung 0;
BA_ "GenSigSendType" SG_ 391 EV_Rekuperationsstufe 0;
BA_ "GenSigSwitchedByIgnition" SG_ 391 EV_Rekuperationsstufe 0;
BA_ "GenSigSendType" SG_ 391 MO_Drehzahl_VM 0;
BA_ "GenSigSwitchedByIgnition" SG_ 391 MO_Drehzahl_VM 0;
BA_ "GenSigSendType" SG_ 391 MO_Fehler_Notabschaltung_Klima 3;
BA_ "GenSigSwitchedByIgnition" SG_ 391 MO_Fehler_Notabschaltung_Klima 0;
BA_ "GenSigSendType" SG_ 391 MO_Fehler_NTKreis 0;
BA_ "GenSigSwitchedByIgnition" SG_ 391 MO_Fehler_NTKreis 0;
BA_ "Fehlerwert" SG_ 391 MO_Fehler_NTKreis 1;
BA_ "GenSigSendType" SG_ 391 MO_KLE_FStatus 0;
BA_ "GenSigSwitchedByIgnition" SG_ 391 MO_KLE_FStatus 0;
BA_ "Fehlerwert" SG_ 391 MO_KLE_FStatus 3;
BA_ "GenSigSendType" SG_ 391 MO_Tankbereitschaft_Status 0;
BA_ "GenSigSwitchedByIgnition" SG_ 391 MO_Tankbereitschaft_Status 0;
BA_ "GenSigSendType" SG_ 391 MO_Tankklappensteuerung 0;
BA_ "GenSigSwitchedByIgnition" SG_ 391 MO_Tankklappensteuerung 0;
BA_ "GenSigSendType" SG_ 391 MO_Waehlpos 3;
BA_ "GenSigSwitchedByIgnition" SG_ 391 MO_Waehlpos 0;
BA_ "Fehlerwert" SG_ 391 MO_Waehlpos 7;
BA_ "GenSigSendType" SG_ 391 MO_WH_Texte 3;
BA_ "GenSigSwitchedByIgnition" SG_ 391 MO_WH_Texte 0;
BA_ "GenSigSendType" SG_ 391 Motor_EV_01_BZ 0;
BA_ "GenSigFuncType" SG_ 391 Motor_EV_01_BZ 1;
BA_ "GenSigSwitchedByIgnition" SG_ 391 Motor_EV_01_BZ 0;
BA_ "GenSigSendType" SG_ 391 Motor_EV_01_CRC 0;
BA_ "GenSigFuncType" SG_ 391 Motor_EV_01_CRC 2;
BA_ "GenSigSwitchedByIgnition" SG_ 391 Motor_EV_01_CRC 0;
BA_ "GenSigSendType" SG_ 813 MO_akt_Betrieb 0;
BA_ "GenSigSwitchedByIgnition" SG_ 813 MO_akt_Betrieb 0;
BA_ "GenSigSendType" SG_ 813 MO_AnzeigeGasbetrieb 0;
BA_ "GenSigSwitchedByIgnition" SG_ 813 MO_AnzeigeGasbetrieb 0;
BA_ "GenSigSendType" SG_ 813 MO_CNG_LPG 0;
BA_ "GenSigSwitchedByIgnition" SG_ 813 MO_CNG_LPG 0;
BA_ "GenSigSwitchedByIgnition" SG_ 813 MO_CNG_Tankstopp 0;
BA_ "GenSigSwitchedByIgnition" SG_ 813 MO_CNG_Ueberlauf 0;
BA_ "GenSigSendType" SG_ 813 MO_Erdgasqualitaet 0;
BA_ "GenSigSwitchedByIgnition" SG_ 813 MO_Erdgasqualitaet 0;
BA_ "GenSigSwitchedByIgnition" SG_ 813 MO_Fuellstand_LPG 0;
BA_ "Fehlerwert" SG_ 813 MO_Fuellstand_LPG 1023;
BA_ "GenSigStartValue" SG_ 813 MO_Fuellungsgrad_CNG 254;
BA_ "GenSigSwitchedByIgnition" SG_ 813 MO_Fuellungsgrad_CNG 0;
BA_ "Fehlerwert" SG_ 813 MO_Fuellungsgrad_CNG 255;
BA_ "GenSigStartValue" SG_ 813 MO_Fuellungsgrad_LPG 254;
BA_ "GenSigSwitchedByIgnition" SG_ 813 MO_Fuellungsgrad_LPG 0;
BA_ "Fehlerwert" SG_ 813 MO_Fuellungsgrad_LPG 255;
BA_ "GenSigSwitchedByIgnition" SG_ 813 MO_LPG_Tankstopp 0;
BA_ "GenSigSwitchedByIgnition" SG_ 813 MO_LPG_Ueberlauf 0;
BA_ "GenSigSwitchedByIgnition" SG_ 813 MO_Tankmasse_CNG 0;
BA_ "Fehlerwert" SG_ 813 MO_Tankmasse_CNG 255;
BA_ "GenSigSwitchedByIgnition" SG_ 813 MO_Tankvolumen_LPG 0;
BA_ "Fehlerwert" SG_ 813 MO_Tankvolumen_LPG 255;
BA_ "GenSigSwitchedByIgnition" SG_ 813 MO_Verbrauch_CNG 0;
BA_ "GenSigSwitchedByIgnition" SG_ 813 MO_Verbrauch_LPG 0;
BA_ "GenSigSendType" SG_ 813 MO_Verbrauchsaequivalent 0;
BA_ "GenSigStartValue" SG_ 813 MO_Verbrauchsaequivalent 254;
BA_ "GenSigSwitchedByIgnition" SG_ 813 MO_Verbrauchsaequivalent 0;
BA_ "Fehlerwert" SG_ 813 MO_Verbrauchsaequivalent 255;
BA_ "GenSigSendType" SG_ 1155 MO_Powermeter_Charge_Grenze 3;
BA_ "GenSigStartValue" SG_ 1155 MO_Powermeter_Charge_Grenze 1022;
BA_ "GenSigSwitchedByIgnition" SG_ 1155 MO_Powermeter_Charge_Grenze 0;
BA_ "Fehlerwert" SG_ 1155 MO_Powermeter_Charge_Grenze 1023;
BA_ "GenSigSendType" SG_ 1155 Mo_Powermeter_Grenze 3;
BA_ "GenSigStartValue" SG_ 1155 Mo_Powermeter_Grenze 4093;
BA_ "GenSigSwitchedByIgnition" SG_ 1155 Mo_Powermeter_Grenze 0;
BA_ "GenSigSendType" SG_ 1155 MO_Powermeter_Grenze_strategisch 3;
BA_ "GenSigStartValue" SG_ 1155 MO_Powermeter_Grenze_strategisch 4094;
BA_ "GenSigSwitchedByIgnition" SG_ 1155 MO_Powermeter_Grenze_strategisch 0;
BA_ "Fehlerwert" SG_ 1155 MO_Powermeter_Grenze_strategisch 4095;
BA_ "GenSigSendType" SG_ 1155 MO_Powermeter_Inszenierung_aktiv 3;
BA_ "GenSigSwitchedByIgnition" SG_ 1155 MO_Powermeter_Inszenierung_aktiv 0;
BA_ "GenSigSendType" SG_ 1155 MO_Powermeter_obere_E_Grenze 3;
BA_ "GenSigStartValue" SG_ 1155 MO_Powermeter_obere_E_Grenze 4094;
BA_ "GenSigSwitchedByIgnition" SG_ 1155 MO_Powermeter_obere_E_Grenze 0;
BA_ "Fehlerwert" SG_ 1155 MO_Powermeter_obere_E_Grenze 4095;
BA_ "GenSigSendType" SG_ 1155 MO_Powermeter_untere_E_Grenze 3;
BA_ "GenSigStartValue" SG_ 1155 MO_Powermeter_untere_E_Grenze 4094;
BA_ "GenSigSwitchedByIgnition" SG_ 1155 MO_Powermeter_untere_E_Grenze 0;
BA_ "Fehlerwert" SG_ 1155 MO_Powermeter_untere_E_Grenze 4095;
BA_ "GenSigSendType" SG_ 1284 MV_Bordnetz_aktiv 0;
BA_ "GenSigSwitchedByIgnition" SG_ 1284 MV_Bordnetz_aktiv 0;
BA_ "GenSigSendType" SG_ 1284 MV_Bordnetz_belastbar 3;
BA_ "GenSigSwitchedByIgnition" SG_ 1284 MV_Bordnetz_belastbar 0;
BA_ "GenSigSendType" SG_ 1284 MV_Bordnetz_Fehler 3;
BA_ "GenSigSwitchedByIgnition" SG_ 1284 MV_Bordnetz_Fehler 0;
BA_ "Fehlerwert" SG_ 1284 MV_Bordnetz_Fehler 1;
BA_ "GenSigSendType" SG_ 1284 MVK_01_BZ 0;
BA_ "GenSigFuncType" SG_ 1284 MVK_01_BZ 1;
BA_ "GenSigSwitchedByIgnition" SG_ 1284 MVK_01_BZ 0;
BA_ "GenSigSendType" SG_ 1284 MVK_01_CRC 0;
BA_ "GenSigFuncType" SG_ 1284 MVK_01_CRC 2;
BA_ "GenSigSwitchedByIgnition" SG_ 1284 MVK_01_CRC 0;
BA_ "GenSigSendType" SG_ 1284 MVK_BMS_Sollmodus 3;
BA_ "GenSigStartValue" SG_ 1284 MVK_BMS_Sollmodus 7;
BA_ "GenSigSwitchedByIgnition" SG_ 1284 MVK_BMS_Sollmodus 0;
BA_ "GenSigSendType" SG_ 1284 MVK_BOOST_Sollmodus 3;
BA_ "GenSigStartValue" SG_ 1284 MVK_BOOST_Sollmodus 7;
BA_ "GenSigSwitchedByIgnition" SG_ 1284 MVK_BOOST_Sollmodus 0;
BA_ "GenSigSendType" SG_ 1284 MVK_DCDC_Sollmodus 3;
BA_ "GenSigStartValue" SG_ 1284 MVK_DCDC_Sollmodus 7;
BA_ "GenSigSwitchedByIgnition" SG_ 1284 MVK_DCDC_Sollmodus 0;
BA_ "GenSigSendType" SG_ 1284 MVK_DCDC_Sollmodus_02 3;
BA_ "GenSigStartValue" SG_ 1284 MVK_DCDC_Sollmodus_02 7;
BA_ "GenSigSwitchedByIgnition" SG_ 1284 MVK_DCDC_Sollmodus_02 0;
BA_ "GenSigSendType" SG_ 1284 MVK_eABC_Sollmodus 3;
BA_ "GenSigStartValue" SG_ 1284 MVK_eABC_Sollmodus 7;
BA_ "GenSigSwitchedByIgnition" SG_ 1284 MVK_eABC_Sollmodus 0;
BA_ "GenSigSendType" SG_ 1284 MVK_eAWS_Sollmodus 3;
BA_ "GenSigStartValue" SG_ 1284 MVK_eAWS_Sollmodus 7;
BA_ "GenSigSwitchedByIgnition" SG_ 1284 MVK_eAWS_Sollmodus 0;
BA_ "GenSigSendType" SG_ 1284 MVK_Istmodus_Anf 3;
BA_ "GenSigSwitchedByIgnition" SG_ 1284 MVK_Istmodus_Anf 0;
BA_ "GenSigSendType" SG_ 1284 MVK_MO_EmSollzustand 3;
BA_ "GenSigStartValue" SG_ 1284 MVK_MO_EmSollzustand 255;
BA_ "GenSigSwitchedByIgnition" SG_ 1284 MVK_MO_EmSollzustand 0;
BA_ "GenSigSendType" SG_ 1284 MVK_MV_Batteriewarnung 3;
BA_ "GenSigSwitchedByIgnition" SG_ 1284 MVK_MV_Batteriewarnung 0;
BA_ "GenSigSendType" SG_ 1284 MVK_MV_Netz_Warnungen 3;
BA_ "GenSigSwitchedByIgnition" SG_ 1284 MVK_MV_Netz_Warnungen 0;
BA_ "GenSigSendType" SG_ 1284 MVK_MVPTC_Sollmodus 3;
BA_ "GenSigStartValue" SG_ 1284 MVK_MVPTC_Sollmodus 7;
BA_ "GenSigSwitchedByIgnition" SG_ 1284 MVK_MVPTC_Sollmodus 0;
BA_ "GenSigSendType" SG_ 2583737729 NAD_AuthTime_SSN_Req_Data 3;
BA_ "GenSigFuncType" SG_ 2583737729 NAD_AuthTime_SSN_Req_Data 9;
BA_ "GenSigSwitchedByIgnition" SG_ 2583737729 NAD_AuthTime_SSN_Req_Data 0;
BA_ "GenSigSendType" SG_ 2583868801 NAD_AuthTime_SSN_Resp_Data 3;
BA_ "GenSigFuncType" SG_ 2583868801 NAD_AuthTime_SSN_Resp_Data 9;
BA_ "GenSigSwitchedByIgnition" SG_ 2583868801 NAD_AuthTime_SSN_Resp_Data 0;
BA_ "GenSigSendType" SG_ 1156 ND_GDOP 0;
BA_ "GenSigStartValue" SG_ 1156 ND_GDOP 254;
BA_ "GenSigSwitchedByIgnition" SG_ 1156 ND_GDOP 0;
BA_ "Fehlerwert" SG_ 1156 ND_GDOP 1023;
BA_ "GenSigSendType" SG_ 1156 ND_HDOP 0;
BA_ "GenSigStartValue" SG_ 1156 ND_HDOP 1022;
BA_ "GenSigSwitchedByIgnition" SG_ 1156 ND_HDOP 0;
BA_ "Fehlerwert" SG_ 1156 ND_HDOP 1023;
BA_ "GenSigSendType" SG_ 1156 ND_Heading 0;
BA_ "GenSigStartValue" SG_ 1156 ND_Heading 1022;
BA_ "GenSigSwitchedByIgnition" SG_ 1156 ND_Heading 0;
BA_ "Fehlerwert" SG_ 1156 ND_Heading 4095;
BA_ "GenSigSendType" SG_ 1156 ND_Init 0;
BA_ "GenSigSwitchedByIgnition" SG_ 1156 ND_Init 0;
BA_ "GenSigSendType" SG_ 1156 ND_PDOP 0;
BA_ "GenSigStartValue" SG_ 1156 ND_PDOP 1022;
BA_ "GenSigSwitchedByIgnition" SG_ 1156 ND_PDOP 0;
BA_ "Fehlerwert" SG_ 1156 ND_PDOP 1023;
BA_ "GenSigSendType" SG_ 1156 ND_TDOP 0;
BA_ "GenSigStartValue" SG_ 1156 ND_TDOP 1022;
BA_ "GenSigSwitchedByIgnition" SG_ 1156 ND_TDOP 0;
BA_ "Fehlerwert" SG_ 1156 ND_TDOP 1023;
BA_ "GenSigSendType" SG_ 1156 ND_VDOP 0;
BA_ "GenSigStartValue" SG_ 1156 ND_VDOP 1022;
BA_ "GenSigSwitchedByIgnition" SG_ 1156 ND_VDOP 0;
BA_ "Fehlerwert" SG_ 1156 ND_VDOP 1023;
BA_ "GenSigSendType" SG_ 1157 ND_SatInUse 0;
BA_ "GenSigStartValue" SG_ 1157 ND_SatInUse 30;
BA_ "GenSigSwitchedByIgnition" SG_ 1157 ND_SatInUse 0;
BA_ "Fehlerwert" SG_ 1157 ND_SatInUse 31;
BA_ "GenSigSendType" SG_ 1157 ND_SatInView 0;
BA_ "GenSigStartValue" SG_ 1157 ND_SatInView 30;
BA_ "GenSigSwitchedByIgnition" SG_ 1157 ND_SatInView 0;
BA_ "Fehlerwert" SG_ 1157 ND_SatInView 31;
BA_ "GenSigSendType" SG_ 1157 ND_UTC 0;
BA_ "GenSigStartValue" SG_ 1157 ND_UTC 1022;
BA_ "GenSigSwitchedByIgnition" SG_ 1157 ND_UTC 0;
BA_ "GenSigSendType" SG_ 1157 NP_Altitude 0;
BA_ "GenSigStartValue" SG_ 1157 NP_Altitude 4094;
BA_ "GenSigSwitchedByIgnition" SG_ 1157 NP_Altitude 0;
BA_ "Fehlerwert" SG_ 1157 NP_Altitude 4095;
BA_ "GenSigSendType" SG_ 1157 POS_Guete_horizontal 0;
BA_ "GenSigStartValue" SG_ 1157 POS_Guete_horizontal 126;
BA_ "GenSigSwitchedByIgnition" SG_ 1157 POS_Guete_horizontal 0;
BA_ "Fehlerwert" SG_ 1157 POS_Guete_horizontal 127;
BA_ "GenSigSendType" SG_ 1157 POS_Guete_horizontal_verfuegbar 0;
BA_ "GenSigSwitchedByIgnition" SG_ 1157 POS_Guete_horizontal_verfuegbar 0;
BA_ "GenSigSendType" SG_ 1158 NP_Fix 0;
BA_ "GenSigSwitchedByIgnition" SG_ 1158 NP_Fix 0;
BA_ "GenSigSendType" SG_ 1158 NP_LatDegree 0;
BA_ "GenSigStartValue" SG_ 1158 NP_LatDegree 134217726;
BA_ "GenSigSwitchedByIgnition" SG_ 1158 NP_LatDegree 0;
BA_ "Fehlerwert" SG_ 1158 NP_LatDegree 134217727;
BA_ "GenSigSendType" SG_ 1158 NP_LatDirection 0;
BA_ "GenSigStartValue" SG_ 1158 NP_LatDirection 1;
BA_ "GenSigSwitchedByIgnition" SG_ 1158 NP_LatDirection 0;
BA_ "GenSigSendType" SG_ 1158 NP_LongDegree 0;
BA_ "GenSigStartValue" SG_ 1158 NP_LongDegree 268435454;
BA_ "GenSigSwitchedByIgnition" SG_ 1158 NP_LongDegree 0;
BA_ "Fehlerwert" SG_ 1158 NP_LongDegree 268435455;
BA_ "GenSigSendType" SG_ 1158 NP_LongDirection 0;
BA_ "GenSigStartValue" SG_ 1158 NP_LongDirection 1;
BA_ "GenSigSwitchedByIgnition" SG_ 1158 NP_LongDirection 0;
BA_ "GenSigSendType" SG_ 1158 NP_Sat 0;
BA_ "GenSigStartValue" SG_ 1158 NP_Sat 30;
BA_ "GenSigSwitchedByIgnition" SG_ 1158 NP_Sat 0;
BA_ "Fehlerwert" SG_ 1158 NP_Sat 31;
BA_ "GenSigFuncType" SG_ 2600468529 NM_ELV_CAB_V14 16;
BA_ "GenSigSwitchedByIgnition" SG_ 2600468529 NM_ELV_CAB_V14 0;
BA_ "GenSigSwitchedByIgnition" SG_ 2600468529 NM_ELV_Car_Wakeup 0;
BA_ "GenSigSwitchedByIgnition" SG_ 2600468529 NM_ELV_CBV_AWB 0;
BA_ "GenSigSwitchedByIgnition" SG_ 2600468529 NM_ELV_CBV_CRI 0;
BA_ "GenSigSwitchedByIgnition" SG_ 2600468529 NM_ELV_NM_aktiv_Diagnose 0;
BA_ "GenSigSwitchedByIgnition" SG_ 2600468529 NM_ELV_NM_aktiv_KL15 0;
BA_ "GenSigSwitchedByIgnition" SG_ 2600468529 NM_ELV_NM_aktiv_Meldung 0;
BA_ "GenSigSwitchedByIgnition" SG_ 2600468529 NM_ELV_NM_aktiv_Tmin 0;
BA_ "GenSigSwitchedByIgnition" SG_ 2600468529 NM_ELV_NM_aktiv_Verfahrtrigger 0;
BA_ "GenSigSwitchedByIgnition" SG_ 2600468529 NM_ELV_NM_aktiv_WFS 0;
BA_ "GenSigSwitchedByIgnition" SG_ 2600468529 NM_ELV_NM_State 0;
BA_ "GenSigSwitchedByIgnition" SG_ 2600468529 NM_ELV_UDS_CC 0;
BA_ "GenSigFuncType" SG_ 2600468496 NM_Gateway_CAB_V14 16;
BA_ "GenSigSwitchedByIgnition" SG_ 2600468496 NM_Gateway_CAB_V14 0;
BA_ "GenSigSwitchedByIgnition" SG_ 2600468496 NM_Gateway_Car_Wakeup 0;
BA_ "GenSigSwitchedByIgnition" SG_ 2600468496 NM_Gateway_CBV_AWB 0;
BA_ "GenSigSwitchedByIgnition" SG_ 2600468496 NM_Gateway_CBV_CRI 0;
BA_ "GenSigSwitchedByIgnition" SG_ 2600468496 NM_Gateway_NM_aktiv_Buskopplung 0;
BA_ "GenSigSwitchedByIgnition" SG_ 2600468496 NM_Gateway_NM_aktiv_CWU 0;
BA_ "GenSigSwitchedByIgnition" SG_ 2600468496 NM_Gateway_NM_aktiv_Diagnose 0;
BA_ "GenSigSwitchedByIgnition" SG_ 2600468496 NM_Gateway_NM_aktiv_EM 0;
BA_ "GenSigSwitchedByIgnition" SG_ 2600468496 NM_Gateway_NM_aktiv_FC 0;
BA_ "GenSigSwitchedByIgnition" SG_ 2600468496 NM_Gateway_NM_aktiv_KL15 0;
BA_ "GenSigSwitchedByIgnition" SG_ 2600468496 NM_Gateway_NM_aktiv_Tmin 0;
BA_ "GenSigSwitchedByIgnition" SG_ 2600468496 NM_Gateway_NM_State 0;
BA_ "GenSigSwitchedByIgnition" SG_ 2600468496 NM_Gateway_UDS_CC 0;
BA_ "GenSigFuncType" SG_ 2600468507 NM_HUD_CAB_V14 16;
BA_ "GenSigSwitchedByIgnition" SG_ 2600468507 NM_HUD_CAB_V14 0;
BA_ "GenSigSwitchedByIgnition" SG_ 2600468507 NM_HUD_Car_WakeUp 0;
BA_ "GenSigSwitchedByIgnition" SG_ 2600468507 NM_HUD_CBV_AWB 0;
BA_ "GenSigStartValue" SG_ 2600468507 NM_HUD_CBV_CRI 1;
BA_ "GenSigSwitchedByIgnition" SG_ 2600468507 NM_HUD_CBV_CRI 0;
BA_ "GenSigSwitchedByIgnition" SG_ 2600468507 NM_HUD_NM_aktiv_Diagnose 0;
BA_ "GenSigSwitchedByIgnition" SG_ 2600468507 NM_HUD_NM_aktiv_KL15 0;
BA_ "GenSigSwitchedByIgnition" SG_ 2600468507 NM_HUD_NM_aktiv_Tmin 0;
BA_ "GenSigSwitchedByIgnition" SG_ 2600468507 NM_HUD_NM_State 0;
BA_ "GenSigSwitchedByIgnition" SG_ 2600468507 NM_HUD_UDS_CC 0;
BA_ "GenSigFuncType" SG_ 2600468500 NM_Kombi_CAB_V14 16;
BA_ "GenSigSwitchedByIgnition" SG_ 2600468500 NM_Kombi_CAB_V14 0;
BA_ "GenSigSwitchedByIgnition" SG_ 2600468500 NM_Kombi_Car_Wakeup 0;
BA_ "GenSigSwitchedByIgnition" SG_ 2600468500 NM_Kombi_CBV_AWB 0;
BA_ "GenSigFuncType" SG_ 2600468500 NM_Kombi_CBV_CRI 8;
BA_ "GenSigSwitchedByIgnition" SG_ 2600468500 NM_Kombi_CBV_CRI 0;
BA_ "GenSigSwitchedByIgnition" SG_ 2600468500 NM_Kombi_NM_aktiv_Buzzer 0;
BA_ "GenSigSwitchedByIgnition" SG_ 2600468500 NM_Kombi_NM_aktiv_Diagnose 0;
BA_ "GenSigSwitchedByIgnition" SG_ 2600468500 NM_Kombi_NM_aktiv_KL15 0;
BA_ "GenSigSwitchedByIgnition" SG_ 2600468500 NM_Kombi_NM_aktiv_Schluesselkomm 0;
BA_ "GenSigSwitchedByIgnition" SG_ 2600468500 NM_Kombi_NM_aktiv_Tmin 0;
BA_ "GenSigSwitchedByIgnition" SG_ 2600468500 NM_Kombi_NM_aktiv_VLW 0;
BA_ "GenSigSwitchedByIgnition" SG_ 2600468500 NM_Kombi_NM_State 0;
BA_ "GenSigSwitchedByIgnition" SG_ 2600468500 NM_Kombi_UDS_CC 0;
BA_ "GenSigSendType" SG_ 527 NVEM_10_BZ 0;
BA_ "GenSigFuncType" SG_ 527 NVEM_10_BZ 1;
BA_ "GenSigSwitchedByIgnition" SG_ 527 NVEM_10_BZ 0;
BA_ "GenSigSendType" SG_ 527 NVEM_10_CRC 0;
BA_ "GenSigFuncType" SG_ 527 NVEM_10_CRC 2;
BA_ "GenSigSwitchedByIgnition" SG_ 527 NVEM_10_CRC 0;
BA_ "GenSigSendType" SG_ 527 NVEM_DC_iSoll_NV 0;
BA_ "GenSigStartValue" SG_ 527 NVEM_DC_iSoll_NV 254;
BA_ "GenSigSwitchedByIgnition" SG_ 527 NVEM_DC_iSoll_NV 0;
BA_ "Fehlerwert" SG_ 527 NVEM_DC_iSoll_NV 255;
BA_ "GenSigSendType" SG_ 527 NVEM_DC_uSoll_NV 0;
BA_ "GenSigStartValue" SG_ 527 NVEM_DC_uSoll_NV 116;
BA_ "GenSigSwitchedByIgnition" SG_ 527 NVEM_DC_uSoll_NV 0;
BA_ "Fehlerwert" SG_ 527 NVEM_DC_uSoll_NV 255;
BA_ "GenSigSendType" SG_ 527 NVEM_IBatt 0;
BA_ "GenSigStartValue" SG_ 527 NVEM_IBatt 127;
BA_ "GenSigSwitchedByIgnition" SG_ 527 NVEM_IBatt 0;
BA_ "Fehlerwert" SG_ 527 NVEM_IBatt 255;
BA_ "GenSigSendType" SG_ 527 NVEM_MOD_Budget 0;
BA_ "GenSigStartValue" SG_ 527 NVEM_MOD_Budget 15;
BA_ "GenSigSwitchedByIgnition" SG_ 527 NVEM_MOD_Budget 0;
BA_ "GenSigSendType" SG_ 527 NVEM_MOD_Freigabe 0;
BA_ "GenSigStartValue" SG_ 527 NVEM_MOD_Freigabe 3;
BA_ "GenSigSwitchedByIgnition" SG_ 527 NVEM_MOD_Freigabe 0;
BA_ "GenSigSendType" SG_ 527 NVEM_MV_DC_iSoll_NV 0;
BA_ "GenSigStartValue" SG_ 527 NVEM_MV_DC_iSoll_NV 254;
BA_ "GenSigSwitchedByIgnition" SG_ 527 NVEM_MV_DC_iSoll_NV 0;
BA_ "Fehlerwert" SG_ 527 NVEM_MV_DC_iSoll_NV 255;
BA_ "GenSigSendType" SG_ 1630 OBD_TG_F_Status_1 0;
BA_ "GenSigSwitchedByIgnition" SG_ 1630 OBD_TG_F_Status_1 0;
BA_ "GenSigSendType" SG_ 1630 OBD_TG_F_Status_2 0;
BA_ "GenSigSwitchedByIgnition" SG_ 1630 OBD_TG_F_Status_2 0;
BA_ "GenSigSendType" SG_ 1630 OBD_TG_F_Status_3 0;
BA_ "GenSigSwitchedByIgnition" SG_ 1630 OBD_TG_F_Status_3 0;
BA_ "GenSigSendType" SG_ 1630 OBD_TG_F_Status_4 0;
BA_ "GenSigSwitchedByIgnition" SG_ 1630 OBD_TG_F_Status_4 0;
BA_ "GenSigSendType" SG_ 1630 OBD_TG_Sens_Rohwert_1 0;
BA_ "GenSigSwitchedByIgnition" SG_ 1630 OBD_TG_Sens_Rohwert_1 0;
BA_ "GenSigSendType" SG_ 1630 OBD_TG_Sens_Rohwert_2 0;
BA_ "GenSigSwitchedByIgnition" SG_ 1630 OBD_TG_Sens_Rohwert_2 0;
BA_ "GenSigSendType" SG_ 1630 OBD_TG_Sens_Rohwert_3 0;
BA_ "GenSigSwitchedByIgnition" SG_ 1630 OBD_TG_Sens_Rohwert_3 0;
BA_ "GenSigSendType" SG_ 1630 OBD_TG_Sens_Rohwert_4 0;
BA_ "GenSigSwitchedByIgnition" SG_ 1630 OBD_TG_Sens_Rohwert_4 0;
BA_ "GenSigSendType" SG_ 2621440561 OBDC_ELV_Req_FD_Data 3;
BA_ "GenSigFuncType" SG_ 2621440561 OBDC_ELV_Req_FD_Data 9;
BA_ "GenSigSwitchedByIgnition" SG_ 2621440561 OBDC_ELV_Req_FD_Data 0;
BA_ "GenSigSendType" SG_ 2621571633 OBDC_ELV_Resp_FD_Data 3;
BA_ "GenSigFuncType" SG_ 2621571633 OBDC_ELV_Resp_FD_Data 9;
BA_ "GenSigSwitchedByIgnition" SG_ 2621571633 OBDC_ELV_Resp_FD_Data 0;
BA_ "GenSigSendType" SG_ 2549940736 OBDC_Funktionaler_Req_All_Data 3;
BA_ "GenSigFuncType" SG_ 2549940736 OBDC_Funktionaler_Req_All_Data 9;
BA_ "GenSigSwitchedByIgnition" SG_ 2549940736 OBDC_Funktionaler_Req_All_Data 0;
BA_ "GenSigSendType" SG_ 2621506048 OBDC_Funktion_Req_All_FD_Data 3;
BA_ "GenSigFuncType" SG_ 2621506048 OBDC_Funktion_Req_All_FD_Data 9;
BA_ "GenSigSwitchedByIgnition" SG_ 2621506048 OBDC_Funktion_Req_All_FD_Data 0;
BA_ "GenSigSendType" SG_ 2621440539 OBDC_HUD_Req_FD_Data 3;
BA_ "GenSigFuncType" SG_ 2621440539 OBDC_HUD_Req_FD_Data 9;
BA_ "GenSigSwitchedByIgnition" SG_ 2621440539 OBDC_HUD_Req_FD_Data 0;
BA_ "GenSigSendType" SG_ 2621571611 OBDC_HUD_Resp_FD_Data 3;
BA_ "GenSigFuncType" SG_ 2621571611 OBDC_HUD_Resp_FD_Data 9;
BA_ "GenSigSwitchedByIgnition" SG_ 2621571611 OBDC_HUD_Resp_FD_Data 0;
BA_ "GenSigSendType" SG_ 2621440532 OBDC_Kombi_Req_FD_Data 3;
BA_ "GenSigFuncType" SG_ 2621440532 OBDC_Kombi_Req_FD_Data 9;
BA_ "GenSigSwitchedByIgnition" SG_ 2621440532 OBDC_Kombi_Req_FD_Data 0;
BA_ "GenSigSendType" SG_ 2621571604 OBDC_Kombi_Resp_FD_Data 3;
BA_ "GenSigFuncType" SG_ 2621571604 OBDC_Kombi_Resp_FD_Data 9;
BA_ "GenSigSwitchedByIgnition" SG_ 2621571604 OBDC_Kombi_Resp_FD_Data 0;
BA_ "GenSigSendType" SG_ 2549875364 OBDC_LSH_Req_Data 3;
BA_ "GenSigFuncType" SG_ 2549875364 OBDC_LSH_Req_Data 9;
BA_ "GenSigSwitchedByIgnition" SG_ 2549875364 OBDC_LSH_Req_Data 0;
BA_ "GenSigSendType" SG_ 2550006436 OBDC_LSH_Resp_Data 3;
BA_ "GenSigFuncType" SG_ 2550006436 OBDC_LSH_Resp_Data 9;
BA_ "GenSigSwitchedByIgnition" SG_ 2550006436 OBDC_LSH_Resp_Data 0;
BA_ "GenSigSendType" SG_ 2621440556 OBDC_MFG_Req_FD_Data 3;
BA_ "GenSigFuncType" SG_ 2621440556 OBDC_MFG_Req_FD_Data 9;
BA_ "GenSigSwitchedByIgnition" SG_ 2621440556 OBDC_MFG_Req_FD_Data 0;
BA_ "GenSigSendType" SG_ 2621571628 OBDC_MFG_Resp_FD_Data 3;
BA_ "GenSigFuncType" SG_ 2621571628 OBDC_MFG_Resp_FD_Data 9;
BA_ "GenSigSwitchedByIgnition" SG_ 2621571628 OBDC_MFG_Resp_FD_Data 0;
BA_ "GenSigSendType" SG_ 2549903375 OBDC_SSN_ABT_2_Req_Data 3;
BA_ "GenSigFuncType" SG_ 2549903375 OBDC_SSN_ABT_2_Req_Data 9;
BA_ "GenSigSwitchedByIgnition" SG_ 2549903375 OBDC_SSN_ABT_2_Req_Data 0;
BA_ "GenSigSendType" SG_ 2550034447 OBDC_SSN_ABT_2_Resp_Data 3;
BA_ "GenSigFuncType" SG_ 2550034447 OBDC_SSN_ABT_2_Resp_Data 9;
BA_ "GenSigSwitchedByIgnition" SG_ 2550034447 OBDC_SSN_ABT_2_Resp_Data 0;
BA_ "GenSigSendType" SG_ 2621440625 OBDC_TCO_Req_FD_Data 3;
BA_ "GenSigFuncType" SG_ 2621440625 OBDC_TCO_Req_FD_Data 9;
BA_ "GenSigSwitchedByIgnition" SG_ 2621440625 OBDC_TCO_Req_FD_Data 0;
BA_ "GenSigSendType" SG_ 2621571697 OBDC_TCO_Resp_FD_Data 3;
BA_ "GenSigFuncType" SG_ 2621571697 OBDC_TCO_Resp_FD_Data 9;
BA_ "GenSigSwitchedByIgnition" SG_ 2621571697 OBDC_TCO_Resp_FD_Data 0;
BA_ "GenSigSendType" SG_ 2550399502 OBDC_TRE_2_Req_Data 3;
BA_ "GenSigFuncType" SG_ 2550399502 OBDC_TRE_2_Req_Data 9;
BA_ "GenSigSwitchedByIgnition" SG_ 2550399502 OBDC_TRE_2_Req_Data 0;
BA_ "GenSigSendType" SG_ 2550530574 OBDC_TRE_2_Resp_Data 3;
BA_ "GenSigFuncType" SG_ 2550530574 OBDC_TRE_2_Resp_Data 9;
BA_ "GenSigSwitchedByIgnition" SG_ 2550530574 OBDC_TRE_2_Resp_Data 0;
BA_ "GenSigSendType" SG_ 2589284143 OBMI_DDrvRngRem 0;
BA_ "GenSigStartValue" SG_ 2589284143 OBMI_DDrvRngRem 8190;
BA_ "GenSigSwitchedByIgnition" SG_ 2589284143 OBMI_DDrvRngRem 0;
BA_ "GenSigSendType" SG_ 2589284143 OBMI_FlgTrig 0;
BA_ "GenSigSwitchedByIgnition" SG_ 2589284143 OBMI_FlgTrig 0;
BA_ "GenSigSendType" SG_ 2589284143 OBMI_StAct 0;
BA_ "GenSigSwitchedByIgnition" SG_ 2589284143 OBMI_StAct 0;
BA_ "GenSigSendType" SG_ 2589284143 OBMI_StDrvRngUnit 0;
BA_ "GenSigSwitchedByIgnition" SG_ 2589284143 OBMI_StDrvRngUnit 0;
BA_ "GenSigSendType" SG_ 2589283656 ORU_Status 3;
BA_ "GenSigSwitchedByIgnition" SG_ 2589283656 ORU_Status 0;
BA_ "GenSigSendType" SG_ 2589283656 ORU_Warnung 3;
BA_ "GenSigSwitchedByIgnition" SG_ 2589283656 ORU_Warnung 0;
BA_ "GenSigSendType" SG_ 1175 PDC_Tonausgabe_Front 3;
BA_ "GenSigSendType" SG_ 1175 PDC_Tonausgabe_Heck 3;
BA_ "GenSigSendType" SG_ 1175 PH_Abschaltursache 3;
BA_ "GenSigSendType" SG_ 1175 PH_Anf_Audioabsenkung 3;
BA_ "GenSigSendType" SG_ 1175 PH_Anf_Verdeck 3;
BA_ "GenSigSendType" SG_ 1175 PH_defekt 3;
BA_ "GenSigSendType" SG_ 1175 PH_Display_Kundenwunsch 3;
BA_ "GenSigSendType" SG_ 1175 PH_Frequenz_hinten 3;
BA_ "GenSigSendType" SG_ 1175 PH_Frequenz_vorn 3;
BA_ "GenSigSendType" SG_ 1175 PH_gestoert 3;
BA_ "GenSigSendType" SG_ 1175 PH_Lautstaerke_hinten 3;
BA_ "GenSigSendType" SG_ 1175 PH_Lautstaerke_vorn 3;
BA_ "GenSigSendType" SG_ 1175 PH_nachtr_Stopp_Anf 3;
BA_ "GenSigSendType" SG_ 1175 PH_Opt_Anz_H_Hindernis 3;
BA_ "GenSigSendType" SG_ 1175 PH_Opt_Anz_V_Hindernis 3;
BA_ "GenSigSendType" SG_ 1175 PH_Opt_Anzeige_H_ein 3;
BA_ "GenSigSendType" SG_ 1175 PH_Opt_Anzeige_V_ein 3;
BA_ "GenSigSendType" SG_ 1175 PH_StartStopp_Info 3;
BA_ "GenSigSendType" SG_ 1175 PH_Stoermeldung 3;
BA_ "GenSigSendType" SG_ 1175 PH_Systemzustand 3;
BA_ "GenSigSendType" SG_ 1175 PH_Taster 3;
BA_ "Fehlerwert" SG_ 1175 PH_Taster 3;
BA_ "GenSigSendType" SG_ 1175 PH_Tongeber_H_aktiv 3;
BA_ "GenSigSendType" SG_ 1175 PH_Tongeber_H_verfuegbar 3;
BA_ "GenSigSendType" SG_ 1175 PH_Tongeber_mute 3;
BA_ "GenSigSendType" SG_ 1175 PH_Tongeber_V_aktiv 3;
BA_ "GenSigSendType" SG_ 1175 PH_Visualisierung 3;
BA_ "GenSigStartValue" SG_ 1175 PH_Visualisierung 6;
BA_ "Fehlerwert" SG_ 1175 PH_Visualisierung 7;
BA_ "GenSigSendType" SG_ 1175 PLA_Anf_Aufschaltung_RVC 3;
BA_ "GenSigSendType" SG_ 1355 APS_PaCo_WarningTones 3;
BA_ "GenSigSwitchedByIgnition" SG_ 1355 APS_PaCo_WarningTones 0;
BA_ "GenSigSendType" SG_ 1355 APSOPS_PaCo_ApproachingFront 3;
BA_ "GenSigSwitchedByIgnition" SG_ 1355 APSOPS_PaCo_ApproachingFront 0;
BA_ "GenSigSendType" SG_ 1355 APSOPS_PaCo_ApproachingRear 3;
BA_ "GenSigSwitchedByIgnition" SG_ 1355 APSOPS_PaCo_ApproachingRear 0;
BA_ "GenSigSendType" SG_ 1355 APSOPS_PaCo_Button 3;
BA_ "GenSigSwitchedByIgnition" SG_ 1355 APSOPS_PaCo_Button 0;
BA_ "GenSigSendType" SG_ 1355 APSOPS_PaCo_FunctionState 3;
BA_ "GenSigSwitchedByIgnition" SG_ 1355 APSOPS_PaCo_FunctionState 0;
BA_ "GenSigSendType" SG_ 1355 APSOPS_PaCo_MainState 3;
BA_ "GenSigSwitchedByIgnition" SG_ 1355 APSOPS_PaCo_MainState 0;
BA_ "Fehlerwert" SG_ 1355 APSOPS_PaCo_MainState 7;
BA_ "GenSigSendType" SG_ 1355 APSOPS_PaCo_ObstacleDetectFront 3;
BA_ "GenSigSwitchedByIgnition" SG_ 1355 APSOPS_PaCo_ObstacleDetectFront 0;
BA_ "GenSigSendType" SG_ 1355 APSOPS_PaCo_ObstacleDetectRear 3;
BA_ "GenSigSwitchedByIgnition" SG_ 1355 APSOPS_PaCo_ObstacleDetectRear 0;
BA_ "GenSigSendType" SG_ 1355 PH_Aufschaltursache 3;
BA_ "GenSigSendType" SG_ 1355 PH_Ton_Ausgabe 3;
BA_ "Fehlerwert" SG_ 1355 PH_Ton_Ausgabe 7;
BA_ "GenSigSendType" SG_ 1355 PH_Ton_Lautstaerke 3;
BA_ "GenSigSendType" SG_ 1355 PH_Ton_Pausenlaenge 3;
BA_ "Fehlerwert" SG_ 1355 PH_Ton_Pausenlaenge 127;
BA_ "GenSigSendType" SG_ 1355 PH_Ton_Richtung 3;
BA_ "GenSigSendType" SG_ 1355 PH_Verschmutzungsmeldung 3;
BA_ "GenSigSendType" SG_ 1355 PH_WAH_Meldung 3;
BA_ "GenSigSendType" SG_ 1355 RAB_PaCo_FunctionState 3;
BA_ "GenSigSwitchedByIgnition" SG_ 1355 RAB_PaCo_FunctionState 0;
BA_ "GenSigSendType" SG_ 1355 RBF_Anf_Meldungen 3;
BA_ "GenSigSendType" SG_ 1355 RBF_PaCo_Anf_Meldungen 3;
BA_ "GenSigSendType" SG_ 1355 RBF_PMO_Bereich_erkannt 3;
BA_ "GenSigSendType" SG_ 1355 RBFMA_PaCo_BrakeIntervention 3;
BA_ "GenSigSwitchedByIgnition" SG_ 1355 RBFMA_PaCo_BrakeIntervention 0;
BA_ "GenSigSendType" SG_ 1355 RBFMA_PaCo_MainState 3;
BA_ "GenSigSwitchedByIgnition" SG_ 1355 RBFMA_PaCo_MainState 0;
BA_ "Fehlerwert" SG_ 1355 RBFMA_PaCo_MainState 7;
BA_ "GenSigSendType" SG_ 2527679498 IAA_Active_User_ID 4;
BA_ "GenSigSwitchedByIgnition" SG_ 2527679498 IAA_Active_User_ID 0;
BA_ "GenSigSendType" SG_ 2527679498 IAA_Identified_User_ID 4;
BA_ "GenSigSwitchedByIgnition" SG_ 2527679498 IAA_Identified_User_ID 0;
BA_ "GenSigSendType" SG_ 2527679498 IAA_PSO_wake_up 4;
BA_ "GenSigSwitchedByIgnition" SG_ 2527679498 IAA_PSO_wake_up 0;
BA_ "GenSigSendType" SG_ 2527679498 Perso_Aktiv 4;
BA_ "GenSigSwitchedByIgnition" SG_ 2527679498 Perso_Aktiv 0;
BA_ "GenSigSendType" SG_ 2527679498 Perso_Bedienstelle 4;
BA_ "GenSigSwitchedByIgnition" SG_ 2527679498 Perso_Bedienstelle 0;
BA_ "GenSigSendType" SG_ 2527679498 Perso_Fahrernummer 4;
BA_ "GenSigSwitchedByIgnition" SG_ 2527679498 Perso_Fahrernummer 0;
BA_ "GenSigSendType" SG_ 2527679498 Perso_Freigabe_Verstellung 4;
BA_ "GenSigSwitchedByIgnition" SG_ 2527679498 Perso_Freigabe_Verstellung 0;
BA_ "GenSigSendType" SG_ 2527679498 Perso_Kontonummer 4;
BA_ "GenSigSwitchedByIgnition" SG_ 2527679498 Perso_Kontonummer 0;
BA_ "GenSigSendType" SG_ 2527679498 Perso_Schreibschutz 4;
BA_ "GenSigSwitchedByIgnition" SG_ 2527679498 Perso_Schreibschutz 0;
BA_ "GenSigSendType" SG_ 2527679498 Perso_Status 1;
BA_ "GenSigSwitchedByIgnition" SG_ 2527679498 Perso_Status 0;
BA_ "GenSigSendType" SG_ 2527679498 Perso_Steuerung 4;
BA_ "GenSigSwitchedByIgnition" SG_ 2527679498 Perso_Steuerung 0;
BA_ "GenSigSendType" SG_ 2527679498 Perso_Steuerungsparameter 4;
BA_ "GenSigSwitchedByIgnition" SG_ 2527679498 Perso_Steuerungsparameter 0;
BA_ "GenSigSendType" SG_ 1166 PLA_Anf_Akustik 0;
BA_ "GenSigSendType" SG_ 1166 PLA_Anf_Anzeige_Bremsfuss 0;
BA_ "GenSigSendType" SG_ 1166 PLA_Anf_Anzeige_Mini 0;
BA_ "GenSigSendType" SG_ 1166 PLA_Anf_Anzeige_Schwellpfeil 0;
BA_ "GenSigSendType" SG_ 1166 PLA_Anf_Anzeigemodus 0;
BA_ "GenSigSendType" SG_ 1166 PLA_Anf_Meldungen 0;
BA_ "GenSigSwitchedByIgnition" SG_ 1166 PLA_Anf_Meldungen 0;
BA_ "GenSigSendType" SG_ 1166 PLA_Anforderung_HMS 0;
BA_ "GenSigSendType" SG_ 1166 PLA_Anzahl_Segmente_Schwellpfeil 0;
BA_ "GenSigSendType" SG_ 1166 PLA_Mini_Modus 0;
BA_ "GenSigSendType" SG_ 1166 PLA_Status_Aktive_Seite 0;
BA_ "GenSigSendType" SG_ 1166 PLA_Status_beenden_Mini 0;
BA_ "GenSigSendType" SG_ 1166 PLA_Status_Funktion 0;
BA_ "GenSigSendType" SG_ 1166 PLA_Status_Laengsparken_Mini 0;
BA_ "GenSigSendType" SG_ 1166 PLA_Status_QP_Rueckw_Mini 0;
BA_ "GenSigSendType" SG_ 1166 PLA_Status_QP_Vorw_Mini 0;
BA_ "GenSigSendType" SG_ 319 PreCrash_Anforderung_AFR 3;
BA_ "GenSigStartValue" SG_ 319 PreCrash_Anforderung_AFR 7;
BA_ "GenSigSwitchedByIgnition" SG_ 319 PreCrash_Anforderung_AFR 0;
BA_ "GenSigSendType" SG_ 319 PreCrash_BFS_KSV_verfahren 3;
BA_ "GenSigSwitchedByIgnition" SG_ 319 PreCrash_BFS_KSV_verfahren 0;
BA_ "GenSigSendType" SG_ 319 PreCrash_BFS_Laengsverstellung 3;
BA_ "GenSigSwitchedByIgnition" SG_ 319 PreCrash_BFS_Laengsverstellung 0;
BA_ "GenSigSendType" SG_ 319 PreCrash_BFS_Pneumatik_ansteuern 3;
BA_ "GenSigSwitchedByIgnition" SG_ 319 PreCrash_BFS_Pneumatik_ansteuern 0;
BA_ "GenSigSendType" SG_ 319 PreCrash_BFS_Sitzlehne_verfahren 3;
BA_ "GenSigSwitchedByIgnition" SG_ 319 PreCrash_BFS_Sitzlehne_verfahren 0;
BA_ "GenSigSendType" SG_ 319 PreCrash_Blinken 3;
BA_ "GenSigSendType" SG_ 319 PreCrash_Charisma_FahrPr 0;
BA_ "GenSigSendType" SG_ 319 PreCrash_Charisma_Status 0;
BA_ "GenSigSendType" SG_ 319 PreCrash_Fenster_schliessen 3;
BA_ "GenSigSendType" SG_ 319 PreCrash_Fo_KSV_verfahren 3;
BA_ "GenSigSendType" SG_ 319 PreCrash_Fo_Pneumatik_ansteuern 3;
BA_ "GenSigSendType" SG_ 319 PreCrash_Fo_Sitzlehne_verfahren 3;
BA_ "GenSigSwitchedByIgnition" SG_ 319 PreCrash_Fo_Sitzlehne_verfahren 0;
BA_ "GenSigSendType" SG_ 319 PreCrash_FS_KSV_verfahren 3;
BA_ "GenSigSwitchedByIgnition" SG_ 319 PreCrash_FS_KSV_verfahren 0;
BA_ "GenSigSendType" SG_ 319 PreCrash_FS_Laengsverstellung 3;
BA_ "GenSigSwitchedByIgnition" SG_ 319 PreCrash_FS_Laengsverstellung 0;
BA_ "GenSigSendType" SG_ 319 PreCrash_FS_Pneumatik_ansteuern 3;
BA_ "GenSigSwitchedByIgnition" SG_ 319 PreCrash_FS_Pneumatik_ansteuern 0;
BA_ "GenSigSendType" SG_ 319 PreCrash_FS_Sitzlehne_verfahren 3;
BA_ "GenSigSwitchedByIgnition" SG_ 319 PreCrash_FS_Sitzlehne_verfahren 0;
BA_ "GenSigSendType" SG_ 319 PreCrash_Schiebedach_schliessen 3;
BA_ "GenSigSendType" SG_ 319 PreCrash_Tueren_Verriegeln 3;
BA_ "GenSigSwitchedByIgnition" SG_ 319 PreCrash_Tueren_Verriegeln 0;
BA_ "GenSigSendType" SG_ 319 SC_PreCrash_LED 3;
BA_ "GenSigSwitchedByIgnition" SG_ 319 SC_PreCrash_LED 0;
BA_ "GenSigSendType" SG_ 319 SC_PreCrash_Texte 3;
BA_ "GenSigSwitchedByIgnition" SG_ 319 SC_PreCrash_Texte 0;
BA_ "GenSigSendType" SG_ 319 SC_PreCrash_Warnung 3;
BA_ "GenSigSwitchedByIgnition" SG_ 319 SC_PreCrash_Warnung 0;
BA_ "GenSigSendType" SG_ 319 SC_PreSense_FCWP 3;
BA_ "GenSigSwitchedByIgnition" SG_ 319 SC_PreSense_FCWP 0;
BA_ "GenSigSendType" SG_ 1122 PSD_Abzweigerichtung 0;
BA_ "GenSigSwitchedByIgnition" SG_ 1122 PSD_Abzweigerichtung 0;
BA_ "GenSigSendType" SG_ 1122 PSD_Abzweigewinkel 0;
BA_ "GenSigSwitchedByIgnition" SG_ 1122 PSD_Abzweigewinkel 0;
BA_ "GenSigSendType" SG_ 1122 PSD_ADAS_Qualitaet 0;
BA_ "GenSigSendType" SG_ 1122 PSD_Anfangskruemmung 0;
BA_ "GenSigSwitchedByIgnition" SG_ 1122 PSD_Anfangskruemmung 0;
BA_ "GenSigSendType" SG_ 1122 PSD_Anfangskruemmung_Vorz 0;
BA_ "GenSigSwitchedByIgnition" SG_ 1122 PSD_Anfangskruemmung_Vorz 0;
BA_ "GenSigSendType" SG_ 1122 PSD_Bebauung 0;
BA_ "GenSigSendType" SG_ 1122 PSD_Endkruemmung 0;
BA_ "GenSigSendType" SG_ 1122 PSD_Endkruemmung_Vorz 0;
BA_ "GenSigSendType" SG_ 1122 PSD_Fahrspuren_Anzahl 0;
BA_ "GenSigStartValue" SG_ 1122 PSD_Fahrspuren_Anzahl 1;
BA_ "GenSigSwitchedByIgnition" SG_ 1122 PSD_Fahrspuren_Anzahl 0;
BA_ "GenSigSendType" SG_ 1122 PSD_Geradester_Pfad 0;
BA_ "GenSigSendType" SG_ 1122 PSD_Idenditaets_ID 0;
BA_ "Fehlerwert" SG_ 1122 PSD_Idenditaets_ID 1;
BA_ "GenSigSendType" SG_ 1122 PSD_Rampe 0;
BA_ "GenSigSendType" SG_ 1122 PSD_Segment_ID 0;
BA_ "GenSigSendType" SG_ 1122 PSD_Segment_Komplett 0;
BA_ "GenSigSwitchedByIgnition" SG_ 1122 PSD_Segment_Komplett 0;
BA_ "GenSigSendType" SG_ 1122 PSD_Segmentlaenge 0;
BA_ "GenSigSendType" SG_ 1122 PSD_Strassenkategorie 0;
BA_ "GenSigStartValue" SG_ 1122 PSD_Strassenkategorie 7;
BA_ "GenSigSwitchedByIgnition" SG_ 1122 PSD_Strassenkategorie 0;
BA_ "GenSigSendType" SG_ 1122 PSD_Vorgaenger_Segment_ID 0;
BA_ "GenSigSendType" SG_ 1122 PSD_wahrscheinlichster_Pfad 0;
BA_ "GenSigSendType" SG_ 1123 PSD_Attribut_1_ID 0;
BA_ "GenSigSendType" SG_ 1123 PSD_Attribut_1_Offset 0;
BA_ "GenSigSendType" SG_ 1123 PSD_Attribut_1_Wert 0;
BA_ "GenSigSendType" SG_ 1123 PSD_Attribut_2_ID 0;
BA_ "GenSigSendType" SG_ 1123 PSD_Attribut_2_Offset 0;
BA_ "GenSigSendType" SG_ 1123 PSD_Attribut_2_Wert 0;
BA_ "GenSigSendType" SG_ 1123 PSD_Attribut_Segment_ID_05 0;
BA_ "Fehlerwert" SG_ 1123 PSD_Attribut_Segment_ID_05 1;
BA_ "GenSigSendType" SG_ 1123 PSD_Attribute_Komplett_05 0;
BA_ "GenSigSendType" SG_ 1123 PSD_Pos_Fahrspur 0;
BA_ "GenSigSendType" SG_ 1123 PSD_Pos_Fehler_Laengsrichtung 0;
BA_ "GenSigSendType" SG_ 1123 PSD_Pos_Inhibitzeit 0;
BA_ "GenSigSendType" SG_ 1123 PSD_Pos_Segment_ID 0;
BA_ "GenSigSendType" SG_ 1123 PSD_Pos_Segmentlaenge 0;
BA_ "GenSigSendType" SG_ 1123 PSD_Pos_Standort_Eindeutig 0;
BA_ "GenSigSwitchedByIgnition" SG_ 1123 PSD_Pos_Standort_Eindeutig 0;
BA_ "GenSigSendType" SG_ 1124 PSD_06_Mux 0;
BA_ "NWM-WakeupAllowed" SG_ 1124 PSD_06_Mux 1;
BA_ "GenSigSwitchedByIgnition" SG_ 1124 PSD_06_Mux 0;
BA_ "Fehlerwert" SG_ 1124 PSD_Attribut_Segment_ID 1;
BA_ "GenSigSwitchedByIgnition" SG_ 1124 PSD_Attribute_Komplett_06 0;
BA_ "GenSigStartValue" SG_ 1124 PSD_Ges_Typ 3;
BA_ "GenSigSwitchedByIgnition" SG_ 1124 PSD_Ges_Typ 0;
BA_ "GenSigSwitchedByIgnition" SG_ 1124 PSD_Steigung_1_Attribute_kompl 0;
BA_ "Fehlerwert" SG_ 1124 PSD_Steigung_1_Segment_ID 1;
BA_ "GenSigSwitchedByIgnition" SG_ 1124 PSD_Steigung_2_Attribute_kompl 0;
BA_ "Fehlerwert" SG_ 1124 PSD_Steigung_2_Segment_ID 1;
BA_ "GenSigSendType" SG_ 1023 Quersperre_04_BZ 0;
BA_ "GenSigFuncType" SG_ 1023 Quersperre_04_BZ 1;
BA_ "GenSigSwitchedByIgnition" SG_ 1023 Quersperre_04_BZ 0;
BA_ "GenSigSendType" SG_ 1023 Quersperre_04_CRC 0;
BA_ "GenSigFuncType" SG_ 1023 Quersperre_04_CRC 2;
BA_ "GenSigSwitchedByIgnition" SG_ 1023 Quersperre_04_CRC 0;
BA_ "GenSigSendType" SG_ 1023 Quersperre_Anz_Sperre_Auslegen 3;
BA_ "GenSigSendType" SG_ 1023 Quersperre_Anz_Sperre_Einlegen 3;
BA_ "GenSigSendType" SG_ 1023 Quersperre_Anz_Sperre_Geschl 3;
BA_ "GenSigSendType" SG_ 1023 Quersperre_Istzustand 3;
BA_ "GenSigSwitchedByIgnition" SG_ 1023 Quersperre_Istzustand 0;
BA_ "Fehlerwert" SG_ 1023 Quersperre_Istzustand 7;
BA_ "GenSigSendType" SG_ 1023 Quersperre_Status 3;
BA_ "GenSigSwitchedByIgnition" SG_ 1023 Quersperre_Status 0;
BA_ "GenSigSendType" SG_ 1529 RDK_angelernt 0;
BA_ "GenSigSwitchedByIgnition" SG_ 1529 RDK_angelernt 0;
BA_ "GenSigSendType" SG_ 1529 RDK_FMVSS138_Lampe 0;
BA_ "GenSigSwitchedByIgnition" SG_ 1529 RDK_FMVSS138_Lampe 0;
BA_ "GenSigSendType" SG_ 1529 RDK_FMVSS138_MIL 0;
BA_ "GenSigSwitchedByIgnition" SG_ 1529 RDK_FMVSS138_MIL 0;
BA_ "GenSigSendType" SG_ 1529 RDK_Kalibrierung 0;
BA_ "GenSigSwitchedByIgnition" SG_ 1529 RDK_Kalibrierung 0;
BA_ "GenSigSendType" SG_ 1529 RDK_Reifendruck_Lampe 0;
BA_ "GenSigSwitchedByIgnition" SG_ 1529 RDK_Reifendruck_Lampe 0;
BA_ "GenSigSendType" SG_ 1529 RDK_Reifentemperatur_Lampe 0;
BA_ "GenSigSwitchedByIgnition" SG_ 1529 RDK_Reifentemperatur_Lampe 0;
BA_ "GenSigSendType" SG_ 1529 RDK_RS_aktiv 0;
BA_ "GenSigSwitchedByIgnition" SG_ 1529 RDK_RS_aktiv 0;
BA_ "GenSigSendType" SG_ 1529 RDK_Text_7 0;
BA_ "GenSigSwitchedByIgnition" SG_ 1529 RDK_Text_7 0;
BA_ "GenSigSendType" SG_ 1529 RDK_W_1_Reifen_HL 0;
BA_ "GenSigSwitchedByIgnition" SG_ 1529 RDK_W_1_Reifen_HL 0;
BA_ "GenSigSendType" SG_ 1529 RDK_W_1_Reifen_HR 0;
BA_ "GenSigSwitchedByIgnition" SG_ 1529 RDK_W_1_Reifen_HR 0;
BA_ "GenSigSendType" SG_ 1529 RDK_W_1_Reifen_VL 0;
BA_ "GenSigSwitchedByIgnition" SG_ 1529 RDK_W_1_Reifen_VL 0;
BA_ "GenSigSendType" SG_ 1529 RDK_W_1_Reifen_VR 0;
BA_ "GenSigSwitchedByIgnition" SG_ 1529 RDK_W_1_Reifen_VR 0;
BA_ "GenSigSendType" SG_ 1529 RDK_W_2_Reifen_HL 0;
BA_ "GenSigSwitchedByIgnition" SG_ 1529 RDK_W_2_Reifen_HL 0;
BA_ "GenSigSendType" SG_ 1529 RDK_W_2_Reifen_HR 0;
BA_ "GenSigSwitchedByIgnition" SG_ 1529 RDK_W_2_Reifen_HR 0;
BA_ "GenSigSendType" SG_ 1529 RDK_W_2_Reifen_VL 0;
BA_ "GenSigSwitchedByIgnition" SG_ 1529 RDK_W_2_Reifen_VL 0;
BA_ "GenSigSendType" SG_ 1529 RDK_W_2_Reifen_VR 0;
BA_ "GenSigSwitchedByIgnition" SG_ 1529 RDK_W_2_Reifen_VR 0;
BA_ "GenSigSendType" SG_ 1529 RDK_Warnungen_02 0;
BA_ "GenSigSwitchedByIgnition" SG_ 1529 RDK_Warnungen_02 0;
BA_REL_ "GenSigTimeoutTime" BU_SG_REL_ ELV SG_ 2600468496 NM_Gateway_NM_State 2000;
BA_REL_ "GenSigTimeoutTime" BU_SG_REL_ ELV SG_ 2600468507 NM_HUD_NM_State 2000;
BA_REL_ "GenSigTimeoutTime" BU_SG_REL_ ELV SG_ 2600468500 NM_Kombi_NM_State 2000;
BA_REL_ "GenSigTimeoutTime" BU_SG_REL_ Gateway_Max SG_ 2600468529 NM_ELV_CBV_AWB 2000;
BA_REL_ "GenSigTimeoutTime" BU_SG_REL_ Gateway_Max SG_ 2600468529 NM_ELV_CBV_CRI 2000;
BA_REL_ "GenSigTimeoutTime" BU_SG_REL_ Gateway_Max SG_ 2600468529 NM_ELV_Car_Wakeup 2000;
BA_REL_ "GenSigTimeoutTime" BU_SG_REL_ Gateway_Max SG_ 2600468529 NM_ELV_CAB_V14 2000;
BA_REL_ "GenSigTimeoutTime" BU_SG_REL_ Gateway_Max SG_ 2600468507 NM_HUD_CBV_AWB 2000;
BA_REL_ "GenSigTimeoutTime" BU_SG_REL_ Gateway_Max SG_ 2600468507 NM_HUD_CBV_CRI 2000;
BA_REL_ "GenSigTimeoutTime" BU_SG_REL_ Gateway_Max SG_ 2600468507 NM_HUD_Car_WakeUp 2000;
BA_REL_ "GenSigTimeoutTime" BU_SG_REL_ Gateway_Max SG_ 2600468507 NM_HUD_CAB_V14 2000;
BA_REL_ "GenSigTimeoutTime" BU_SG_REL_ Gateway_Max SG_ 2600468500 NM_Kombi_CBV_AWB 2000;
BA_REL_ "GenSigTimeoutTime" BU_SG_REL_ Gateway_Max SG_ 2600468500 NM_Kombi_CBV_CRI 2000;
BA_REL_ "GenSigTimeoutTime" BU_SG_REL_ Gateway_Max SG_ 2600468500 NM_Kombi_Car_Wakeup 2000;
BA_REL_ "GenSigTimeoutTime" BU_SG_REL_ Gateway_Max SG_ 2600468500 NM_Kombi_CAB_V14 2000;
BA_REL_ "GenSigTimeoutTime" BU_SG_REL_ HUD SG_ 2331595982 PTUIPwrm_PrctPwrSysCur 500;
BA_REL_ "GenSigTimeoutTime" BU_SG_REL_ HUD SG_ 2331595982 PTUIPwrm_PrctPwrElDrvCur 500;
BA_REL_ "GenSigTimeoutTime" BU_SG_REL_ HUD SG_ 2331595982 PTHyDrA_StAcv 500;
BA_REL_ "GenSigTimeoutTime" BU_SG_REL_ HUD SG_ 2331595982 PTUIPwrm_StAcv 500;
BA_REL_ "GenSigTimeoutTime" BU_SG_REL_ HUD SG_ 2331595982 PTHyDrA_PrctUtilElDrv 500;
BA_REL_ "GenSigTimeoutTime" BU_SG_REL_ HUD SG_ 2331595982 PTUIPwrm_PrctPwrGnrMaxUse 500;
BA_REL_ "GenSigTimeoutTime" BU_SG_REL_ HUD SG_ 2331595982 PTUIPwrm_PrctPwrMotElMaxUse 500;
BA_REL_ "GenSigTimeoutTime" BU_SG_REL_ HUD SG_ 2331595982 PTUIPwrm_FacPwrDyn 500;
BA_REL_ "GenSigTimeoutTime" BU_SG_REL_ HUD SG_ 2331595982 PTUIPwrm_PrctPwrMotMaxUse 500;
BA_REL_ "GenSigTimeoutTime" BU_SG_REL_ HUD SG_ 2331595982 PTUIPwrm_PrctBoostAvl 500;
BA_REL_ "GenSigTimeoutTime" BU_SG_REL_ HUD SG_ 2331595982 PTUIPwrm_PrctPwrElBoostCur 500;
BA_REL_ "GenSigTimeoutTime" BU_SG_REL_ HUD SG_ 2331595982 PTUIPwrm_PrctPwrElBoostMaxUse 500;
BA_REL_ "GenSigTimeoutTime" BU_SG_REL_ HUD SG_ 2331595982 PTUIPwrm_PwrElBoostNom 500;
BA_REL_ "GenSigTimeoutTime" BU_SG_REL_ HUD SG_ 2589283946 PTUIPwrm_PwrMotElNom 5000;
BA_REL_ "GenSigTimeoutTime" BU_SG_REL_ HUD SG_ 2589283946 PTUIPwrm_PwrGnrNom 5000;
BA_REL_ "GenSigTimeoutTime" BU_SG_REL_ HUD SG_ 2600468529 NM_ELV_NM_State 2000;
BA_REL_ "GenSigTimeoutTime" BU_SG_REL_ HUD SG_ 2600468496 NM_Gateway_NM_State 2000;
BA_REL_ "GenSigTimeoutTime" BU_SG_REL_ HUD SG_ 2600468500 NM_Kombi_NM_State 2000;
BA_REL_ "GenSigTimeoutTime" BU_SG_REL_ HUD SG_ 2527679498 Perso_Kontonummer 5000;
BA_REL_ "GenSigTimeoutTime" BU_SG_REL_ HUD SG_ 2527679498 Perso_Steuerung 5000;
BA_REL_ "GenSigTimeoutTime" BU_SG_REL_ HUD SG_ 2527679498 Perso_Steuerungsparameter 5000;
BA_REL_ "GenSigTimeoutTime" BU_SG_REL_ HUD SG_ 2527679498 Perso_Status 5000;
BA_REL_ "GenSigTimeoutTime" BU_SG_REL_ HUD SG_ 319 SC_PreCrash_Warnung 2000;
BA_REL_ "GenSigTimeoutTime" BU_SG_REL_ HUD SG_ 1122 PSD_Segment_ID 1500;
BA_REL_ "GenSigTimeoutTime" BU_SG_REL_ HUD SG_ 1122 PSD_Segmentlaenge 1500;
BA_REL_ "GenSigTimeoutTime" BU_SG_REL_ HUD SG_ 1122 PSD_Endkruemmung 1500;
BA_REL_ "GenSigTimeoutTime" BU_SG_REL_ HUD SG_ 1122 PSD_Endkruemmung_Vorz 1500;
BA_REL_ "GenSigTimeoutTime" BU_SG_REL_ HUD SG_ 1122 PSD_Anfangskruemmung 1500;
BA_REL_ "GenSigTimeoutTime" BU_SG_REL_ HUD SG_ 1122 PSD_Anfangskruemmung_Vorz 1500;
BA_REL_ "GenSigTimeoutTime" BU_SG_REL_ HUD SG_ 1122 PSD_Abzweigerichtung 1500;
BA_REL_ "GenSigTimeoutTime" BU_SG_REL_ HUD SG_ 1122 PSD_Abzweigewinkel 1500;
BA_REL_ "GenSigTimeoutTime" BU_SG_REL_ HUD SG_ 1123 PSD_Pos_Segment_ID 1500;
BA_REL_ "GenSigTimeoutTime" BU_SG_REL_ HUD SG_ 1123 PSD_Pos_Segmentlaenge 1500;
BA_REL_ "GenSigTimeoutTime" BU_SG_REL_ HUD SG_ 1124 PSD_06_Mux 1500;
BA_REL_ "GenSigTimeoutTime" BU_SG_REL_ HUD SG_ 1124 PSD_Sys_Laendercode 1500;
BA_REL_ "GenSigTimeoutTime" BU_SG_REL_ Kombi SG_ 2331595982 PTUIPwrm_PrctPwrSysCur 500;
BA_REL_ "GenSigTimeoutTime" BU_SG_REL_ Kombi SG_ 2331595982 PTUIPwrm_PrctPwrElDrvCur 500;
BA_REL_ "GenSigTimeoutTime" BU_SG_REL_ Kombi SG_ 2331595982 PTHyDrA_StAcv 500;
BA_REL_ "GenSigTimeoutTime" BU_SG_REL_ Kombi SG_ 2331595982 PTUIPwrm_StAcv 500;
BA_REL_ "GenSigTimeoutTime" BU_SG_REL_ Kombi SG_ 2331595982 PTHyDrA_PrctUtilElDrv 500;
BA_REL_ "GenSigTimeoutTime" BU_SG_REL_ Kombi SG_ 2331595982 PTUIPwrm_PrctPwrGnrMaxUse 500;
BA_REL_ "GenSigTimeoutTime" BU_SG_REL_ Kombi SG_ 2331595982 PTUIPwrm_PrctPwrMotElMaxUse 500;
BA_REL_ "GenSigTimeoutTime" BU_SG_REL_ Kombi SG_ 2331595982 PTUIPwrm_FacPwrDyn 500;
BA_REL_ "GenSigTimeoutTime" BU_SG_REL_ Kombi SG_ 2331595982 PTUIPwrm_PrctPwrMotMaxUse 500;
BA_REL_ "GenSigTimeoutTime" BU_SG_REL_ Kombi SG_ 2331595982 PTUIPwrm_PrctBoostAvl 500;
BA_REL_ "GenSigTimeoutTime" BU_SG_REL_ Kombi SG_ 2331595982 PTUIPwrm_PrctPwrElBoostCur 500;
BA_REL_ "GenSigTimeoutTime" BU_SG_REL_ Kombi SG_ 2331595982 PTUIPwrm_PrctPwrElBoostMaxUse 500;
BA_REL_ "GenSigTimeoutTime" BU_SG_REL_ Kombi SG_ 2331595982 PTUIPwrm_PwrElBoostNom 500;
BA_REL_ "GenSigTimeoutTime" BU_SG_REL_ Kombi SG_ 2331595982 PTUIPwrm_PrctPwrEcoMaxUse 500;
BA_REL_ "GenSigTimeoutTime" BU_SG_REL_ Kombi SG_ 2331595982 PTUIPwrm_PrctPwrSysMaxUseTemp 500;
BA_REL_ "GenSigTimeoutTime" BU_SG_REL_ Kombi SG_ 2589283946 PTUIPwrm_PwrMotElNom 5000;
BA_REL_ "GenSigTimeoutTime" BU_SG_REL_ Kombi SG_ 2589283946 PTUIPwrm_PwrGnrNom 5000;
BA_REL_ "GenSigTimeoutTime" BU_SG_REL_ Kombi SG_ 2589283946 PTUIPwrm_PwrSysMotNomDisp 5000;
BA_REL_ "GenSigTimeoutTime" BU_SG_REL_ Kombi SG_ 1601 MO_Hybridfahrzeug 5000;
BA_REL_ "GenSigTimeoutTime" BU_SG_REL_ Kombi SG_ 1601 MO_StartStopp_Codiert 5000;
BA_REL_ "GenSigTimeoutTime" BU_SG_REL_ Kombi SG_ 1601 MO_Anzeige_StSt_gueltig 5000;
BA_REL_ "GenSigTimeoutTime" BU_SG_REL_ Kombi SG_ 1601 MO_Anzahl_Zyl 5000;
BA_REL_ "GenSigTimeoutTime" BU_SG_REL_ Kombi SG_ 1601 MO_Kraftstoffart 5000;
BA_REL_ "GenSigTimeoutTime" BU_SG_REL_ Kombi SG_ 1601 MO_Leistung 5000;
BA_REL_ "GenSigTimeoutTime" BU_SG_REL_ Kombi SG_ 391 MO_Waehlpos 1000;
BA_REL_ "GenSigTimeoutTime" BU_SG_REL_ Kombi SG_ 391 MO_Tankbereitschaft_Status 1000;
BA_REL_ "GenSigTimeoutTime" BU_SG_REL_ Kombi SG_ 813 MO_Fuellstand_LPG 500;
BA_REL_ "GenSigTimeoutTime" BU_SG_REL_ Kombi SG_ 813 MO_CNG_LPG 500;
BA_REL_ "GenSigTimeoutTime" BU_SG_REL_ Kombi SG_ 813 MO_CNG_Tankstopp 500;
BA_REL_ "GenSigTimeoutTime" BU_SG_REL_ Kombi SG_ 813 MO_LPG_Tankstopp 500;
BA_REL_ "GenSigTimeoutTime" BU_SG_REL_ Kombi SG_ 813 MO_AnzeigeGasbetrieb 500;
BA_REL_ "GenSigTimeoutTime" BU_SG_REL_ Kombi SG_ 813 MO_akt_Betrieb 500;
BA_REL_ "GenSigTimeoutTime" BU_SG_REL_ Kombi SG_ 813 MO_Erdgasqualitaet 500;
BA_REL_ "GenSigTimeoutTime" BU_SG_REL_ Kombi SG_ 813 MO_Verbrauchsaequivalent 500;
BA_REL_ "GenSigTimeoutTime" BU_SG_REL_ Kombi SG_ 813 MO_Tankmasse_CNG 500;
BA_REL_ "GenSigTimeoutTime" BU_SG_REL_ Kombi SG_ 813 MO_Tankvolumen_LPG 500;
BA_REL_ "GenSigTimeoutTime" BU_SG_REL_ Kombi SG_ 813 MO_Fuellungsgrad_CNG 500;
BA_REL_ "GenSigTimeoutTime" BU_SG_REL_ Kombi SG_ 813 MO_Fuellungsgrad_LPG 500;
BA_REL_ "GenSigTimeoutTime" BU_SG_REL_ Kombi SG_ 813 MO_CNG_Ueberlauf 500;
BA_REL_ "GenSigTimeoutTime" BU_SG_REL_ Kombi SG_ 813 MO_LPG_Ueberlauf 500;
BA_REL_ "GenSigTimeoutTime" BU_SG_REL_ Kombi SG_ 813 MO_Verbrauch_CNG 500;
BA_REL_ "GenSigTimeoutTime" BU_SG_REL_ Kombi SG_ 813 MO_Verbrauch_LPG 500;
BA_REL_ "GenSigTimeoutTime" BU_SG_REL_ Kombi SG_ 1155 Mo_Powermeter_Grenze 5000;
BA_REL_ "GenSigTimeoutTime" BU_SG_REL_ Kombi SG_ 1155 MO_Powermeter_Charge_Grenze 5000;
BA_REL_ "GenSigTimeoutTime" BU_SG_REL_ Kombi SG_ 1155 MO_Powermeter_Grenze_strategisch 5000;
BA_REL_ "GenSigTimeoutTime" BU_SG_REL_ Kombi SG_ 1155 MO_Powermeter_untere_E_Grenze 5000;
BA_REL_ "GenSigTimeoutTime" BU_SG_REL_ Kombi SG_ 1155 MO_Powermeter_obere_E_Grenze 5000;
BA_REL_ "GenSigTimeoutTime" BU_SG_REL_ Kombi SG_ 1284 MVK_01_CRC 1000;
BA_REL_ "GenSigTimeoutTime" BU_SG_REL_ Kombi SG_ 1284 MVK_01_BZ 1000;
BA_REL_ "GenSigTimeoutTime" BU_SG_REL_ Kombi SG_ 1284 MVK_MV_Batteriewarnung 1000;
BA_REL_ "GenSigTimeoutTime" BU_SG_REL_ Kombi SG_ 1284 MVK_MV_Netz_Warnungen 1000;
BA_REL_ "GenSigTimeoutTime" BU_SG_REL_ Kombi SG_ 2600468529 NM_ELV_NM_State 2000;
BA_REL_ "GenSigTimeoutTime" BU_SG_REL_ Kombi SG_ 2600468496 NM_Gateway_NM_State 2000;
BA_REL_ "GenSigTimeoutTime" BU_SG_REL_ Kombi SG_ 2600468507 NM_HUD_NM_State 2000;
BA_REL_ "GenSigTimeoutTime" BU_SG_REL_ Kombi SG_ 2589284143 OBMI_StAct 5000;
BA_REL_ "GenSigTimeoutTime" BU_SG_REL_ Kombi SG_ 2589284143 OBMI_FlgTrig 5000;
BA_REL_ "GenSigTimeoutTime" BU_SG_REL_ Kombi SG_ 2589284143 OBMI_StDrvRngUnit 5000;
BA_REL_ "GenSigTimeoutTime" BU_SG_REL_ Kombi SG_ 2589284143 OBMI_DDrvRngRem 5000;
BA_REL_ "GenSigTimeoutTime" BU_SG_REL_ Kombi SG_ 1175 PH_Stoermeldung 1000;
BA_REL_ "GenSigTimeoutTime" BU_SG_REL_ Kombi SG_ 1355 PH_Verschmutzungsmeldung 5000;
BA_REL_ "GenSigTimeoutTime" BU_SG_REL_ Kombi SG_ 2527679498 Perso_Kontonummer 5000;
BA_REL_ "GenSigTimeoutTime" BU_SG_REL_ Kombi SG_ 2527679498 Perso_Steuerung 5000;
BA_REL_ "GenSigTimeoutTime" BU_SG_REL_ Kombi SG_ 2527679498 Perso_Steuerungsparameter 5000;
BA_REL_ "GenSigTimeoutTime" BU_SG_REL_ Kombi SG_ 2527679498 Perso_Status 5000;
BA_REL_ "GenSigTimeoutTime" BU_SG_REL_ Kombi SG_ 1166 PLA_Status_Aktive_Seite 1000;
BA_REL_ "GenSigTimeoutTime" BU_SG_REL_ Kombi SG_ 1166 PLA_Anf_Anzeige_Mini 1000;
BA_REL_ "GenSigTimeoutTime" BU_SG_REL_ Kombi SG_ 1166 PLA_Mini_Modus 1000;
BA_REL_ "GenSigTimeoutTime" BU_SG_REL_ Kombi SG_ 1166 PLA_Anf_Akustik 1000;
BA_REL_ "GenSigTimeoutTime" BU_SG_REL_ Kombi SG_ 1166 PLA_Anf_Anzeige_Schwellpfeil 1000;
BA_REL_ "GenSigTimeoutTime" BU_SG_REL_ Kombi SG_ 1166 PLA_Anf_Anzeige_Bremsfuss 1000;
BA_REL_ "GenSigTimeoutTime" BU_SG_REL_ Kombi SG_ 1166 PLA_Anf_Anzeigemodus 1000;
BA_REL_ "GenSigTimeoutTime" BU_SG_REL_ Kombi SG_ 1166 PLA_Anf_Meldungen 1000;
BA_REL_ "GenSigTimeoutTime" BU_SG_REL_ Kombi SG_ 1166 PLA_Status_Funktion 1000;
BA_REL_ "GenSigTimeoutTime" BU_SG_REL_ Kombi SG_ 319 SC_PreCrash_Warnung 2000;
BA_REL_ "GenSigTimeoutTime" BU_SG_REL_ Kombi SG_ 319 SC_PreCrash_Texte 2000;
BA_REL_ "GenSigTimeoutTime" BU_SG_REL_ Kombi SG_ 1124 PSD_06_Mux 1500;
BA_REL_ "GenSigTimeoutTime" BU_SG_REL_ Kombi SG_ 1124 PSD_Sys_Laendercode 1500;
BA_REL_ "GenSigTimeoutTime" BU_SG_REL_ Kombi SG_ 1023 Quersperre_Anz_Sperre_Einlegen 5000;
BA_REL_ "GenSigTimeoutTime" BU_SG_REL_ Kombi SG_ 1023 Quersperre_Anz_Sperre_Auslegen 5000;
BA_REL_ "GenSigTimeoutTime" BU_SG_REL_ Kombi SG_ 1023 Quersperre_Anz_Sperre_Geschl 5000;
BA_REL_ "GenSigTimeoutTime" BU_SG_REL_ Kombi SG_ 1529 RDK_FMVSS138_Lampe 5000;
BA_REL_ "GenSigTimeoutTime" BU_SG_REL_ Kombi SG_ 1529 RDK_FMVSS138_MIL 5000;
BA_REL_ "GenSigTimeoutTime" BU_SG_REL_ Kombi SG_ 1529 RDK_Kalibrierung 5000;
BA_REL_ "GenSigTimeoutTime" BU_SG_REL_ Kombi SG_ 1529 RDK_Warnungen_02 5000;
VAL_ 2331595982 PTUIPwrm_PrctPwrSysCur 4094 "nicht_vorhanden" 4095 "Init" ;
VAL_ 2331595982 PTUIPwrm_PrctPwrElDrvCur 4094 "nicht vorhanden" 4095 "Init" ;
VAL_ 2331595982 PTHyDrA_StAcv 0 "aus_keine_Anzeige" 1 "inaktiv" 2 "aktiv" 3 "Init" ;
VAL_ 2331595982 PTUIPwrm_StAcv 0 "aus_keine_Anzeige" 1 "inaktiv" 2 "aktiv" 3 "Init" ;
VAL_ 2331595982 PTHyDrA_PrctUtilElDrv 2046 "NotAvailable" 2047 "Init" ;
VAL_ 2331595982 PTUIPwrm_PrctPwrGnrMaxUse 2046 "nicht_vorhanden" 2047 "Init" ;
VAL_ 2331595982 PTUIPwrm_PrctPwrMotElMaxUse 2046 "nicht vorhanden" 2047 "Init" ;
VAL_ 2331595982 PTUIPwrm_FacPwrDyn 126 "nicht_vorhanden" 127 "Init" ;
VAL_ 2331595982 PTUIPwrm_PrctPwrMotMaxUse 2046 "nicht_vorhanden" 2047 "Init" ;
VAL_ 2331595982 PTUIPwrm_PrctBoostAvl 1022 "nicht_vorhanden" 1023 "InitWert" ;
VAL_ 2331595982 PTUIPwrm_PrctPwrElBoostCur 1022 "nicht_vorhanden" 1023 "InitWert" ;
VAL_ 2331595982 PTUIPwrm_PrctPwrElBoostMaxUse 1022 "nicht_vorhanden" 1023 "InitWert" ;
VAL_ 2331595982 PTUIPwrm_PwrElBoostNom 1022 "nicht_vorhanden" 1023 "Init" ;
VAL_ 2331595982 PTUIPwrm_PrctPwrEcoMaxUse 2046 "nicht_vorhanden" 2047 "Init" ;
VAL_ 2331595982 PTUIPwrm_PrctPwrSysMaxUseTemp 2046 "nicht_vorhanden" 2047 "Init" ;
VAL_ 2589283946 PTUIPwrm_PwrMotElNom 2046 "nicht_vorhanden" 2047 "Init" ;
VAL_ 2589283946 PTUIPwrm_PwrGnrNom 2046 "nicht_vorhanden" 2047 "Init" ;
VAL_ 2589283946 PTUIPwrm_PwrSysMotNomDisp 2046 "nicht_vorhanden" 2047 "Init" ;
VAL_ 1601 MO_Faktor_Momente_02 0 "nicht_belegt" ;
VAL_ 1601 MO_Hybridfahrzeug 0 "kein_Hybridfahrzeug" 1 "Mild_Hybrid" 2 "Full_Hybrid" 3 "PlugIn_Hybrid" ;
VAL_ 1601 MO_Getriebe_Code 0 "Init" 2 "DL501" 3 "DL800" 4 "VL381" 5 "DL382_Front" 6 "DL382_Allrad" 7 "DL702" 8 "AL552_Allrad" 9 "AL552_Front" 10 "AL651" 11 "AL551__AL951__AL1000_8A" 12 "PDK_PAG" 13 "AL551_Hybrid" 15 "Handschalter_konventionell" 16 "AQ250_160" 17 "AQ450" 18 "DQ200" 19 "DQ250" 20 "DQ500" 21 "SQ100" 22 "SQ200" 23 "DQ400E" 24 "DQ381" 25 "AL550" 26 "AQ300" 31 "DL800E" 32 "Single_Gear__ohne_GSG_WH_am_MSG" 33 "EQ550_2P" ;
VAL_ 1601 MO_StartStopp_Codiert 0 "Start_Stopp_nicht_verbaut" 1 "Start_Stopp_verbaut" ;
VAL_ 1601 MO_Anzeige_StSt_gueltig 0 "MO_Text_Motorstart_gueltig" 1 "Signale_MO_Anzeige_StSt_gueltig" ;
VAL_ 1601 MO_Anzahl_Zyl 0 "kein_Zylinder" 1 "1_Zylinder" 2 "2_Zylinder" 3 "3_Zylinder" 4 "4_Zylinder" 5 "5_Zylinder" 6 "6_Zylinder" 7 "7_Zylinder" 8 "8_Zylinder" 9 "9_Zylinder" 10 "10_Zylinder" 11 "11_Zylinder" 12 "12_Zylinder" 13 "15_Zylinder" 14 "16_Zylinder" 15 "18_Zylinder" ;
VAL_ 1601 MO_Kraftstoffart 0 "Diesel" 1 "Benzin_inkl_E25_E85" 2 "CNG" 3 "LPG" 4 "Wasserstoff" 5 "E100_Ethanol" 15 "kein_Verbrennungskraftstoff" ;
VAL_ 1601 MO_Ansaugsystem 0 "Turbo" 1 "Sauger" ;
VAL_ 1601 MO_OBD_Typ 0 "NoOBD_RdW" 1 "EOBD" 2 "US_OBD" 3 "reserviert" ;
VAL_ 1601 MO_DPF_verbaut 0 "kein_DPF_verbaut" 1 "DPF_verbaut" ;
VAL_ 1601 TSK_Codierung 0 "kein_Fahrgeschwindigkeitsregler" 1 "GRA" 2 "GRA_Plus" 3 "Basis_ACC" 4 "ACC_Follow_to_Stop" 5 "ACC_Stop_and_Go" 7 "Codierung_in_Plausibilisierungsphase" ;
VAL_ 391 EV_Rekuperationsstufe 0 "keine_Anzeige" 1 "1" 2 "2" 3 "3" 4 "4" 5 "5" ;
VAL_ 391 MO_Waehlpos 0 "Init_nicht_unterstuetzt" 1 "reserviert" 2 "P" 3 "R" 4 "N" 5 "D" 6 "B" 7 "Fehler" ;
VAL_ 391 MO_Fehler_NTKreis 0 "kein_Fehler" 1 "Fehler" ;
VAL_ 391 MO_Fehler_Notabschaltung_Klima 0 "Init" 1 "HVIL_ist_OK" 2 "HVIL_Fehler" 3 "ohne_Funktion" ;
VAL_ 391 MO_KLE_FStatus 0 "kein_Fehler" 2 "Fehlerentprellung" 3 "Fehler" ;
VAL_ 391 MO_WH_Texte 0 "keine_Anzeige" 1 "ShiftLock__Fussbremse_betaetigen" 3 "Wegrollgefahr_bitte_P_einlegen" 4 "Parksperre_Warnstufe_I" 5 "Parksperre_Warnstufe_II" 6 "P_nur_im_Stillstand_moeglich" ;
VAL_ 391 MO_Tankbereitschaft_Status 0 "keine_Aktion_Init" 1 "Tankbereitschaft_wird_hergestellt" 2 "Tankbereitschaft_ist_hergestellt" 3 "Tankbereitschaft_kann_nicht_hergestellt_werden" 4 "Tanksystem_Systemfehler" 5 "Tankklappe_pruefen_schliessen" 6 "Tankvorgang_abgebrochen" ;
VAL_ 391 MO_Tankklappensteuerung 0 "Init_nicht_verbaut" 1 "Tankklappe_soll_entriegeln" 2 "Tankklappe_soll_verriegeln" 3 "keine_Aktion" ;
VAL_ 813 MO_Fuellstand_LPG 1022 "ungueltig" 1023 "Fehler" ;
VAL_ 813 MO_CNG_LPG 0 "CNG" 1 "LPG" ;
VAL_ 813 MO_CNG_Tankstopp 0 "kein_Tankstopp" 1 "Tankstopp_erkannt" ;
VAL_ 813 MO_LPG_Tankstopp 0 "kein_Tankstopp" 1 "Tankstopp_erkannt" ;
VAL_ 813 MO_AnzeigeGasbetrieb 0 "keine_Textmeldung" 1 "Umschaltung_Gasbetrieb" 2 "Gasbetrieb" 3 "Umschaltung_Benzinbetrieb" 4 "Benzinbetrieb" 5 "Umschaltung_nicht_moeglich" 6 "Gasbetrieb_nicht_moeglich" 7 "Benzintank_leer" 8 "GAP_CNG_Betrieb_verhindert" ;
VAL_ 813 MO_akt_Betrieb 0 "Benzinbetrieb" 1 "Gasbetrieb" ;
VAL_ 813 MO_Erdgasqualitaet 0 "Anzeige_in_MFA_Rolle_nicht_auswaehlbar" 1 "Qualitaet_xxx" 2 "Qualitaet_100" 3 "Qualitaet_90" 4 "Qualitaet_80" 5 "Qualitaet_70" 6 "Qualitaet_xxx" 7 "Qualitaet_xxx" ;
VAL_ 813 MO_Verbrauchsaequivalent 0 "Funktion_nicht_unterstuetzt" 254 "Init_Adaption_nach_Betankung" 255 "Fehler" ;
VAL_ 813 MO_Tankmasse_CNG 0 "Init" 255 "Fehler" ;
VAL_ 813 MO_Tankvolumen_LPG 0 "Init" 255 "Fehler" ;
VAL_ 813 MO_Fuellungsgrad_CNG 254 "Init" 255 "Fehler" ;
VAL_ 813 MO_Fuellungsgrad_LPG 254 "Init_ungueltig" 255 "Fehler" ;
VAL_ 813 MO_CNG_Ueberlauf 0 "kein_Ueberlauf" 1 "mind_1_Ueberlauf" ;
VAL_ 813 MO_LPG_Ueberlauf 0 "kein_Ueberlauf" 1 "mind_1_Ueberlauf" ;
VAL_ 1155 Mo_Powermeter_Grenze 4093 "OFF" ;
VAL_ 1155 MO_Powermeter_Inszenierung_aktiv 0 "keine_Anzeige" 1 "Inszenierung_aktiv" ;
VAL_ 1155 MO_Powermeter_Charge_Grenze 1022 "Init" 1023 "Fehler" ;
VAL_ 1155 MO_Powermeter_Grenze_strategisch 4094 "Init" 4095 "Fehler" ;
VAL_ 1155 MO_Powermeter_untere_E_Grenze 4094 "Init" 4095 "Fehler" ;
VAL_ 1155 MO_Powermeter_obere_E_Grenze 4094 "Init" 4095 "Fehler" ;
VAL_ 1284 MVK_DCDC_Sollmodus_02 0 "Standby" 1 "MV_On" 2 "Tiefsetzen" 3 "Hochsetzen" 4 "Startunterstuetzung_48V" 6 "Startunterstuetzung_12V" 7 "Init" 9 "MV_On_Notbetrieb" 10 "Tiefsetzen_Notbetrieb" 11 "Pruefpuls_12V" 13 "Reaktivierung_BMS" ;
VAL_ 1284 MVK_MV_Batteriewarnung 0 "Keine_Warnung" 1 "Warnung_Temperatur_Level1" 2 "Warnung_Temperatur_Level2" ;
VAL_ 1284 MV_Bordnetz_belastbar 0 "nicht_belastbar" 1 "belastbar" ;
VAL_ 1284 MV_Bordnetz_aktiv 0 "inaktiv" 1 "aktiv" ;
VAL_ 1284 MVK_BOOST_Sollmodus 0 "Keine_Freigabe" 1 "Freigabe" 7 "Init" ;
VAL_ 1284 MVK_eABC_Sollmodus 0 "Keine_Freigabe" 1 "Freigabe" 7 "Init" ;
VAL_ 1284 MVK_eAWS_Sollmodus 0 "Keine_Freigabe" 1 "Freigabe" 7 "Init" ;
VAL_ 1284 MV_Bordnetz_Fehler 0 "kein_Fehler" 1 "Fehler" ;
VAL_ 1284 MVK_MVPTC_Sollmodus 0 "Keine_Freigabe" 1 "Freigabe" 7 "Init" ;
VAL_ 1284 MVK_Istmodus_Anf 0 "nicht_angefordert" 1 "angefordert" ;
VAL_ 1284 MVK_MO_EmSollzustand 0 "MvOff" 1 "MvStbyReq" 2 "MvStbyWait" 3 "MvBattOnReq" 4 "MvBattOnWait" 10 "MvOnIdle" 18 "MvOnDrvReq" 19 "MvOnDrvWait" 20 "MvOnDrv" 28 "MvStepUpReq" 29 "MvStepUpWait" 30 "MvStepUp" 38 "MvStepDownReq" 39 "MvStepDownWait" 40 "MvStepDown" 96 "MvCpntOffReq" 97 "MvCpntOffWait" 98 "MvBattOffReq" 99 "MvBattOffWait" 109 "MvDcDcFailOffReq" 110 "MvDcDcFail" 119 "MvElmFailOffReq" 120 "MvElmFail" 126 "MvFailCpntOffReq" 127 "MvFailCpntOffWait" 128 "MvFailBattOffReq" 129 "MvFailBattOffWait" 130 "MvFailBattOff" 138 "MvFailUCtlReq" 139 "MvFailUCtlWait" 140 "MvFailUCtl" 150 "MvEmgcyOff" 255 "Init" ;
VAL_ 1284 MVK_BMS_Sollmodus 0 "MV_Off" 1 "MV_On" 7 "Init" ;
VAL_ 1284 MVK_DCDC_Sollmodus 0 "Standby" 1 "MV_On" 2 "Tiefsetzen" 3 "Hochsetzen" 4 "Startunterstuetzung_48V" 6 "Startunterstuetzung_12V" 7 "Init" ;
VAL_ 1284 MVK_MV_Netz_Warnungen 0 "Keine_Warnung" 1 "Warntext_MV_Netz_Anf" 2 "Fehlertext_MV_Netz_Anf" 3 "Warnung_Kein_Wiederstart_moeglic" ;
VAL_ 1156 ND_VDOP 1022 "Init" 1023 "Fehler" ;
VAL_ 1156 ND_TDOP 1022 "Init" 1023 "Fehler" ;
VAL_ 1156 ND_HDOP 1022 "Init" 1023 "Fehler" ;
VAL_ 1156 ND_GDOP 1022 "Init" 1023 "Fehler" ;
VAL_ 1156 ND_PDOP 1022 "Init" 1023 "Fehler" ;
VAL_ 1156 ND_Heading 4094 "Init" 4095 "Fehler" ;
VAL_ 1156 ND_Init 0 "nicht_Initialisiert" 1 "Initialisiert" ;
VAL_ 1157 ND_SatInUse 30 "Init" 31 "Fehler" ;
VAL_ 1157 POS_Guete_horizontal_verfuegbar 0 "nicht_verfuegbar" 1 "verfuegbar" ;
VAL_ 1157 ND_SatInView 30 "Init" 31 "Fehler" ;
VAL_ 1157 POS_Guete_horizontal 124 "von_248m_bis_400m" 125 "mehr_als_400m" 126 "Init" 127 "Fehler" ;
VAL_ 1157 NP_Altitude 4094 "Init" 4095 "Fehler" ;
VAL_ 1158 NP_LatDegree 134217726 "Init" 134217727 "Fehler" ;
VAL_ 1158 NP_LongDegree 268435454 "Init" 268435455 "Fehler" ;
VAL_ 1158 NP_LatDirection 0 "Nord" 1 "Sued" ;
VAL_ 1158 NP_LongDirection 0 "Ost" 1 "West" ;
VAL_ 1158 NP_Sat 30 "Init" 31 "Fehler" ;
VAL_ 1158 NP_Fix 0 "Init" 1 "No_Fix" 2 "2D_Fix" 3 "3D_Fix" ;
VAL_ 2600468529 NM_ELV_CBV_AWB 0 "Passiver_WakeUp" 1 "Aktiver_WakeUp" ;
VAL_ 2600468529 NM_ELV_CBV_CRI 0 "NM_ohne_Clusteranforderungen" 1 "NM_mit_Clusteranforderungen" ;
VAL_ 2600468529 NM_ELV_NM_State 0 "Init" 1 "NM_RM_aus_BSM" 2 "NM_RM_aus_PBSM" 4 "NM_NO_aus_RM" 8 "NM_NO_aus_RS" 16 "reserved" 32 "reserved" ;
VAL_ 2600468529 NM_ELV_Car_Wakeup 0 "Inaktiv" 1 "Car_Wakeup" ;
VAL_ 2600468529 NM_ELV_UDS_CC 0 "Inaktiv" 1 "CC_aktiv" ;
VAL_ 2600468529 NM_ELV_NM_aktiv_KL15 0 "Inaktiv" 1 "KL15_EIN" ;
VAL_ 2600468529 NM_ELV_NM_aktiv_Diagnose 0 "Init" 1 "Diagnose_aktiv" ;
VAL_ 2600468529 NM_ELV_NM_aktiv_Tmin 0 "Inaktiv" 1 "Mindestaktivzeit" ;
VAL_ 2600468529 NM_ELV_NM_aktiv_Meldung 1 "Meldung_aktiv" ;
VAL_ 2600468529 NM_ELV_NM_aktiv_Verfahrtrigger 1 "Trigger_aktiv" ;
VAL_ 2600468529 NM_ELV_NM_aktiv_WFS 1 "WFS_Komm_aktiv" ;
VAL_ 2600468529 NM_ELV_CAB_V14 0 "Init" 1 "CAB_01_Antrieb" 2 "CAB_02_Hybrid_Laden" 4 "CAB_03_Fahrwerk" 8 "CAB_04_Fahrerassistenz" 16 "CAB_05_Komfort" 32 "CAB_06_Anzeige" 64 "CAB_07_Connect" 128 "CAB_08_MIB" 256 "CAB_09_Standheizung" 1024 "CAB_11_VLAN_Fahrerassistenz" 2048 "CAB_12_VLAN_Komfort" 4096 "CAB_13_VLAN_Connect" 8192 "CAB_14_VLAN_Infotainment" 16384 "CAB_15_Laden" 32768 "CAB_16_Licht" ;
VAL_ 2600468496 NM_Gateway_CBV_AWB 0 "Passiver_WakeUp" 1 "Aktiver_WakeUp" ;
VAL_ 2600468496 NM_Gateway_CBV_CRI 0 "NM_ohne_Clusteranforderungen" 1 "NM_mit_Clusteranforderungen" ;
VAL_ 2600468496 NM_Gateway_NM_State 0 "Init" 1 "NM_RM_aus_BSM" 2 "NM_RM_aus_PBSM" 4 "NM_NO_aus_RM" 8 "NM_NO_aus_RS" 16 "reserved" 32 "reserved" ;
VAL_ 2600468496 NM_Gateway_Car_Wakeup 0 "Inaktiv" 1 "Car_Wakeup" ;
VAL_ 2600468496 NM_Gateway_UDS_CC 0 "Inaktiv" 1 "CC_aktiv" ;
VAL_ 2600468496 NM_Gateway_NM_aktiv_KL15 0 "Inaktiv" 1 "KL15_EIN" ;
VAL_ 2600468496 NM_Gateway_NM_aktiv_Diagnose 0 "Init" 1 "Diagnose_aktiv" ;
VAL_ 2600468496 NM_Gateway_NM_aktiv_Tmin 0 "Inaktiv" 1 "Mindestaktivzeit" ;
VAL_ 2600468496 NM_Gateway_NM_aktiv_CWU 0 "kein_CWU_gesetzt" 1 "CWU_gesetzt" ;
VAL_ 2600468496 NM_Gateway_NM_aktiv_FC 0 "kein_FC_gesetzt" 1 "FC_gesetzt" ;
VAL_ 2600468496 NM_Gateway_NM_aktiv_EM 0 "inaktiv" 1 "Nachlauf_aufgrund_Energiemanagement" ;
VAL_ 2600468496 NM_Gateway_NM_aktiv_Buskopplung 0 "inaktiv" 1 "Nachlauf_aufgrund_Buskopplung" ;
VAL_ 2600468496 NM_Gateway_CAB_V14 0 "Init" 1 "CAB_01_Antrieb" 2 "CAB_02_Hybrid_Laden" 4 "CAB_03_Fahrwerk" 8 "CAB_04_Fahrerassistenz" 16 "CAB_05_Komfort" 32 "CAB_06_Anzeige" 64 "CAB_07_Connect" 128 "CAB_08_MIB" 256 "CAB_09_Standheizung" 1024 "CAB_11_VLAN_Fahrerassistenz" 2048 "CAB_12_VLAN_Komfort" 4096 "CAB_13_VLAN_Connect" 8192 "CAB_14_VLAN_Infotainment" 16384 "CAB_15_Laden" 32768 "CAB_16_Licht" ;
VAL_ 2600468507 NM_HUD_CBV_AWB 0 "Passiver_WakeUp" 1 "Aktiver_WakeUp" ;
VAL_ 2600468507 NM_HUD_CBV_CRI 0 "NM_ohne_Clusteranforderungen" 1 "NM_mit_Clusteranforderungen" ;
VAL_ 2600468507 NM_HUD_NM_State 0 "Init" 1 "NM_RM_aus_BSM" 2 "NM_RM_aus_PBSM" 4 "NM_NO_aus_RM" 8 "NM_NO_aus_RS" 16 "reserved" 32 "reserved" ;
VAL_ 2600468507 NM_HUD_Car_WakeUp 0 "Inaktiv" 1 "Car_Wakeup" ;
VAL_ 2600468507 NM_HUD_UDS_CC 0 "Inaktiv" 1 "CC_aktiv" ;
VAL_ 2600468507 NM_HUD_NM_aktiv_KL15 0 "Inaktiv" 1 "KL15_EIN" ;
VAL_ 2600468507 NM_HUD_NM_aktiv_Diagnose 0 "Init" 1 "Diagnose_aktiv" ;
VAL_ 2600468507 NM_HUD_NM_aktiv_Tmin 0 "Inaktiv" 1 "Mindestaktivzeit" ;
VAL_ 2600468507 NM_HUD_CAB_V14 0 "Init" 1 "CAB_01_Antrieb" 2 "CAB_02_Hybrid_Laden" 4 "CAB_03_Fahrwerk" 8 "CAB_04_Fahrerassistenz" 16 "CAB_05_Komfort" 32 "CAB_06_Anzeige" 64 "CAB_07_Connect" 128 "CAB_08_MIB" 256 "CAB_09_Standheizung" 1024 "CAB_11_VLAN_Fahrerassistenz" 2048 "CAB_12_VLAN_Komfort" 4096 "CAB_13_VLAN_Connect" 8192 "CAB_14_VLAN_Infotainment" 16384 "CAB_15_Laden" 32768 "CAB_16_Licht" ;
VAL_ 2600468500 NM_Kombi_CBV_AWB 0 "Passiver_WakeUp" 1 "Aktiver_WakeUp" ;
VAL_ 2600468500 NM_Kombi_CBV_CRI 0 "Standard_Layout" 1 "TNB_Layout" ;
VAL_ 2600468500 NM_Kombi_NM_State 0 "Init" 1 "NM_RM_aus_BSM" 2 "NM_RM_aus_PBSM" 4 "NM_NO_aus_RM" 8 "NM_NO_aus_RS" 16 "reserved" 32 "reserved" ;
VAL_ 2600468500 NM_Kombi_Car_Wakeup 0 "Inaktiv" 1 "Car_Wakeup" ;
VAL_ 2600468500 NM_Kombi_UDS_CC 0 "Init" 1 "CC_aktiv" ;
VAL_ 2600468500 NM_Kombi_NM_aktiv_KL15 0 "Inaktiv" 1 "KL15_EIN" ;
VAL_ 2600468500 NM_Kombi_NM_aktiv_Diagnose 0 "Init" 1 "Diagnose_aktiv" ;
VAL_ 2600468500 NM_Kombi_NM_aktiv_Tmin 0 "Inaktiv" 1 "Mindestaktivzeit" ;
VAL_ 2600468500 NM_Kombi_NM_aktiv_Buzzer 1 "Buzzer_aktiv" ;
VAL_ 2600468500 NM_Kombi_NM_aktiv_Schluesselkomm 1 "Schluesselkomm_aktiv" ;
VAL_ 2600468500 NM_Kombi_NM_aktiv_VLW 0 "Init" 1 "VLW_aktiv" ;
VAL_ 2600468500 NM_Kombi_CAB_V14 0 "Init" 1 "CAB_01_Antrieb" 2 "CAB_02_Hybrid_Laden" 4 "CAB_03_Fahrwerk" 8 "CAB_04_Fahrerassistenz" 16 "CAB_05_Komfort" 32 "CAB_06_Anzeige" 64 "CAB_07_Connect" 128 "CAB_08_MIB" 256 "CAB_09_Standheizung" 1024 "CAB_11_VLAN_Fahrerassistenz" 2048 "CAB_12_VLAN_Komfort" 4096 "CAB_13_VLAN_Connect" 8192 "CAB_14_VLAN_Infotainment" 16384 "CAB_15_Laden" 32768 "CAB_16_Licht" ;
VAL_ 527 NVEM_IBatt 255 "Fehler" ;
VAL_ 527 NVEM_MOD_Budget 15 "Init" ;
VAL_ 527 NVEM_MOD_Freigabe 0 "Freigabe_MOD" 1 "Freigabe_MOD_nur_mit_HV" 2 "Stopp_Kein_Wiederholen_Fehler" 3 "Init" ;
VAL_ 527 NVEM_MV_DC_iSoll_NV 254 "Init" 255 "Fehler" ;
VAL_ 527 NVEM_DC_iSoll_NV 254 "Init" 255 "Fehler" ;
VAL_ 527 NVEM_DC_uSoll_NV 255 "Fehler" ;
VAL_ 1630 OBD_TG_F_Status_1 0 "kein Fehler / Init / nicht verbaut" 1 "KS- (Kurzschluss nach minus)" 2 "KS+ (Kurzschluss nach plus)" 3 "OC (Leitungsunterbrechung)" 4 "OOR+ (Signal zu gross)" 5 "OOR- (Signal zu klein)" 6 "RC+ (Signal unplausibel zu gross)" 7 "RC- (Signal unplausibel zu klein)" 8 "KS+/OC (Kurzschluss nach plus/Unterbrechung)" 9 "KS-/OC  (Kurzschluss nach minus/Unterbrechung)" 10 "KS-/KS+  (Kurzschluss nach minus/plus)" 11 "KS-/KS+/OC (Kurzschluss nach minus/plus/Unterbrechung)" 12 "frei" 13 "frei" 14 "frei" 15 "frei" ;
VAL_ 1630 OBD_TG_F_Status_2 0 "kein Fehler / Init / nicht verbaut" 1 "KS- (Kurzschluss nach minus)" 2 "KS+ (Kurzschluss nach plus)" 3 "OC (Leitungsunterbrechung)" 4 "OOR+ (Signal zu gross)" 5 "OOR- (Signal zu klein)" 6 "RC+ (Signal unplausibel zu gross)" 7 "RC- (Signal unplausibel zu klein)" 8 "KS+/OC (Kurzschluss nach plus/Unterbrechung)" 9 "KS-/OC  (Kurzschluss nach minus/Unterbrechung)" 10 "KS-/KS+  (Kurzschluss nach minus/plus)" 11 "KS-/KS+/OC (Kurzschluss nach minus/plus/Unterbrechung)" 12 "frei" 13 "frei" 14 "frei" 15 "frei" ;
VAL_ 1630 OBD_TG_F_Status_3 0 "kein Fehler / Init / nicht verbaut" 1 "KS- (Kurzschluss nach minus)" 2 "KS+ (Kurzschluss nach plus)" 3 "OC (Leitungsunterbrechung)" 4 "OOR+ (Signal zu gross)" 5 "OOR- (Signal zu klein)" 6 "RC+ (Signal unplausibel zu gross)" 7 "RC- (Signal unplausibel zu klein)" 8 "KS+/OC (Kurzschluss nach plus/Unterbrechung)" 9 "KS-/OC  (Kurzschluss nach minus/Unterbrechung)" 10 "KS-/KS+  (Kurzschluss nach minus/plus)" 11 "KS-/KS+/OC (Kurzschluss nach minus/plus/Unterbrechung)" 12 "frei" 13 "frei" 14 "frei" 15 "frei" ;
VAL_ 1630 OBD_TG_F_Status_4 0 "kein Fehler / Init / nicht verbaut" 1 "KS- (Kurzschluss nach minus)" 2 "KS+ (Kurzschluss nach plus)" 3 "OC (Leitungsunterbrechung)" 4 "OOR+ (Signal zu gross)" 5 "OOR- (Signal zu klein)" 6 "RC+ (Signal unplausibel zu gross)" 7 "RC- (Signal unplausibel zu klein)" 8 "KS+/OC (Kurzschluss nach plus/Unterbrechung)" 9 "KS-/OC  (Kurzschluss nach minus/Unterbrechung)" 10 "KS-/KS+  (Kurzschluss nach minus/plus)" 11 "KS-/KS+/OC (Kurzschluss nach minus/plus/Unterbrechung)" 12 "frei" 13 "frei" 14 "frei" 15 "frei" ;
VAL_ 2589284143 OBMI_StAct 0 "Warnung_nicht_aktiv" 1 "Warnstufe_1_aktiv" 2 "Warnstufe_2_aktiv" 3 "Warnstufe_3_aktiv" ;
VAL_ 2589284143 OBMI_FlgTrig 0 "Warnung_Retrigger_nicht_aktiv" 1 "Warnung_Retrigger_aktiv" ;
VAL_ 2589284143 OBMI_StDrvRngUnit 0 "Restreichweite_Kilometer" 1 "Restreichweite_Meilen" ;
VAL_ 2589284143 OBMI_DDrvRngRem 8190 "Init" ;
VAL_ 2589283656 ORU_Warnung 0 "keine_Anzeige" 1 "Update_unvollstaendig_Prio1" 2 "Update_fehlgeschlagen_Prio1" 3 "reserviert" ;
VAL_ 2589283656 ORU_Status 0 "IDLE" 1 "PENDING" 2 "PREPARATION" 3 "PREPARATION_HV" 4 "RUNNING" 5 "RUNNING_HV" 6 "PENDING_NOTREADY" 7 "FAILURE_POWERTRAIN_DISABLED" ;
VAL_ 1175 PH_Visualisierung 0 "Aus" 1 "Angefragt" 2 "InAnzeige" 3 "Abgefordert" 6 "Init" 7 "Fehler" ;
VAL_ 1175 PDC_Tonausgabe_Front 0 "kein_Ton" 1 "Intervallton_1" 2 "Intervallton_2" 3 "Intervallton_3" 4 "Intervallton_4" 5 "Intervallton_5" 6 "Dauerton" 7 "Fehlerton" 8 "RCTATon" ;
VAL_ 1175 PDC_Tonausgabe_Heck 0 "kein_Ton" 1 "Intervallton_1" 2 "Intervallton_2" 3 "Intervallton_3" 4 "Intervallton_4" 5 "Intervallton_5" 6 "Dauerton" 7 "Fehlerton" 8 "Erstwarnton_hinten" 9 "RCTATon" ;
VAL_ 1175 PH_nachtr_Stopp_Anf 0 "nicht_angefordert" 1 "angefordert" ;
VAL_ 1175 PH_Abschaltursache 0 "keine, bzw. System aktiv" 1 "Abschaltung durch Herausnahme R-Gang" 2 "Abschaltung ueber Geschwindigkeit" 3 "Abschaltung ueber PDC-Taster" 4 "Abschaltung wegen PLA" 5 "Abschaltung durch KL 15 Bit = 0" 6 "tbd." 7 "Fehler-/gestört Zustand, System noch aktiv" ;
VAL_ 1175 PH_Opt_Anzeige_V_ein 0 "optische Anzeige vorne nicht aktiv" 1 "optische Anzeige vorne aktiviert" ;
VAL_ 1175 PH_Opt_Anzeige_H_ein 0 "Optische Anzeige aus" 1 "optische Anzeige hinten aktiviert" ;
VAL_ 1175 PH_Opt_Anz_V_Hindernis 0 "optische Anzeige vorne meldet kein Hindernis" 1 "optische Anzeige vorne meldet Hindernis im Warnbereich" ;
VAL_ 1175 PH_Opt_Anz_H_Hindernis 0 "optische Anzeige hinten meldet kein Hindernis" 1 "optische Anzeige hinten meldet Hindernis im Warnbereich" ;
VAL_ 1175 PH_Tongeber_V_aktiv 0 "Tongeber vorne nicht aktiv" 1 "Tongeber vorne  aktiv" ;
VAL_ 1175 PH_Tongeber_H_aktiv 0 "Tongeber hinten nicht aktiv" 1 "Tongeber hinten aktiv" ;
VAL_ 1175 PH_Tongeber_mute 0 "Tongeber nicht stummgeschaltet" 1 "Tongeber stummgeschaltet" ;
VAL_ 1175 PH_Anf_Audioabsenkung 0 "Keine_Audioabsenkung" 1 "Anforderung_Audioabsenkung" ;
VAL_ 1175 PH_Tongeber_H_verfuegbar 0 "nicht verfügbar" 1 "verfügbar" ;
VAL_ 1175 PLA_Anf_Aufschaltung_RVC 0 "Keine_RVC_Aufschalteanf" 1 "RVC_Aufschalteanforderung" ;
VAL_ 1175 PH_Taster 0 "Taster_nicht_gedrueckt" 1 "Taster_gedrueckt" 2 "reserviert" 3 "Fehler" ;
VAL_ 1175 PH_Anf_Verdeck 0 "Verdeckbetrieb_freigegeben" 1 "Verdeckbetrieb_sperren" 2 "reserviert" 3 "reserviert" ;
VAL_ 1175 PH_StartStopp_Info 0 "Motorlauf_nicht_notwendig_(Stoppfreigabe)" 1 "Motoranlauf_nicht_zwingend_notwendig_(Stoppverbot,keine_Startanforderung)" 2 "Motoranlauf_zwingend_notwendig_(Startanforderung)" 3 "Systemfehler" ;
VAL_ 1175 PH_Stoermeldung 0 "keine_Anzeige_kein_Gong" 1 "Textmeldung_PDC_hinten_gestoert_mit_Gong" 2 "Textmeldung_PDC_hinten_gestoert_ohne_Gong" 3 "Textmeldung_PDC_vorn_gestoert_mit_Gong" 4 "Textmeldung_PDC_vorn_gestoert_ohne_Gong" 5 "Textmeldung_PDC_gestoert_mit_Gong" 6 "Textmeldung_PDC_gestoert_ohne_Gong" 7 "Textmeldung_PDC_seitlich_gestoert_mit_Gong" 8 "Textmeldung_PDC_seitlich_gestoert_ohne_Gong" ;
VAL_ 1175 PH_defekt 0 "PH aktiv" 1 "PH wurde aufgrund eines Defektes deaktiviert" ;
VAL_ 1175 PH_gestoert 0 "PH aktiv" 1 "PH wurde auf Grund einer Stoerung tempraer deaktiviert" ;
VAL_ 1175 PH_Systemzustand 0 "Anlage aus" 1 "Anlage durch einlegen R-Gang aktiviert" 2 "Anlage manuell durch Taster aktiviert" 3 "Anlage automatisch aktiviert" 4 "Anlage durch ARA aktiviert" 6 "Init - Initialisierungsphase nach Kl. 15 ein / Reset" 7 "Fehler-/gestört Zustand, System noch aktiv" ;
VAL_ 1175 PH_Display_Kundenwunsch 0 "Anzeige aus" 1 "Grafik" 2 "Rear View" 3 "automatisch" ;
VAL_ 1355 RBFMA_PaCo_BrakeIntervention 0 "Inactive" 1 "Active_Rear" 2 "Active_Front" 3 "Active_Left" 4 "Active_Right" ;
VAL_ 1355 RBFMA_PaCo_MainState 0 "Init" 1 "InOperation_NoError" 2 "Eingeschraenkt" 7 "Fehler" ;
VAL_ 1355 RAB_PaCo_FunctionState 0 "nicht_verfuegbar" 1 "im_Hintergrund" 2 "in_Anzeige" 3 "in_Aktivierung" 4 "in_Regelung" ;
VAL_ 1355 RBF_Anf_Meldungen 0 "Init" 1 "RBF_eingeschraenkt_Sensorsicht" 2 "RBF_eingeschraenkt_Reinigung" 3 "RBF_nicht_verfuegbar" 4 "RBF_Notbremsung" 5 "RBF_zurzeit_eingeschraenkt" 6 "RBF_eingeschraenkt_reinigen" ;
VAL_ 1355 PH_Verschmutzungsmeldung 0 "keine_Anzeige_kein_Gong" 1 "Textmeldung_PDC_hinten_verschmutzt_mit_Gong" 2 "Textmeldung_PDC_hinten_verschmutzt_ohne_Gong" 3 "Textmeldung_PDC_vorn_verschmutzt_mit_Gong" 4 "Textmeldung_PDC_vorn_verschmutzt_ohne_Gong" 5 "Textmeldung_PDC_verschmutzt_mit_Gong" 6 "Textmeldung_PDC_verschmutzt_ohne_Gong" 7 "Textmeldung_PDC_seitlich_verschmutzt_mit_Gong" 8 "Textmeldung_PDC_seitlich_verschmutzt_ohne_Gong" ;
VAL_ 1355 PH_Aufschaltursache 0 "Anlage aus" 1 "Anlage durch einlegen R-Gang aktiviert" 2 "Anlage manuell durch Taster aktiviert" 3 "Anlage automatisch aktiviert" 4 "Anlage durch ARA aktiviert" 5 "Rueckwaertsrollen" 6 "Anlage_durch_PLA_aktiviert" 7 "Anlage_durch_IPA_aktiviert" 8 "Anlage_durch_FA_aktiviert" 9 "Anlage_durch_RBF_oder_MA_aktiviert" 10 "Anlage_durch_Smartphone_aktiviert" 11 "Anlage_durch_Jokertaste_aktiviert" 12 "Anlage_durch_Favoritentasten_aktiviert" 13 "Anlage_durch_SideViewTaster_aktiviert" 14 "Anlage_durch_RCTA_aktiviert" 15 "Anlage_durch_KAS_aktiviert" 16 "Anlage_durch_AWC_aktiviert" 30 "Init_Initialisierungsphase_nach_Kl_15_ein_oder_Reset" 31 "Fehler_gestoerter_Zustand_System_noch_aktiv" ;
VAL_ 1355 PH_Ton_Ausgabe 0 "Init" 1 "Intervallton_vorne" 2 "Intervallton_hinten" 3 "Dauerton_vorne" 4 "Dauerton_hinten" 5 "Quittierungston" 6 "Reserviert" 7 "Fehler" ;
VAL_ 1355 PH_Ton_Pausenlaenge 0 "Init" 1 "Pause_5ms" 2 "Pause_10ms" 3 "Pause_15ms" 100 "Pause_500ms" 101 "Reserviert" 126 "Reserviert" 127 "Fehler" ;
VAL_ 1355 APSOPS_PaCo_ObstacleDetectRear 0 "None" 1 "LongDistance_OutsideDriveTube" 2 "LongDistance_InsideDriveTube" 3 "ShortDistance_OutsideDriveTube" 4 "ShortDistance_InsideDriveTube" ;
VAL_ 1355 APSOPS_PaCo_ObstacleDetectFront 0 "None" 1 "LongDistance_OutsideDriveTube" 2 "LongDistance_InsideDriveTube" 3 "ShortDistance_OutsideDriveTube" 4 "ShortDistance_InsideDriveTube" ;
VAL_ 1355 APSOPS_PaCo_Button 0 "Init_or_not_equipped" 1 "Button_not_pressed" 2 "Button_pressed_debounced" 3 "Error" ;
VAL_ 1355 APSOPS_PaCo_MainState 0 "Init" 1 "InOperation_NoError" 7 "Fehler" ;
VAL_ 1355 APSOPS_PaCo_FunctionState 0 "No_Error" 1 "Sensor_Defect" 2 "Sensor_Contaminated" ;
VAL_ 1355 APSOPS_PaCo_ApproachingRear 0 "No_Obstacle_Approaching" 1 "Obstacle_Approaching" ;
VAL_ 1355 APSOPS_PaCo_ApproachingFront 0 "No_Obstacle_Approaching" 1 "Obstacle_Approaching" ;
VAL_ 1355 APS_PaCo_WarningTones 0 "Not_Possible" 1 "Possible" ;
VAL_ 1355 PH_Ton_Richtung 0 "vorne" 1 "vorne_rechts" 2 "rechts" 3 "rechts_hinten" 4 "hinten" 5 "hinten_links" 6 "links" 7 "vorne_links" ;
VAL_ 1355 PH_Ton_Lautstaerke 0 "Minimallautstaerke" 1 "Lautstaerke_1" 2 "Lautstaerke_2" 3 "Lautstaerke_3" 4 "Lautstaerke_4" 5 "Lautstaerke_5" 6 "Lautstaerke_6" 7 "Maximallautstaerke" ;
VAL_ 1355 PH_WAH_Meldung 0 "Init" 1 "Fehlermeldung_bei_Nichtverfuegbarkeit_mit_Gong" 2 "Fehlermeldung_bei_Nichtverfuegbarkeit_ohne_Gong" 3 "Anzeige_dass_Fahrzeug_erkannt_wurde_und_Funktion_aktiv_ist" 4 "Wiederanfahrhinweis_mit_Gong" 5 "Wiederanfahrhinweis_ohne_Gong" ;
VAL_ 1355 RBF_PaCo_Anf_Meldungen 0 "Init" 1 "RBF_eingeschraenkt_Sensorsicht" 2 "RBF_eingeschraenkt_Reinigung" 3 "RBF_nicht_verfuegbar" 4 "RBF_Notbremsung" 5 "RBF_zurzeit_eingeschraenkt" 6 "RBF_eingeschraenkt_reinigen" ;
VAL_ 1355 RBF_PMO_Bereich_erkannt 0 "Nicht_erkannt" 1 "Erkannt" ;
VAL_ 2527679498 Perso_Kontonummer 0 "kein_Benutzerkonto" 1 "Benutzerkonto_1" 2 "Benutzerkonto_2" 3 "Benutzerkonto_3" 4 "Benutzerkonto_4" 5 "Benutzerkonto_5" 6 "Benutzerkonto_6" 7 "Benutzerkonto_7" ;
VAL_ 2527679498 Perso_Steuerung 0 "keine_Steuerung" 1 "Reset_alle_Konten" 2 "Reset_aktives_Konto" 3 "Kopiere_aktives_Konto_nach" 4 "Wiederherstellen_aktives_Konto" 5 "Aktivieren_aktives_Konto" 6 "Reset_Konto" 7 "Reset_alle_Fahrer" 8 "Reset_aktiver_Fahrer" 9 "Reset_Fahrer" ;
VAL_ 2527679498 Perso_Steuerungsparameter 0 "kein_Parameter" 1 "Benutzerkonto_1" 2 "Benutzerkonto_2" 3 "Benutzerkonto_3" 4 "Benutzerkonto_4" 5 "Benutzerkonto_5" 6 "Benutzerkonto_6" 7 "Benutzerkonto_7" ;
VAL_ 2527679498 Perso_Status 0 "deaktiviert" 1 "PSO_1x_aktiviert" 2 "PSO_2x_aktiviert" ;
VAL_ 2527679498 Perso_Bedienstelle 0 "Init" 1 "Kombiinstrument" 2 "ABT" ;
VAL_ 2527679498 Perso_Freigabe_Verstellung 0 "Init" 1 "freigegeben" ;
VAL_ 2527679498 Perso_Aktiv 0 "deaktiviert" 1 "aktiviert" ;
VAL_ 2527679498 IAA_PSO_wake_up 0 "wake_up_inactive" 1 "wake_up_active" ;
VAL_ 2527679498 Perso_Fahrernummer 0 "kein_Fahrer" 1 "Fahrer_1" 2 "Fahrer_2" 3 "Fahrer_3" 4 "Fahrer_4" 5 "Fahrer_5" 6 "Fahrer_6" 7 "Fahrer_7" ;
VAL_ 2527679498 Perso_Schreibschutz 0 "Schreibschutz_deaktiviert" 1 "Schreibschutz_aktiviert" ;
VAL_ 1166 PLA_Anforderung_HMS 0 "keine_Anforderung_Init" 1 "Halten" 2 "Parken" 3 "Halten_standby" 4 "Anfahren" 5 "Loesen_ueber_Rampe" 6 "Parken_mit_P" 7 "reserviert" ;
VAL_ 1166 PLA_Status_Aktive_Seite 0 "Rechts" 1 "Links" ;
VAL_ 1166 PLA_Anf_Anzeige_Mini 0 "keine_Anzeige" 1 "Miniaturanzeige" ;
VAL_ 1166 PLA_Mini_Modus 0 "kein_Mini_angezeigt" 1 "Mini_Laengsparken" 2 "Mini_Rueckwaerts_Querparken_mit_Vorbeifahrt" 3 "Mini_Vorwaerts_Querparken_ohne_VB" 4 "Mini_Vorwaerts_Querparken_mit_VB" 5 "weitere_Parkmoeglichkeit_vorhanden" 6 "Garagenparken" 7 "Mini_Rueckwaerts_Querparken_ohne_Vorbeifahrt" ;
VAL_ 1166 PLA_Anf_Akustik 0 "keine_Akustik" 1 "Akustik__Gong_1000" ;
VAL_ 1166 PLA_Anf_Anzeige_Schwellpfeil 0 "Keine_Schwellpfeilanzeige" 1 "Anzeige_Schwellpfeil" ;
VAL_ 1166 PLA_Anf_Anzeige_Bremsfuss 0 "Keine_Anzeige_Bremsfuss" 1 "Anzeige_Bremsfuss" ;
VAL_ 1166 PLA_Anf_Anzeigemodus 0 "Keine_Anzeige" 1 "Anzeige_AP_verfuegbar" 2 "Laengsparken_Singlescreen" 3 "Reserved" 4 "Rueckwaerts_Querparken_mit_VB" 5 "Rueckwaerts_Querparken_ohne_VB" 6 "Vorwaerts_Querparken_ohne_VB" 7 "Vorwaerts_Querparken_mit_VB" 8 "Ausparken_Laengsparken_Single" 9 "Garagenparken_vorwaerts" 10 "Garagenparken_rueckwaerts" 11 "Textmeldung_hochprior" 12 "Textmeldungen_niederprior" 13 "Anzeige_beidseitig" 14 "Anzeige_einseitig" 15 "Anzeige_PL_verfuegbar" ;
VAL_ 1166 PLA_Anf_Meldungen 0 "keine_Meldung" 1 "PLA_beendet" 2 "RBF_deaktiviert" 3 "Autosuche_ESC_ASR_Eingriff" 4 "PLA_temp_n_a_ESC_ASR_Fehler" 5 "PLA_temp_n_a_Anhaenger_gesteckt" 6 "Suche_Zeitlimit_ueberschritten" 7 "PLA_zurzeit_n_verfuegbar" 8 "PLA_defekt_Werkstatt" 9 "Stillstandzeit_n_ausreichend" 11 "AP_Blinker_setzen_u_RWG_einlegen" 12 "AP_n_moeglich_PL_zu_klein" 13 "RBF_aktiv" 14 "PLA_beendet_v_zu_hoch" 15 "PLA_beendet_Schiebetuer_offen" 16 "Gegenseite_versperrt" 17 "Parken_n_a_Luecke_zu_klein" 18 "PLA_im_Offroad_Modus_n_a" 21 "AP_Blinker_setzen_u_Softkey_MIB" 22 "Start_Softkey_am_MIB_betaetigen" 23 "RBF_Hindernis_erkannt" 24 "RBF_temp_beendet" 25 "RBF_Gaspedal_loesen" 26 "RBF_Bremse_betaetigen" 27 "RBF_n_a_temp" 28 "RBF_n_a_temp_Anhaenger" 29 "RBF_n_a_temp_Sensorsicht" 30 "RBF_n_a_temp_ESC" 31 "RBF_n_a_temp_Drive_Select" 32 "Einparken_am_MIB_bestaetigen" 40 "info_v_reduzieren" 41 "info_v_begrenzt" 42 "info_Wiederaufnahme" 43 "info_Richtungsw_rueckw" 44 "info_Richtungsw_vorw" 128 "Disclaimer_LP_rechts" 129 "Disclaimer_LP_links" 130 "Disclaimer_RQ_rechts" 131 "Disclaimer_RQ_links" 136 "Disclaimer_VQ_rechts" 137 "Disclaimer_VQ_links" 138 "Disclaimer_AP_rechts" 139 "Disclaimer_AP_links" 144 "Abbruch_Lenkeingriff_Fahrer" 145 "Abbruch_Anhaenger_erkannt" 146 "Abbruch_ESC_deaktiv" 147 "Abbruch_Zeitlimit_ueberschritten" 148 "Lenkeingriff_beendet_uebernehmen" 149 "Abbruch_manuell_parken" 150 "Abbruch_v_zu_hoch" 151 "Abbruch_ESC_ASR_Eingriff" 152 "PLA_beendet_temp_n_a" 153 "PLA_defekt_Werkstatt" 154 "Lenkung_uebernehmen_Fahrt_forts" 155 "Abbr_AP_Luecke_zu_klein" 156 "Bremseingriff_v_zu_hoch" 157 "Abbruch_Hindernis_erkannt" 158 "PLA_Notbremsung_Bremse_betaetige" 159 "PLA_Notbr_Abbruch_Bremse_betaet" 160 "Abbr_Einp_Hindernis_erkannt" 161 "PLA_beendet_Lenkung_uebernehmen" 162 "Abbruch_Offroad_Modus_PLA_n_a" 163 "PLA_Abbruch_Schiebetuer_offen" 164 "Abbr_Luecke_zu_klein" 165 "RBF_temp_n_a" 166 "RBF_Bremse_betaetigen" 167 "Disclaimer_vorwaerts" 168 "RBF_Bitte_uebernehmen" 169 "RBF_Stoerung_Service" 170 "Disclaimer_rueckwaerts" 171 "Abbruch_Fluegeltuer_offen" 172 "Lenkeingriff_Aktiv_Bremsen" ;
VAL_ 1166 PLA_Status_Funktion 0 "PL_Suche" 1 "PL_Suche_Standby" 2 "PL_gefunden" 3 "POS_OK" 4 "Rangieren_vorwaerts" 5 "Rangieren_rueckwaerts" 6 "Disclaimer_in_Anzeige" 7 "Automodus_Wand" 8 "PP_Pos_OK" 11 "GP_Pos_OK" 14 "DP_Pos_OK" ;
VAL_ 1166 PLA_Status_beenden_Mini 0 "Funktion_vorhanden" 1 "Funktion_ausgewaehlt" 2 "Funktion_einparken_moeglich" 3 "Funktion_nicht_vorhanden" ;
VAL_ 1166 PLA_Status_Laengsparken_Mini 0 "Funktion_vorhanden" 1 "Funktion_ausgewaehlt" 2 "Funktion_einparken_moeglich" 3 "Funktion_nicht_vorhanden" ;
VAL_ 1166 PLA_Status_QP_Rueckw_Mini 0 "Funktion_vorhanden" 1 "Funktion_ausgewaehlt" 2 "Funktion_einparken_moeglich" 3 "Funktion_nicht_vorhanden" ;
VAL_ 1166 PLA_Status_QP_Vorw_Mini 0 "Funktion_vorhanden" 1 "Funktion_ausgewaehlt" 2 "Funktion_einparken_moeglich" 3 "Funktion_nicht_vorhanden" ;
VAL_ 319 PreCrash_Charisma_FahrPr 0 "keine_Funktion" 1 "Programm_1" 2 "Programm_2" 3 "Programm_3" 4 "Programm_4" 5 "Programm_5" 6 "Programm_6" 7 "Programm_7" 8 "Programm_8" 9 "Programm_9" 10 "Programm_10" 11 "Programm_11" 12 "Programm_12" 13 "Programm_13" 14 "Programm_14" 15 "Programm_15" ;
VAL_ 319 PreCrash_Charisma_Status 0 "Init" 1 "verfuegbar" 2 "nicht_verfuegbar" 3 "asynchron_durch_Fahrerwunsch" ;
VAL_ 319 PreCrash_Schiebedach_schliessen 0 "keine_Schliessung" 1 "Schliessung_angefordert" ;
VAL_ 319 PreCrash_Fenster_schliessen 0 "keine_Schliessung" 1 "Schliessung_angefordert" ;
VAL_ 319 PreCrash_Blinken 0 "keine_Blinkanforderung" 1 "Warnblinken" 2 "RECAS_Blinken" 3 "Notbremsblinken" ;
VAL_ 319 SC_PreSense_FCWP 0 "Warnung_gilt_fuer_Objekte" 1 "Warnung_gitl_fuer_Fussgaenger" ;
VAL_ 319 PreCrash_Tueren_Verriegeln 0 "keine_Anforderung" 1 "Tueren_Verriegeln" ;
VAL_ 319 PreCrash_FS_Laengsverstellung 0 "nicht_angefordert" 1 "angefordert" ;
VAL_ 319 PreCrash_Anforderung_AFR 0 "keine_Anforderung" 1 "linke_Seite" 2 "rechte_Seite" 3 "Vorderachse" 4 "Hinterachse" 5 "Vorwarnung" 7 "Init" ;
VAL_ 319 SC_PreCrash_LED 0 "keine_Anzeige" 1 "Stufe_1_glimmen" 2 "Stufe_2_leuchten" 3 "Stufe_3_blinken" ;
VAL_ 319 PreCrash_FS_Pneumatik_ansteuern 0 "keine_Anforderung" 1 "Pneumatik_ansteuern" ;
VAL_ 319 PreCrash_BFS_Pneumatik_ansteuern 0 "keine_Anforderung" 1 "Pneumatik_ansteuern" ;
VAL_ 319 PreCrash_Fo_Pneumatik_ansteuern 0 "keine_Anforderung" 1 "Pneumatik_ansteuern" ;
VAL_ 319 PreCrash_FS_Sitzlehne_verfahren 0 "keine_Anforderung" 1 "reserviert" 2 "reserviert" 3 "Sitzlehnenkopf_in_pos_xRichtung_verfahrenvor" 4 "Sitzlehnenkopf_in_neg_xRichtung_verfahrenzurueck" 6 "reserviert" 7 "Lehnenkopfverstellung_ansteuern" ;
VAL_ 319 PreCrash_BFS_Sitzlehne_verfahren 0 "keine_Anforderung" 1 "reserviert" 2 "reserviert" 3 "Sitzlehnenkopf_in_pos_xRichtung_verfahrenvor" 4 "Sitzlehnenkopf_in_neg_xRichtung_verfahrenzurueck" 6 "reserviert" 7 "Lehnenkopfverstellung_ansteuern" ;
VAL_ 319 PreCrash_Fo_Sitzlehne_verfahren 0 "keine_Anforderung" 1 "reserviert" 2 "reserviert" 3 "Sitzlehnenkopf_in_pos_xRichtung_verfahrenvor" 4 "Sitzlehnenkopf_in_neg_xRichtung_verfahrenzurueck" ;
VAL_ 319 PreCrash_FS_KSV_verfahren 0 "keine_Anforderung" 1 "in_pos_xRichtung_verfahren" 2 "in_neg_xRichung_verfahren" 3 "in_pos_zRichtung_verfahren" 4 "in_neg_zRichtung_verfahren" 5 "in_pos_xRichtung_und_neg_zRichtung_verfahren" 6 "in_pos_x_Richtung_und_pos_zRichtung_verfahren" 7 "in_neg_xRichtung_und_neg_zRichtung_verfahren" 8 "in_neg_xRichtung_und_pos_zRichtung_verfahren" 9 "Kopfstuetze_ansteuern" ;
VAL_ 319 PreCrash_BFS_KSV_verfahren 0 "keine_Anforderung" 1 "in_pos_xRichtung_verfahren" 2 "in_neg_xRichung_verfahren" 3 "in_pos_zRichtung_verfahren" 4 "in_neg_zRichtung_verfahren" 5 "in_pos_xRichtung_und_neg_zRichtung_verfahren" 6 "in_pos_x_Richtung_und_pos_zRichtung_verfahren" 7 "in_neg_xRichtung_und_neg_zRichtung_verfahren" 8 "in_neg_xRichtung_und_pos_zRichtung_verfahren" 9 "Kopfstuetze_ansteuern" ;
VAL_ 319 PreCrash_Fo_KSV_verfahren 0 "keine_Anforderung" 1 "in_pos_xRichtung_verfahren" 2 "in_neg_xRichung_verfahren" 3 "in_pos_zRichtung_verfahren" 4 "in_neg_zRichtung_verfahren" 5 "in_pos_xRichtung_und_neg_zRichtung_verfahren" 6 "in_pos_x_Richtung_und_pos_zRichtung_verfahren" 7 "in_neg_xRichtung_und_neg_zRichtung_verfahren" 8 "in_neg_xRichtung_und_pos_zRichtung_verfahren" ;
VAL_ 319 PreCrash_BFS_Laengsverstellung 0 "nicht_angefordert" 1 "angefordert" ;
VAL_ 319 SC_PreCrash_Warnung 0 "keine_Anzeige" 1 "latente_Vorwarnung" 2 "Vorwarnung" 3 "Akutwarnung" 4 "Eingriff" 5 "Fahreruebernahmeaufforderung" 6 "Abbiegewarnung" 7 "Basiseingriff" 8 "Heckeingriff" ;
VAL_ 319 SC_PreCrash_Texte 0 "keine_Anzeige" 1 "Systemstoerung" 2 "keine_Sensorsicht" 3 "Demomodus" 4 "System_aus" 5 "Anhaengerbetrieb" 6 "ESC_aus" 7 "zurzeit_eingeschraenkt" 8 "zurzeit_eingeschraenkt_ESP_Aus" 9 "Initialisierung" ;
VAL_ 1122 PSD_Segment_ID 0 "keine Segmentinformationen vorhanden" 1 "Fehlerwert" ;
VAL_ 1122 PSD_Vorgaenger_Segment_ID 0 "keine Segmentinformation vorhanden" 1 "Fehlerwert" ;
VAL_ 1122 PSD_Strassenkategorie 0 "Rest_Feldweg_Schotterweg_Privatweg" 1 "Ortsstraße" 2 "Kreisstraße" 3 "Landstraße" 4 "Bundesstraße" 5 "Autobahn" 7 "Init" ;
VAL_ 1122 PSD_Endkruemmung 255 "Gerade" ;
VAL_ 1122 PSD_Endkruemmung_Vorz 0 "Kruemmung_positiv" 1 "Kruemmung_negativ" ;
VAL_ 1122 PSD_Idenditaets_ID 0 "keine_Segment_Informationen_vorhanden" 1 "Fehler" ;
VAL_ 1122 PSD_ADAS_Qualitaet 0 "keine_ADAS_Qualitaet" 1 "ADAS_Qualitaet" ;
VAL_ 1122 PSD_wahrscheinlichster_Pfad 0 "Pfad_mit_geringer_Wahrscheinlichkeit" 1 "wahrscheinlichster_Pfad" ;
VAL_ 1122 PSD_Geradester_Pfad 0 "nicht_geradester_PFad" 1 "geradester_Pfad" ;
VAL_ 1122 PSD_Fahrspuren_Anzahl 0 "Einbahnstrasse_in_falsche_Richtung" 1 "eine_Fahrspur" 2 "zwei_Fahrspuren" 3 "drei_Fahrspuren" 4 "vier_Fahrspuren" 5 "fuenf_Fahrspuren" 6 "sechs_Fahrspuren" 7 "mehr_als_sechs_Fahrspuren" ;
VAL_ 1122 PSD_Bebauung 0 "ausserhalb_bebauten_Gebietes" 1 "innerhalb_bebauten_Gebietes" ;
VAL_ 1122 PSD_Segment_Komplett 0 "Segment_Attribute_nicht_komplett" 1 "Segment_Attribute_komplett" ;
VAL_ 1122 PSD_Rampe 0 "Strasse_mit_Gegenverkehr" 1 "Auffahrt_Einbahnstr" 2 "Abfahrt_Einbahnstr" 3 "Einbahnstrasse" ;
VAL_ 1122 PSD_Anfangskruemmung 255 "Gerade" ;
VAL_ 1122 PSD_Anfangskruemmung_Vorz 0 "positiv" 1 "negativ" ;
VAL_ 1122 PSD_Abzweigerichtung 0 "rects_abzweigende_Strasse" 1 "links_abzweigende_Strasse" ;
VAL_ 1123 PSD_Pos_Segment_ID 0 "keine Position gegeben" 1 "Fehlerwert" ;
VAL_ 1123 PSD_Pos_Standort_Eindeutig 0 "mehrdeutiger_Standort" 1 "eindeutiger_Standort" ;
VAL_ 1123 PSD_Pos_Fehler_Laengsrichtung 0 "Init" 1 "< 2m" 2 "< 5m" 3 "< 10m" 4 "< 20m" 5 "< 50m" 6 "> 50m" 7 "Off-Road" ;
VAL_ 1123 PSD_Pos_Fahrspur 0 "unbekannt" 1 "Erste_Spur_von_rechts" 2 "Zweite_Spur_von_rechts" 3 "Dritte_Spur_von_rechts" 4 "Vierte_Spur_von_rechts" 5 "Fuenfte_Spur_von_rechts" 6 "Sechte_Spur_von_rechts" 7 "Siebte_oder_weitere_Spur_von_rechts" ;
VAL_ 1123 PSD_Attribut_Segment_ID_05 0 "keine_Segment_Information" 1 "Fehler" ;
VAL_ 1123 PSD_Attribut_1_ID 0 "keine_Information" ;
VAL_ 1123 PSD_Attribut_2_ID 0 "keine_Information" ;
VAL_ 1123 PSD_Attribute_Komplett_05 0 "Attribute_nicht_komplett" 1 "Attribute_komplett" ;
VAL_ 1124 PSD_06_Mux 0 "Init" ;
VAL_ 1124 PSD_Sys_Segment_ID 0 "keine Segmentinformationen vorhanden" 1 "nicht zulaessig" ;
VAL_ 1124 PSD_Attribut_Segment_ID 0 "keine_Segment_Information_vorhanden" 1 "Fehler" ;
VAL_ 1124 PSD_Ges_Segment_ID 0 "keine Segmentinformationen vorhanden" 1 "nicht zulaessig" ;
VAL_ 1124 PSD_Baum_Laenge_VZ 0 "Ost" 1 "West" ;
VAL_ 1124 PSD_Steigung_1_Segment_ID 0 "keine_Segment_Information_vorhanden" 1 "Fehler" ;
VAL_ 1124 PSD_Baum_Laenge 33554431 "keine_GPS_Information" ;
VAL_ 1124 PSD_Attribut_3_ID 0 "keine_Information" ;
VAL_ 1124 PSD_Steigung_1_A_Steigung 126 "mehr_als_15_Prozent" 127 "Steigung_unbekannt" ;
VAL_ 1124 PSD_Ges_Geschwindigkeit 0 "Kein Geschwindigkeitsgebot" 1 "0 km/h < v_max <  5 km/h" 2 "5 km/h < v_max < 10km/h" 3 "10 km/h < v_max < 15 km/h" 4 "15 km/h < v_max < 20 km/h" 5 "20 km/h < v_max < 25 km/h" 6 "25 km/h < v_max < 30 km/h" 7 "30 km/h < v_max < 35 km/h" 8 "35 km/h < v_max < 40 km/h" 9 "40 km/h < v_max < 45 km/h" 10 "45 km/h < v_max < 50 km/h" 11 "50 km/h < v_max < 60 km/h" 12 "60 km/h < v_max < 70 km/h" 13 "70 km/h < v_max < 80 km/h" 14 "80 km/h < v_max < 90 km/h" 15 "90 km/h < v_max < 100 km/h" 16 "100 km/h < v_max < 110 km/h" 17 "110 km/h < v_max < 120 km/h" 18 " 120 km/h < v_max < 130 km/h" 19 "130 km/h < v_max < 140 km/h" 20 "140 km/h < v_max < 150 km/h" 21 "150 km/h < v_max < 160 km/h" 22 "160 km/h < v_max" 23 "Geschwindigkeitsgebot aufgehoben" 24 "..0x1F ungültig" ;
VAL_ 1124 PSD_Steigung_1_A_Vorz 0 "Gefaelle" 1 "Steigung" ;
VAL_ 1124 PSD_Sys_Geschwindigkeit_Einheit 0 "km/h" 1 "mph" ;
VAL_ 1124 PSD_Sys_Verkehrsrichtung 0 "Rechtsverkehr" 1 "Linksverkehr" ;
VAL_ 1124 PSD_Sys_Geometrieguete 0 "Geringe_Guete" 1 "tbd" 2 "tbd" 3 "Hohe_Guete" ;
VAL_ 1124 PSD_Sys_Mapmatchingguete 0 "geringe_Guete" 1 "res" 2 "res" 3 "hohe_Guete" ;
VAL_ 1124 PSD_Ges_Typ 0 "Geschw_Klasse_des_Kartendatensuppliers" 1 "Explizit_abgeleiteten_Begrenzung" 2 "Durch_Gesetzg_vorgeg_allgem_Gebot_fuer_uebertr_Rahmenbed" 3 "Init" ;
VAL_ 1124 PSD_Sys_Alter_Karte 0 "kleiner_1_Jahr" 1 "1_Jahr" 2 "2_Jahre" 3 "3_Jahre" 4 "4_Jahre" 5 "5_Jahre" 6 "6_Jahre" 7 "groesser_7_Jahre" ;
VAL_ 1124 PSD_Ges_Spur_Geschw_Begrenzung 0 "Gebot_fuer_alle_spuren_gueltig" ;
VAL_ 1124 PSD_Steigung_1_B_Steigung 126 "mehr_als_15_Prozent" 127 "Steigung_unbekannt" ;
VAL_ 1124 PSD_Attribut_4_ID 0 "keine_Information" ;
VAL_ 1124 PSD_Sys_Zielfuehrung 0 "Zielfuehrung nicht aktiv" 1 "Zielfuehrung aktiv" ;
VAL_ 1124 PSD_Sys_US_State 0 "kein_US_State" 1 "Alabama" 2 "Alaska" 3 "Arkansas" 4 "Arizona" 5 "California" 6 "Colorado" 7 "Conneticut" 8 "District_of_Columbia" 9 "Delaware" 10 "Florida" 11 "Georgia" 12 "Hawaii" 13 "Idaho" 14 "Illinois" 15 "Iowa" 16 "Indiana" 17 "Kansas" 18 "Kentucky" 19 "Louisiana" 20 "Massachusetts" 21 "Maryland" 22 "Maine" 23 "Michigan" 24 "Minnesota" 25 "Missouri" 26 "Mississippi" 27 "Montana" 28 "North_Carolina" 29 "North_Dakota" 30 "Nebraska" 31 "Nevada" 32 "New_Hampshire" 33 "New_Jersey" 34 "New_Mexico" 35 "New_York" 36 "Ohio" 37 "Oklahoma" 38 "Oregon" 39 "Pennsylvania" 40 "Puerto_Rico" 41 "Rhode_Island" 42 "South_Carolina" 43 "South_Dakota" 44 "Tennessee" 45 "Texas" 46 "Utah" 47 "Virginia" 48 "Virgin_Islands" 49 "Vermont" 50 "Washington" 51 "Wisconsin" 52 "West_Virginia" 53 "Wyoming" ;
VAL_ 1124 PSD_Ges_Geschwindigkeit_Gespann 0 "alle Fahrzeuge" 1 "PKW mit Gespann" 2 "LKW, Busse, etc." ;
VAL_ 1124 PSD_Baum_Breite_VZ 0 "Nord" 1 "Sued" ;
VAL_ 1124 PSD_Ges_Geschwindigkeit_Witter 0 "Witterungsunabhängig" 1 "Nässe, Regen, Niederschlag" 2 "Glätte" 3 "Nebel" ;
VAL_ 1124 PSD_Steigung_1_B_Vorz 0 "Gefaelle" 1 "Steigung" ;
VAL_ 1124 PSD_Ges_Geschwindigkeit_Tag_Anf 0 "kein Beginn definiert" 1 "Montag" 2 "Dienstag" 3 "Mittwoch" 4 "Donnerstag" 5 "Freitag" 6 "Samstag" 7 "Sonntag" ;
VAL_ 1124 PSD_Ges_Geschwindigkeit_Tag_Ende 0 "kein Ende definiert" 1 "Montag" 2 "Dienstag" 3 "Mittwoch" 4 "Donnerstag" 5 "Freitag" 6 "Samstag" 7 "Sonntag" ;
VAL_ 1124 PSD_Sys_Quali_verfuegbar 0 "Qualitaetskriterien_nicht_verfuegbar" 1 "Qualitaetskriterien_verfuegbar" ;
VAL_ 1124 PSD_Sys_Zielfuehrung_geaendert 0 "Zielfuehrung_nicht_geaendert" 1 "Zielfuehrung_geaendert" ;
VAL_ 1124 PSD_Ges_Geschwindigkeit_Std_Anf 25 "kein Beginn für stundenweise Einschränkungen" ;
VAL_ 1124 PSD_Steigung_1_Attribute_kompl 0 "Steigungen_nicht_komplett" 1 "Steigungen_komplett" ;
VAL_ 1124 PSD_Sys_Geometrieguete_erweitert 0 "Init" ;
VAL_ 1124 PSD_Steigung_2_Segment_ID 0 "keine_Segment_Information_vorhanden" 1 "Fehler" ;
VAL_ 1124 PSD_Attribut_5_ID 0 "keine_Information" ;
VAL_ 1124 PSD_Ges_Geschwindigkeit_Std_Ende 25 "kein Ende für stundenweise Einschränkungen" ;
VAL_ 1124 PSD_Steigung_2_Steigung 126 "mehr_als_15_Prozent" 127 "Steigung_unbekannt" ;
VAL_ 1124 PSD_Ges_Ueberholverbot 0 "kein Überholverbot" 1 "alle Fahrzeuge" 2 "Überholverbot für PKW mit Gespann" 3 "Überholverbot für LKW, Busse, etc." ;
VAL_ 1124 PSD_Ges_Wechselverkehrszeichen 0 "Kein Wechselverkehrszeichen" 1 "Wechselverkehrszeichen links" 2 "Wechselverkehrszeichen rechts" 3 "Wechselverkehrszeichen links und rechts" 4 "Wechselverkerhszeichen über der Fahrbahn" ;
VAL_ 1124 PSD_Steigung_2_Vorz 0 "Gefaelle" 1 "Steigung" ;
VAL_ 1124 PSD_Wechselverkehrszeichen_Typ 0 "kein_Wechselverkehrszeichen" 1 "LED_Wechselverkehrszeichen" 2 "nicht_LED_Wechselverkehrszeichen" ;
VAL_ 1124 PSD_Ges_Gesetzlich_Kategorie 0 "kein_legales_Verbot" 1 "innerorts" 2 "ausserorts" 3 "Autobahn" ;
VAL_ 1124 PSD_Attribute_Komplett_06 0 "Attribute_nicht_komplett" 1 "Attribute_komplett" ;
VAL_ 1124 PSD_Ges_Gesetzlich_Zusatz 0 "kein_Zusatz_zu_legalem_Gebot" 1 "Anhaenger_Klasse_1" 2 "Anhaenger_Klasse_2" ;
VAL_ 1124 PSD_Ges_Verkehrszeichen_Quelle 0 "VZA_kein_Onlinedienst" 1 "nur_VZA" 2 "nur_VZO" 3 "VZA_und_VZO" ;
VAL_ 1124 PSD_Steigung_2_Attribute_kompl 0 "Steigungen_nicht_komplett" 1 "Steigungen_komplett" ;
VAL_ 1124 PSD_Ges_Attribute_Komplett 0 "Attribute_nicht_komplett" 1 "Attribute_komplett" ;
VAL_ 1023 Quersperre_Anz_Sperre_Einlegen 0 "Quersperre_nicht_einlegen" 1 "Quersperre_einlegen" ;
VAL_ 1023 Quersperre_Anz_Sperre_Auslegen 0 "Quersperre_nicht_auslegen" 1 "Quersperre_auslegen" ;
VAL_ 1023 Quersperre_Anz_Sperre_Geschl 0 "Quersperre_nicht_eingelegt" 1 "Sperre_eingelegt" ;
VAL_ 1023 Quersperre_Status 0 "Sperre_offen" 1 "Sperre_geschlossen" 2 "Fehler_Sperre_offen" 3 "Fehler_Sperre_geschlossen" ;
VAL_ 1023 Quersperre_Istzustand 0 "Init" 1 "geschlossen" 2 "offen" 7 "Fehler" ;
VAL_ 1529 RDK_FMVSS138_Lampe 0 "RDK_WaLa_inaktiv" 1 "RDK_WaLa_aktiv" ;
VAL_ 1529 RDK_FMVSS138_MIL 0 "keine_Stoerungsanzeige" 1 "Stoerungsanzeige" ;
VAL_ 1529 RDK_Kalibrierung 0 "BAP_Kalibrierung" 1 "CAN_Kombitaster_Kalibrierung" ;
VAL_ 1529 RDK_Reifendruck_Lampe 0 "RDK_WaLa_inaktiv" 1 "RDK_WaLa_aktiv" ;
VAL_ 1529 RDK_Warnungen_02 0 "keine_Anzeige" 1 "Reifen_allgemein_Warnstufe_1" 2 "Reifen_vorne_links_Warnstufe_1" 3 "Reifen_vorne_rechts_Warnstufe_1" 4 "Reifen_hinten_links_Warnstufe_1" 5 "Reifen_hinten_rechts_Warnstufe_1" 6 "Reifen_allgemein_Warnstufe_2" 7 "Reifen_vorne_links_Warnstufe_2" 8 "Reifen_vorne_rechts_Warnstufe_2" 9 "Reifen_hinten_links_Warnstufe_2" 10 "Reifen_hinten_rechts_Warnstufe_2" 11 "Reifen_allgemein_Warnstufe_3" 12 "Reifen_vorne_links_Warnstufe_3" 13 "Reifen_vorne_rechts_Warnstufe_3" 14 "Reifen_hinten_links_Warnstufe_3" 15 "Reifen_hinten_rechts_Warnstufe_3" 16 "Akustikausgabe_Kalibrierung_io" 17 "Textausgabe_Kalibrierung_io" 18 "Akustik_Textausgabe_Kalibrier_io" 19 "RDK_aktiviert" 20 "RDK_deaktiviert" 21 "RDK_Systemstoerung" 22 "RDK_Systemstoerung_temporaer" 23 "V_Warnschwelle_1" 24 "V_Warnschwelle_2" 25 "Radwechsel_allgemein" 26 "Teilueberwachung" 27 "V_Warnschwelle_3" 28 "V_Warnschwelle_4" 29 "V_Warnschwelle_5" 30 "Reifendruecke_kalibrieren" ;
VAL_ 1529 RDK_angelernt 0 "nicht_angelernt" 1 "angelernt" ;
VAL_ 1529 RDK_Reifentemperatur_Lampe 0 "RDK_WaLa_inaktiv" 1 "RDK_WaLa_aktiv" ;
VAL_ 1529 RDK_RS_aktiv 0 "inaktiv" 1 "aktiv" ;
VAL_ 1529 RDK_Text_7 0 "inaktiv" 1 "aktiv" ;
VAL_ 1529 RDK_W_1_Reifen_HL 0 "inaktiv" 1 "aktiv" ;
VAL_ 1529 RDK_W_1_Reifen_HR 0 "inaktiv" 1 "aktiv" ;
VAL_ 1529 RDK_W_1_Reifen_VL 0 "inaktiv" 1 "aktiv" ;
VAL_ 1529 RDK_W_1_Reifen_VR 0 "inaktiv" 1 "aktiv" ;
VAL_ 1529 RDK_W_2_Reifen_HL 0 "inaktiv" 1 "aktiv" ;
VAL_ 1529 RDK_W_2_Reifen_HR 0 "inaktiv" 1 "aktiv" ;
VAL_ 1529 RDK_W_2_Reifen_VL 0 "inaktiv" 1 "aktiv" ;
VAL_ 1529 RDK_W_2_Reifen_VR 0 "inaktiv" 1 "aktiv" ;
